VERSION ""

NS_ :

BS_:

BU_: BMU_ID_0 BMU_ID_1 BMU_ID_2 BMU_ID_3 BMU_ID_4 BMU_ID_5 BMU_ID_6 BMU_ID_7 BMU_ID_8 BMU_ID_9 BMU_ID_10 BMU_ID_11 BMU_ID_12 BMU_ID_13 BMU_ID_14 BMU_ID_15

BO_ 1365 wBMU_ID_5_msg_05_warnings: 8 BMU_ID_5
 SG_ System_errors : 0|1@1+ (1,0) [0|0] ""  BMU_ID_0
 SG_ Architecture_configuration_error : 1|1@1+ (1,0) [0|0] ""  BMU_ID_0
 SG_ Parallelization_voltage_errors : 2|1@1+ (1,0) [0|0] ""  BMU_ID_0
 SG_ General_configuration_errors : 3|1@1+ (1,0) [0|0] ""  BMU_ID_0
 SG_ Parallelization_comm_lost_primar : 4|1@1+ (1,0) [0|0] ""  BMU_ID_0
 SG_ Cell_overvoltage : 5|1@1+ (1,0) [0|0] ""  BMU_ID_0
 SG_ Cell_undervoltage : 6|1@1+ (1,0) [0|0] ""  BMU_ID_0
 SG_ Comm_failure_with_CMU : 7|1@1+ (1,0) [0|0] ""  BMU_ID_0
 SG_ Internal_CMU_error : 8|1@1+ (1,0) [0|0] ""  BMU_ID_0
 SG_ Internal_CMU_temperature_error : 9|1@1+ (1,0) [0|0] ""  BMU_ID_0
 SG_ Internal_CMU_voltage_reference : 10|1@1+ (1,0) [0|0] ""  BMU_ID_0
 SG_ Cell_shortcircuit : 11|1@1+ (1,0) [0|0] ""  BMU_ID_0
 SG_ Battery_overcurrent : 12|1@1+ (1,0) [0|0] ""  BMU_ID_0
 SG_ Overload_ratio_exceeded : 13|1@1+ (1,0) [0|0] ""  BMU_ID_0
 SG_ Current_sensor_errors : 14|1@1+ (1,0) [0|0] ""  BMU_ID_0
 SG_ BMU_temperature_errors : 15|1@1+ (1,0) [0|0] ""  BMU_ID_0
 SG_ Cell_overtemperature : 16|1@1+ (1,0) [0|0] ""  BMU_ID_0
 SG_ Cell_undertemperature : 17|1@1+ (1,0) [0|0] ""  BMU_ID_0
 SG_ Balancing_overtemperature : 18|1@1+ (1,0) [0|0] ""  BMU_ID_0
 SG_ Balancing_undertemperature : 19|1@1+ (1,0) [0|0] ""  BMU_ID_0
 SG_ Max_op_cell_temp_delta : 20|1@1+ (1,0) [0|0] ""  BMU_ID_0
 SG_ Thermal_runaway : 21|1@1+ (1,0) [0|0] ""  BMU_ID_0
 SG_ OW_and_SC_detected_on_cell : 22|1@1+ (1,0) [0|0] ""  BMU_ID_0
 SG_ BMU_external_overtemperature : 23|1@1+ (1,0) [0|0] ""  BMU_ID_0
 SG_ Battery_undervoltage : 24|1@1+ (1,0) [0|0] ""  BMU_ID_0
 SG_ BMU_supply_voltage_error : 25|1@1+ (1,0) [0|0] ""  BMU_ID_0
 SG_ Battery_overvoltage : 26|1@1+ (1,0) [0|0] ""  BMU_ID_0
 SG_ Cells_unbalanced : 27|1@1+ (1,0) [0|0] ""  BMU_ID_0
 SG_ Advanced_relaxation_voltage_delt : 28|1@1+ (1,0) [0|0] ""  BMU_ID_0
 SG_ Internal_BMU_error : 30|1@1+ (1,0) [0|0] ""  BMU_ID_0
 SG_ Safety_sensor_error : 31|1@1+ (1,0) [0|0] ""  BMU_ID_0
 SG_ High_voltage_sensor_errors : 32|1@1+ (1,0) [0|0] ""  BMU_ID_0
 SG_ IMD_errors : 33|1@1+ (1,0) [0|0] ""  BMU_ID_0
 SG_ Isolation_error : 34|1@1+ (1,0) [0|0] ""  BMU_ID_0
 SG_ BMU_SoC_errors : 35|1@1+ (1,0) [0|0] ""  BMU_ID_0
 SG_ BMU_SoH_error : 36|1@1+ (1,0) [0|0] ""  BMU_ID_0
 SG_ Contactor_stuck_open_errors : 37|1@1+ (1,0) [0|0] ""  BMU_ID_0
 SG_ Contactor_stuck_closed_errors : 38|1@1+ (1,0) [0|0] ""  BMU_ID_0
 SG_ Contactor_supply_error : 39|1@1+ (1,0) [0|0] ""  BMU_ID_0
 SG_ Contactor_precharge_error : 40|1@1+ (1,0) [0|0] ""  BMU_ID_0
 SG_ Emergency_button_error : 41|1@1+ (1,0) [0|0] ""  BMU_ID_0
 SG_ Actuation_errors : 42|1@1+ (1,0) [0|0] ""  BMU_ID_0
 SG_ Auto_OFF : 43|1@1+ (1,0) [0|0] ""  BMU_ID_0
 SG_ Mode_mismatch : 44|1@1+ (1,0) [0|0] ""  BMU_ID_0
 SG_ Open_wire_errors : 45|1@1+ (1,0) [0|0] ""  BMU_ID_0
 SG_ Output_driver_errors_diagnostics : 46|1@1+ (1,0) [0|0] ""  BMU_ID_0
 SG_ User_forced_errors : 47|1@1+ (1,0) [0|0] ""  BMU_ID_0
 SG_ SD_error : 48|1@1+ (1,0) [0|0] ""  BMU_ID_0
 SG_ Ethernet_module_error : 49|1@1+ (1,0) [0|0] ""  BMU_ID_0
 SG_ Internal_memory_errors : 29|1@1+ (1,0) [0|0] ""  BMU_ID_0

BO_ 1366 wBMU_ID_6_msg_05_warnings: 8 BMU_ID_6
 SG_ System_errors : 0|1@1+ (1,0) [0|0] ""  BMU_ID_0
 SG_ Architecture_configuration_error : 1|1@1+ (1,0) [0|0] ""  BMU_ID_0
 SG_ Parallelization_voltage_errors : 2|1@1+ (1,0) [0|0] ""  BMU_ID_0
 SG_ General_configuration_errors : 3|1@1+ (1,0) [0|0] ""  BMU_ID_0
 SG_ Parallelization_comm_lost_primar : 4|1@1+ (1,0) [0|0] ""  BMU_ID_0
 SG_ Cell_overvoltage : 5|1@1+ (1,0) [0|0] ""  BMU_ID_0
 SG_ Cell_undervoltage : 6|1@1+ (1,0) [0|0] ""  BMU_ID_0
 SG_ Comm_failure_with_CMU : 7|1@1+ (1,0) [0|0] ""  BMU_ID_0
 SG_ Internal_CMU_error : 8|1@1+ (1,0) [0|0] ""  BMU_ID_0
 SG_ Internal_CMU_temperature_error : 9|1@1+ (1,0) [0|0] ""  BMU_ID_0
 SG_ Internal_CMU_voltage_reference : 10|1@1+ (1,0) [0|0] ""  BMU_ID_0
 SG_ Cell_shortcircuit : 11|1@1+ (1,0) [0|0] ""  BMU_ID_0
 SG_ Battery_overcurrent : 12|1@1+ (1,0) [0|0] ""  BMU_ID_0
 SG_ Overload_ratio_exceeded : 13|1@1+ (1,0) [0|0] ""  BMU_ID_0
 SG_ Current_sensor_errors : 14|1@1+ (1,0) [0|0] ""  BMU_ID_0
 SG_ BMU_temperature_errors : 15|1@1+ (1,0) [0|0] ""  BMU_ID_0
 SG_ Cell_overtemperature : 16|1@1+ (1,0) [0|0] ""  BMU_ID_0
 SG_ Cell_undertemperature : 17|1@1+ (1,0) [0|0] ""  BMU_ID_0
 SG_ Balancing_overtemperature : 18|1@1+ (1,0) [0|0] ""  BMU_ID_0
 SG_ Balancing_undertemperature : 19|1@1+ (1,0) [0|0] ""  BMU_ID_0
 SG_ Max_op_cell_temp_delta : 20|1@1+ (1,0) [0|0] ""  BMU_ID_0
 SG_ Thermal_runaway : 21|1@1+ (1,0) [0|0] ""  BMU_ID_0
 SG_ OW_and_SC_detected_on_cell : 22|1@1+ (1,0) [0|0] ""  BMU_ID_0
 SG_ BMU_external_overtemperature : 23|1@1+ (1,0) [0|0] ""  BMU_ID_0
 SG_ Battery_undervoltage : 24|1@1+ (1,0) [0|0] ""  BMU_ID_0
 SG_ BMU_supply_voltage_error : 25|1@1+ (1,0) [0|0] ""  BMU_ID_0
 SG_ Battery_overvoltage : 26|1@1+ (1,0) [0|0] ""  BMU_ID_0
 SG_ Cells_unbalanced : 27|1@1+ (1,0) [0|0] ""  BMU_ID_0
 SG_ Advanced_relaxation_voltage_delt : 28|1@1+ (1,0) [0|0] ""  BMU_ID_0
 SG_ Internal_BMU_error : 30|1@1+ (1,0) [0|0] ""  BMU_ID_0
 SG_ Safety_sensor_error : 31|1@1+ (1,0) [0|0] ""  BMU_ID_0
 SG_ High_voltage_sensor_errors : 32|1@1+ (1,0) [0|0] ""  BMU_ID_0
 SG_ IMD_errors : 33|1@1+ (1,0) [0|0] ""  BMU_ID_0
 SG_ Isolation_error : 34|1@1+ (1,0) [0|0] ""  BMU_ID_0
 SG_ BMU_SoC_errors : 35|1@1+ (1,0) [0|0] ""  BMU_ID_0
 SG_ BMU_SoH_error : 36|1@1+ (1,0) [0|0] ""  BMU_ID_0
 SG_ Contactor_stuck_open_errors : 37|1@1+ (1,0) [0|0] ""  BMU_ID_0
 SG_ Contactor_stuck_closed_errors : 38|1@1+ (1,0) [0|0] ""  BMU_ID_0
 SG_ Contactor_supply_error : 39|1@1+ (1,0) [0|0] ""  BMU_ID_0
 SG_ Contactor_precharge_error : 40|1@1+ (1,0) [0|0] ""  BMU_ID_0
 SG_ Emergency_button_error : 41|1@1+ (1,0) [0|0] ""  BMU_ID_0
 SG_ Actuation_errors : 42|1@1+ (1,0) [0|0] ""  BMU_ID_0
 SG_ Auto_OFF : 43|1@1+ (1,0) [0|0] ""  BMU_ID_0
 SG_ Mode_mismatch : 44|1@1+ (1,0) [0|0] ""  BMU_ID_0
 SG_ Open_wire_errors : 45|1@1+ (1,0) [0|0] ""  BMU_ID_0
 SG_ Output_driver_errors_diagnostics : 46|1@1+ (1,0) [0|0] ""  BMU_ID_0
 SG_ User_forced_errors : 47|1@1+ (1,0) [0|0] ""  BMU_ID_0
 SG_ SD_error : 48|1@1+ (1,0) [0|0] ""  BMU_ID_0
 SG_ Ethernet_module_error : 49|1@1+ (1,0) [0|0] ""  BMU_ID_0
 SG_ Internal_memory_errors : 29|1@1+ (1,0) [0|0] ""  BMU_ID_0

BO_ 1367 wBMU_ID_7_msg_05_warnings: 8 BMU_ID_7
 SG_ System_errors : 0|1@1+ (1,0) [0|0] ""  BMU_ID_0
 SG_ Architecture_configuration_error : 1|1@1+ (1,0) [0|0] ""  BMU_ID_0
 SG_ Parallelization_voltage_errors : 2|1@1+ (1,0) [0|0] ""  BMU_ID_0
 SG_ General_configuration_errors : 3|1@1+ (1,0) [0|0] ""  BMU_ID_0
 SG_ Parallelization_comm_lost_primar : 4|1@1+ (1,0) [0|0] ""  BMU_ID_0
 SG_ Cell_overvoltage : 5|1@1+ (1,0) [0|0] ""  BMU_ID_0
 SG_ Cell_undervoltage : 6|1@1+ (1,0) [0|0] ""  BMU_ID_0
 SG_ Comm_failure_with_CMU : 7|1@1+ (1,0) [0|0] ""  BMU_ID_0
 SG_ Internal_CMU_error : 8|1@1+ (1,0) [0|0] ""  BMU_ID_0
 SG_ Internal_CMU_temperature_error : 9|1@1+ (1,0) [0|0] ""  BMU_ID_0
 SG_ Internal_CMU_voltage_reference : 10|1@1+ (1,0) [0|0] ""  BMU_ID_0
 SG_ Cell_shortcircuit : 11|1@1+ (1,0) [0|0] ""  BMU_ID_0
 SG_ Battery_overcurrent : 12|1@1+ (1,0) [0|0] ""  BMU_ID_0
 SG_ Overload_ratio_exceeded : 13|1@1+ (1,0) [0|0] ""  BMU_ID_0
 SG_ Current_sensor_errors : 14|1@1+ (1,0) [0|0] ""  BMU_ID_0
 SG_ BMU_temperature_errors : 15|1@1+ (1,0) [0|0] ""  BMU_ID_0
 SG_ Cell_overtemperature : 16|1@1+ (1,0) [0|0] ""  BMU_ID_0
 SG_ Cell_undertemperature : 17|1@1+ (1,0) [0|0] ""  BMU_ID_0
 SG_ Balancing_overtemperature : 18|1@1+ (1,0) [0|0] ""  BMU_ID_0
 SG_ Balancing_undertemperature : 19|1@1+ (1,0) [0|0] ""  BMU_ID_0
 SG_ Max_op_cell_temp_delta : 20|1@1+ (1,0) [0|0] ""  BMU_ID_0
 SG_ Thermal_runaway : 21|1@1+ (1,0) [0|0] ""  BMU_ID_0
 SG_ OW_and_SC_detected_on_cell : 22|1@1+ (1,0) [0|0] ""  BMU_ID_0
 SG_ BMU_external_overtemperature : 23|1@1+ (1,0) [0|0] ""  BMU_ID_0
 SG_ Battery_undervoltage : 24|1@1+ (1,0) [0|0] ""  BMU_ID_0
 SG_ BMU_supply_voltage_error : 25|1@1+ (1,0) [0|0] ""  BMU_ID_0
 SG_ Battery_overvoltage : 26|1@1+ (1,0) [0|0] ""  BMU_ID_0
 SG_ Cells_unbalanced : 27|1@1+ (1,0) [0|0] ""  BMU_ID_0
 SG_ Advanced_relaxation_voltage_delt : 28|1@1+ (1,0) [0|0] ""  BMU_ID_0
 SG_ Internal_BMU_error : 30|1@1+ (1,0) [0|0] ""  BMU_ID_0
 SG_ Safety_sensor_error : 31|1@1+ (1,0) [0|0] ""  BMU_ID_0
 SG_ High_voltage_sensor_errors : 32|1@1+ (1,0) [0|0] ""  BMU_ID_0
 SG_ IMD_errors : 33|1@1+ (1,0) [0|0] ""  BMU_ID_0
 SG_ Isolation_error : 34|1@1+ (1,0) [0|0] ""  BMU_ID_0
 SG_ BMU_SoC_errors : 35|1@1+ (1,0) [0|0] ""  BMU_ID_0
 SG_ BMU_SoH_error : 36|1@1+ (1,0) [0|0] ""  BMU_ID_0
 SG_ Contactor_stuck_open_errors : 37|1@1+ (1,0) [0|0] ""  BMU_ID_0
 SG_ Contactor_stuck_closed_errors : 38|1@1+ (1,0) [0|0] ""  BMU_ID_0
 SG_ Contactor_supply_error : 39|1@1+ (1,0) [0|0] ""  BMU_ID_0
 SG_ Contactor_precharge_error : 40|1@1+ (1,0) [0|0] ""  BMU_ID_0
 SG_ Emergency_button_error : 41|1@1+ (1,0) [0|0] ""  BMU_ID_0
 SG_ Actuation_errors : 42|1@1+ (1,0) [0|0] ""  BMU_ID_0
 SG_ Auto_OFF : 43|1@1+ (1,0) [0|0] ""  BMU_ID_0
 SG_ Mode_mismatch : 44|1@1+ (1,0) [0|0] ""  BMU_ID_0
 SG_ Open_wire_errors : 45|1@1+ (1,0) [0|0] ""  BMU_ID_0
 SG_ Output_driver_errors_diagnostics : 46|1@1+ (1,0) [0|0] ""  BMU_ID_0
 SG_ User_forced_errors : 47|1@1+ (1,0) [0|0] ""  BMU_ID_0
 SG_ SD_error : 48|1@1+ (1,0) [0|0] ""  BMU_ID_0
 SG_ Ethernet_module_error : 49|1@1+ (1,0) [0|0] ""  BMU_ID_0
 SG_ Internal_memory_errors : 29|1@1+ (1,0) [0|0] ""  BMU_ID_0

BO_ 1368 wBMU_ID_8_msg_05_warnings: 8 BMU_ID_8
 SG_ System_errors : 0|1@1+ (1,0) [0|0] ""  BMU_ID_0
 SG_ Architecture_configuration_error : 1|1@1+ (1,0) [0|0] ""  BMU_ID_0
 SG_ Parallelization_voltage_errors : 2|1@1+ (1,0) [0|0] ""  BMU_ID_0
 SG_ General_configuration_errors : 3|1@1+ (1,0) [0|0] ""  BMU_ID_0
 SG_ Parallelization_comm_lost_primar : 4|1@1+ (1,0) [0|0] ""  BMU_ID_0
 SG_ Cell_overvoltage : 5|1@1+ (1,0) [0|0] ""  BMU_ID_0
 SG_ Cell_undervoltage : 6|1@1+ (1,0) [0|0] ""  BMU_ID_0
 SG_ Comm_failure_with_CMU : 7|1@1+ (1,0) [0|0] ""  BMU_ID_0
 SG_ Internal_CMU_error : 8|1@1+ (1,0) [0|0] ""  BMU_ID_0
 SG_ Internal_CMU_temperature_error : 9|1@1+ (1,0) [0|0] ""  BMU_ID_0
 SG_ Internal_CMU_voltage_reference : 10|1@1+ (1,0) [0|0] ""  BMU_ID_0
 SG_ Cell_shortcircuit : 11|1@1+ (1,0) [0|0] ""  BMU_ID_0
 SG_ Battery_overcurrent : 12|1@1+ (1,0) [0|0] ""  BMU_ID_0
 SG_ Overload_ratio_exceeded : 13|1@1+ (1,0) [0|0] ""  BMU_ID_0
 SG_ Current_sensor_errors : 14|1@1+ (1,0) [0|0] ""  BMU_ID_0
 SG_ BMU_temperature_errors : 15|1@1+ (1,0) [0|0] ""  BMU_ID_0
 SG_ Cell_overtemperature : 16|1@1+ (1,0) [0|0] ""  BMU_ID_0
 SG_ Cell_undertemperature : 17|1@1+ (1,0) [0|0] ""  BMU_ID_0
 SG_ Balancing_overtemperature : 18|1@1+ (1,0) [0|0] ""  BMU_ID_0
 SG_ Balancing_undertemperature : 19|1@1+ (1,0) [0|0] ""  BMU_ID_0
 SG_ Max_op_cell_temp_delta : 20|1@1+ (1,0) [0|0] ""  BMU_ID_0
 SG_ Thermal_runaway : 21|1@1+ (1,0) [0|0] ""  BMU_ID_0
 SG_ OW_and_SC_detected_on_cell : 22|1@1+ (1,0) [0|0] ""  BMU_ID_0
 SG_ BMU_external_overtemperature : 23|1@1+ (1,0) [0|0] ""  BMU_ID_0
 SG_ Battery_undervoltage : 24|1@1+ (1,0) [0|0] ""  BMU_ID_0
 SG_ BMU_supply_voltage_error : 25|1@1+ (1,0) [0|0] ""  BMU_ID_0
 SG_ Battery_overvoltage : 26|1@1+ (1,0) [0|0] ""  BMU_ID_0
 SG_ Cells_unbalanced : 27|1@1+ (1,0) [0|0] ""  BMU_ID_0
 SG_ Advanced_relaxation_voltage_delt : 28|1@1+ (1,0) [0|0] ""  BMU_ID_0
 SG_ Internal_BMU_error : 30|1@1+ (1,0) [0|0] ""  BMU_ID_0
 SG_ Safety_sensor_error : 31|1@1+ (1,0) [0|0] ""  BMU_ID_0
 SG_ High_voltage_sensor_errors : 32|1@1+ (1,0) [0|0] ""  BMU_ID_0
 SG_ IMD_errors : 33|1@1+ (1,0) [0|0] ""  BMU_ID_0
 SG_ Isolation_error : 34|1@1+ (1,0) [0|0] ""  BMU_ID_0
 SG_ BMU_SoC_errors : 35|1@1+ (1,0) [0|0] ""  BMU_ID_0
 SG_ BMU_SoH_error : 36|1@1+ (1,0) [0|0] ""  BMU_ID_0
 SG_ Contactor_stuck_open_errors : 37|1@1+ (1,0) [0|0] ""  BMU_ID_0
 SG_ Contactor_stuck_closed_errors : 38|1@1+ (1,0) [0|0] ""  BMU_ID_0
 SG_ Contactor_supply_error : 39|1@1+ (1,0) [0|0] ""  BMU_ID_0
 SG_ Contactor_precharge_error : 40|1@1+ (1,0) [0|0] ""  BMU_ID_0
 SG_ Emergency_button_error : 41|1@1+ (1,0) [0|0] ""  BMU_ID_0
 SG_ Actuation_errors : 42|1@1+ (1,0) [0|0] ""  BMU_ID_0
 SG_ Auto_OFF : 43|1@1+ (1,0) [0|0] ""  BMU_ID_0
 SG_ Mode_mismatch : 44|1@1+ (1,0) [0|0] ""  BMU_ID_0
 SG_ Open_wire_errors : 45|1@1+ (1,0) [0|0] ""  BMU_ID_0
 SG_ Output_driver_errors_diagnostics : 46|1@1+ (1,0) [0|0] ""  BMU_ID_0
 SG_ User_forced_errors : 47|1@1+ (1,0) [0|0] ""  BMU_ID_0
 SG_ SD_error : 48|1@1+ (1,0) [0|0] ""  BMU_ID_0
 SG_ Ethernet_module_error : 49|1@1+ (1,0) [0|0] ""  BMU_ID_0
 SG_ Internal_memory_errors : 29|1@1+ (1,0) [0|0] ""  BMU_ID_0

BO_ 1369 wBMU_ID_9_msg_05_warnings: 8 BMU_ID_9
 SG_ System_errors : 0|1@1+ (1,0) [0|0] ""  BMU_ID_0
 SG_ Architecture_configuration_error : 1|1@1+ (1,0) [0|0] ""  BMU_ID_0
 SG_ Parallelization_voltage_errors : 2|1@1+ (1,0) [0|0] ""  BMU_ID_0
 SG_ General_configuration_errors : 3|1@1+ (1,0) [0|0] ""  BMU_ID_0
 SG_ Parallelization_comm_lost_primar : 4|1@1+ (1,0) [0|0] ""  BMU_ID_0
 SG_ Cell_overvoltage : 5|1@1+ (1,0) [0|0] ""  BMU_ID_0
 SG_ Cell_undervoltage : 6|1@1+ (1,0) [0|0] ""  BMU_ID_0
 SG_ Comm_failure_with_CMU : 7|1@1+ (1,0) [0|0] ""  BMU_ID_0
 SG_ Internal_CMU_error : 8|1@1+ (1,0) [0|0] ""  BMU_ID_0
 SG_ Internal_CMU_temperature_error : 9|1@1+ (1,0) [0|0] ""  BMU_ID_0
 SG_ Internal_CMU_voltage_reference : 10|1@1+ (1,0) [0|0] ""  BMU_ID_0
 SG_ Cell_shortcircuit : 11|1@1+ (1,0) [0|0] ""  BMU_ID_0
 SG_ Battery_overcurrent : 12|1@1+ (1,0) [0|0] ""  BMU_ID_0
 SG_ Overload_ratio_exceeded : 13|1@1+ (1,0) [0|0] ""  BMU_ID_0
 SG_ Current_sensor_errors : 14|1@1+ (1,0) [0|0] ""  BMU_ID_0
 SG_ BMU_temperature_errors : 15|1@1+ (1,0) [0|0] ""  BMU_ID_0
 SG_ Cell_overtemperature : 16|1@1+ (1,0) [0|0] ""  BMU_ID_0
 SG_ Cell_undertemperature : 17|1@1+ (1,0) [0|0] ""  BMU_ID_0
 SG_ Balancing_overtemperature : 18|1@1+ (1,0) [0|0] ""  BMU_ID_0
 SG_ Balancing_undertemperature : 19|1@1+ (1,0) [0|0] ""  BMU_ID_0
 SG_ Max_op_cell_temp_delta : 20|1@1+ (1,0) [0|0] ""  BMU_ID_0
 SG_ Thermal_runaway : 21|1@1+ (1,0) [0|0] ""  BMU_ID_0
 SG_ OW_and_SC_detected_on_cell : 22|1@1+ (1,0) [0|0] ""  BMU_ID_0
 SG_ BMU_external_overtemperature : 23|1@1+ (1,0) [0|0] ""  BMU_ID_0
 SG_ Battery_undervoltage : 24|1@1+ (1,0) [0|0] ""  BMU_ID_0
 SG_ BMU_supply_voltage_error : 25|1@1+ (1,0) [0|0] ""  BMU_ID_0
 SG_ Battery_overvoltage : 26|1@1+ (1,0) [0|0] ""  BMU_ID_0
 SG_ Cells_unbalanced : 27|1@1+ (1,0) [0|0] ""  BMU_ID_0
 SG_ Advanced_relaxation_voltage_delt : 28|1@1+ (1,0) [0|0] ""  BMU_ID_0
 SG_ Internal_BMU_error : 30|1@1+ (1,0) [0|0] ""  BMU_ID_0
 SG_ Safety_sensor_error : 31|1@1+ (1,0) [0|0] ""  BMU_ID_0
 SG_ High_voltage_sensor_errors : 32|1@1+ (1,0) [0|0] ""  BMU_ID_0
 SG_ IMD_errors : 33|1@1+ (1,0) [0|0] ""  BMU_ID_0
 SG_ Isolation_error : 34|1@1+ (1,0) [0|0] ""  BMU_ID_0
 SG_ BMU_SoC_errors : 35|1@1+ (1,0) [0|0] ""  BMU_ID_0
 SG_ BMU_SoH_error : 36|1@1+ (1,0) [0|0] ""  BMU_ID_0
 SG_ Contactor_stuck_open_errors : 37|1@1+ (1,0) [0|0] ""  BMU_ID_0
 SG_ Contactor_stuck_closed_errors : 38|1@1+ (1,0) [0|0] ""  BMU_ID_0
 SG_ Contactor_supply_error : 39|1@1+ (1,0) [0|0] ""  BMU_ID_0
 SG_ Contactor_precharge_error : 40|1@1+ (1,0) [0|0] ""  BMU_ID_0
 SG_ Emergency_button_error : 41|1@1+ (1,0) [0|0] ""  BMU_ID_0
 SG_ Actuation_errors : 42|1@1+ (1,0) [0|0] ""  BMU_ID_0
 SG_ Auto_OFF : 43|1@1+ (1,0) [0|0] ""  BMU_ID_0
 SG_ Mode_mismatch : 44|1@1+ (1,0) [0|0] ""  BMU_ID_0
 SG_ Open_wire_errors : 45|1@1+ (1,0) [0|0] ""  BMU_ID_0
 SG_ Output_driver_errors_diagnostics : 46|1@1+ (1,0) [0|0] ""  BMU_ID_0
 SG_ User_forced_errors : 47|1@1+ (1,0) [0|0] ""  BMU_ID_0
 SG_ SD_error : 48|1@1+ (1,0) [0|0] ""  BMU_ID_0
 SG_ Ethernet_module_error : 49|1@1+ (1,0) [0|0] ""  BMU_ID_0
 SG_ Internal_memory_errors : 29|1@1+ (1,0) [0|0] ""  BMU_ID_0

BO_ 1370 wBMU_ID_10_msg_05_warnings: 8 BMU_ID_10
 SG_ System_errors : 0|1@1+ (1,0) [0|0] ""  BMU_ID_0
 SG_ Architecture_configuration_error : 1|1@1+ (1,0) [0|0] ""  BMU_ID_0
 SG_ Parallelization_voltage_errors : 2|1@1+ (1,0) [0|0] ""  BMU_ID_0
 SG_ General_configuration_errors : 3|1@1+ (1,0) [0|0] ""  BMU_ID_0
 SG_ Parallelization_comm_lost_primar : 4|1@1+ (1,0) [0|0] ""  BMU_ID_0
 SG_ Cell_overvoltage : 5|1@1+ (1,0) [0|0] ""  BMU_ID_0
 SG_ Cell_undervoltage : 6|1@1+ (1,0) [0|0] ""  BMU_ID_0
 SG_ Comm_failure_with_CMU : 7|1@1+ (1,0) [0|0] ""  BMU_ID_0
 SG_ Internal_CMU_error : 8|1@1+ (1,0) [0|0] ""  BMU_ID_0
 SG_ Internal_CMU_temperature_error : 9|1@1+ (1,0) [0|0] ""  BMU_ID_0
 SG_ Internal_CMU_voltage_reference : 10|1@1+ (1,0) [0|0] ""  BMU_ID_0
 SG_ Cell_shortcircuit : 11|1@1+ (1,0) [0|0] ""  BMU_ID_0
 SG_ Battery_overcurrent : 12|1@1+ (1,0) [0|0] ""  BMU_ID_0
 SG_ Overload_ratio_exceeded : 13|1@1+ (1,0) [0|0] ""  BMU_ID_0
 SG_ Current_sensor_errors : 14|1@1+ (1,0) [0|0] ""  BMU_ID_0
 SG_ BMU_temperature_errors : 15|1@1+ (1,0) [0|0] ""  BMU_ID_0
 SG_ Cell_overtemperature : 16|1@1+ (1,0) [0|0] ""  BMU_ID_0
 SG_ Cell_undertemperature : 17|1@1+ (1,0) [0|0] ""  BMU_ID_0
 SG_ Balancing_overtemperature : 18|1@1+ (1,0) [0|0] ""  BMU_ID_0
 SG_ Balancing_undertemperature : 19|1@1+ (1,0) [0|0] ""  BMU_ID_0
 SG_ Max_op_cell_temp_delta : 20|1@1+ (1,0) [0|0] ""  BMU_ID_0
 SG_ Thermal_runaway : 21|1@1+ (1,0) [0|0] ""  BMU_ID_0
 SG_ OW_and_SC_detected_on_cell : 22|1@1+ (1,0) [0|0] ""  BMU_ID_0
 SG_ BMU_external_overtemperature : 23|1@1+ (1,0) [0|0] ""  BMU_ID_0
 SG_ Battery_undervoltage : 24|1@1+ (1,0) [0|0] ""  BMU_ID_0
 SG_ BMU_supply_voltage_error : 25|1@1+ (1,0) [0|0] ""  BMU_ID_0
 SG_ Battery_overvoltage : 26|1@1+ (1,0) [0|0] ""  BMU_ID_0
 SG_ Cells_unbalanced : 27|1@1+ (1,0) [0|0] ""  BMU_ID_0
 SG_ Advanced_relaxation_voltage_delt : 28|1@1+ (1,0) [0|0] ""  BMU_ID_0
 SG_ Internal_BMU_error : 30|1@1+ (1,0) [0|0] ""  BMU_ID_0
 SG_ Safety_sensor_error : 31|1@1+ (1,0) [0|0] ""  BMU_ID_0
 SG_ High_voltage_sensor_errors : 32|1@1+ (1,0) [0|0] ""  BMU_ID_0
 SG_ IMD_errors : 33|1@1+ (1,0) [0|0] ""  BMU_ID_0
 SG_ Isolation_error : 34|1@1+ (1,0) [0|0] ""  BMU_ID_0
 SG_ BMU_SoC_errors : 35|1@1+ (1,0) [0|0] ""  BMU_ID_0
 SG_ BMU_SoH_error : 36|1@1+ (1,0) [0|0] ""  BMU_ID_0
 SG_ Contactor_stuck_open_errors : 37|1@1+ (1,0) [0|0] ""  BMU_ID_0
 SG_ Contactor_stuck_closed_errors : 38|1@1+ (1,0) [0|0] ""  BMU_ID_0
 SG_ Contactor_supply_error : 39|1@1+ (1,0) [0|0] ""  BMU_ID_0
 SG_ Contactor_precharge_error : 40|1@1+ (1,0) [0|0] ""  BMU_ID_0
 SG_ Emergency_button_error : 41|1@1+ (1,0) [0|0] ""  BMU_ID_0
 SG_ Actuation_errors : 42|1@1+ (1,0) [0|0] ""  BMU_ID_0
 SG_ Auto_OFF : 43|1@1+ (1,0) [0|0] ""  BMU_ID_0
 SG_ Mode_mismatch : 44|1@1+ (1,0) [0|0] ""  BMU_ID_0
 SG_ Open_wire_errors : 45|1@1+ (1,0) [0|0] ""  BMU_ID_0
 SG_ Output_driver_errors_diagnostics : 46|1@1+ (1,0) [0|0] ""  BMU_ID_0
 SG_ User_forced_errors : 47|1@1+ (1,0) [0|0] ""  BMU_ID_0
 SG_ SD_error : 48|1@1+ (1,0) [0|0] ""  BMU_ID_0
 SG_ Ethernet_module_error : 49|1@1+ (1,0) [0|0] ""  BMU_ID_0
 SG_ Internal_memory_errors : 29|1@1+ (1,0) [0|0] ""  BMU_ID_0

BO_ 1371 wBMU_ID_11_msg_05_warnings: 8 BMU_ID_11
 SG_ System_errors : 0|1@1+ (1,0) [0|0] ""  BMU_ID_0
 SG_ Architecture_configuration_error : 1|1@1+ (1,0) [0|0] ""  BMU_ID_0
 SG_ Parallelization_voltage_errors : 2|1@1+ (1,0) [0|0] ""  BMU_ID_0
 SG_ General_configuration_errors : 3|1@1+ (1,0) [0|0] ""  BMU_ID_0
 SG_ Parallelization_comm_lost_primar : 4|1@1+ (1,0) [0|0] ""  BMU_ID_0
 SG_ Cell_overvoltage : 5|1@1+ (1,0) [0|0] ""  BMU_ID_0
 SG_ Cell_undervoltage : 6|1@1+ (1,0) [0|0] ""  BMU_ID_0
 SG_ Comm_failure_with_CMU : 7|1@1+ (1,0) [0|0] ""  BMU_ID_0
 SG_ Internal_CMU_error : 8|1@1+ (1,0) [0|0] ""  BMU_ID_0
 SG_ Internal_CMU_temperature_error : 9|1@1+ (1,0) [0|0] ""  BMU_ID_0
 SG_ Internal_CMU_voltage_reference : 10|1@1+ (1,0) [0|0] ""  BMU_ID_0
 SG_ Cell_shortcircuit : 11|1@1+ (1,0) [0|0] ""  BMU_ID_0
 SG_ Battery_overcurrent : 12|1@1+ (1,0) [0|0] ""  BMU_ID_0
 SG_ Overload_ratio_exceeded : 13|1@1+ (1,0) [0|0] ""  BMU_ID_0
 SG_ Current_sensor_errors : 14|1@1+ (1,0) [0|0] ""  BMU_ID_0
 SG_ BMU_temperature_errors : 15|1@1+ (1,0) [0|0] ""  BMU_ID_0
 SG_ Cell_overtemperature : 16|1@1+ (1,0) [0|0] ""  BMU_ID_0
 SG_ Cell_undertemperature : 17|1@1+ (1,0) [0|0] ""  BMU_ID_0
 SG_ Balancing_overtemperature : 18|1@1+ (1,0) [0|0] ""  BMU_ID_0
 SG_ Balancing_undertemperature : 19|1@1+ (1,0) [0|0] ""  BMU_ID_0
 SG_ Max_op_cell_temp_delta : 20|1@1+ (1,0) [0|0] ""  BMU_ID_0
 SG_ Thermal_runaway : 21|1@1+ (1,0) [0|0] ""  BMU_ID_0
 SG_ OW_and_SC_detected_on_cell : 22|1@1+ (1,0) [0|0] ""  BMU_ID_0
 SG_ BMU_external_overtemperature : 23|1@1+ (1,0) [0|0] ""  BMU_ID_0
 SG_ Battery_undervoltage : 24|1@1+ (1,0) [0|0] ""  BMU_ID_0
 SG_ BMU_supply_voltage_error : 25|1@1+ (1,0) [0|0] ""  BMU_ID_0
 SG_ Battery_overvoltage : 26|1@1+ (1,0) [0|0] ""  BMU_ID_0
 SG_ Cells_unbalanced : 27|1@1+ (1,0) [0|0] ""  BMU_ID_0
 SG_ Advanced_relaxation_voltage_delt : 28|1@1+ (1,0) [0|0] ""  BMU_ID_0
 SG_ Internal_BMU_error : 30|1@1+ (1,0) [0|0] ""  BMU_ID_0
 SG_ Safety_sensor_error : 31|1@1+ (1,0) [0|0] ""  BMU_ID_0
 SG_ High_voltage_sensor_errors : 32|1@1+ (1,0) [0|0] ""  BMU_ID_0
 SG_ IMD_errors : 33|1@1+ (1,0) [0|0] ""  BMU_ID_0
 SG_ Isolation_error : 34|1@1+ (1,0) [0|0] ""  BMU_ID_0
 SG_ BMU_SoC_errors : 35|1@1+ (1,0) [0|0] ""  BMU_ID_0
 SG_ BMU_SoH_error : 36|1@1+ (1,0) [0|0] ""  BMU_ID_0
 SG_ Contactor_stuck_open_errors : 37|1@1+ (1,0) [0|0] ""  BMU_ID_0
 SG_ Contactor_stuck_closed_errors : 38|1@1+ (1,0) [0|0] ""  BMU_ID_0
 SG_ Contactor_supply_error : 39|1@1+ (1,0) [0|0] ""  BMU_ID_0
 SG_ Contactor_precharge_error : 40|1@1+ (1,0) [0|0] ""  BMU_ID_0
 SG_ Emergency_button_error : 41|1@1+ (1,0) [0|0] ""  BMU_ID_0
 SG_ Actuation_errors : 42|1@1+ (1,0) [0|0] ""  BMU_ID_0
 SG_ Auto_OFF : 43|1@1+ (1,0) [0|0] ""  BMU_ID_0
 SG_ Mode_mismatch : 44|1@1+ (1,0) [0|0] ""  BMU_ID_0
 SG_ Open_wire_errors : 45|1@1+ (1,0) [0|0] ""  BMU_ID_0
 SG_ Output_driver_errors_diagnostics : 46|1@1+ (1,0) [0|0] ""  BMU_ID_0
 SG_ User_forced_errors : 47|1@1+ (1,0) [0|0] ""  BMU_ID_0
 SG_ SD_error : 48|1@1+ (1,0) [0|0] ""  BMU_ID_0
 SG_ Ethernet_module_error : 49|1@1+ (1,0) [0|0] ""  BMU_ID_0
 SG_ Internal_memory_errors : 29|1@1+ (1,0) [0|0] ""  BMU_ID_0

BO_ 1372 wBMU_ID_12_msg_05_warnings: 8 BMU_ID_12
 SG_ System_errors : 0|1@1+ (1,0) [0|0] ""  BMU_ID_0
 SG_ Architecture_configuration_error : 1|1@1+ (1,0) [0|0] ""  BMU_ID_0
 SG_ Parallelization_voltage_errors : 2|1@1+ (1,0) [0|0] ""  BMU_ID_0
 SG_ General_configuration_errors : 3|1@1+ (1,0) [0|0] ""  BMU_ID_0
 SG_ Parallelization_comm_lost_primar : 4|1@1+ (1,0) [0|0] ""  BMU_ID_0
 SG_ Cell_overvoltage : 5|1@1+ (1,0) [0|0] ""  BMU_ID_0
 SG_ Cell_undervoltage : 6|1@1+ (1,0) [0|0] ""  BMU_ID_0
 SG_ Comm_failure_with_CMU : 7|1@1+ (1,0) [0|0] ""  BMU_ID_0
 SG_ Internal_CMU_error : 8|1@1+ (1,0) [0|0] ""  BMU_ID_0
 SG_ Internal_CMU_temperature_error : 9|1@1+ (1,0) [0|0] ""  BMU_ID_0
 SG_ Internal_CMU_voltage_reference : 10|1@1+ (1,0) [0|0] ""  BMU_ID_0
 SG_ Cell_shortcircuit : 11|1@1+ (1,0) [0|0] ""  BMU_ID_0
 SG_ Battery_overcurrent : 12|1@1+ (1,0) [0|0] ""  BMU_ID_0
 SG_ Overload_ratio_exceeded : 13|1@1+ (1,0) [0|0] ""  BMU_ID_0
 SG_ Current_sensor_errors : 14|1@1+ (1,0) [0|0] ""  BMU_ID_0
 SG_ BMU_temperature_errors : 15|1@1+ (1,0) [0|0] ""  BMU_ID_0
 SG_ Cell_overtemperature : 16|1@1+ (1,0) [0|0] ""  BMU_ID_0
 SG_ Cell_undertemperature : 17|1@1+ (1,0) [0|0] ""  BMU_ID_0
 SG_ Balancing_overtemperature : 18|1@1+ (1,0) [0|0] ""  BMU_ID_0
 SG_ Balancing_undertemperature : 19|1@1+ (1,0) [0|0] ""  BMU_ID_0
 SG_ Max_op_cell_temp_delta : 20|1@1+ (1,0) [0|0] ""  BMU_ID_0
 SG_ Thermal_runaway : 21|1@1+ (1,0) [0|0] ""  BMU_ID_0
 SG_ OW_and_SC_detected_on_cell : 22|1@1+ (1,0) [0|0] ""  BMU_ID_0
 SG_ BMU_external_overtemperature : 23|1@1+ (1,0) [0|0] ""  BMU_ID_0
 SG_ Battery_undervoltage : 24|1@1+ (1,0) [0|0] ""  BMU_ID_0
 SG_ BMU_supply_voltage_error : 25|1@1+ (1,0) [0|0] ""  BMU_ID_0
 SG_ Battery_overvoltage : 26|1@1+ (1,0) [0|0] ""  BMU_ID_0
 SG_ Cells_unbalanced : 27|1@1+ (1,0) [0|0] ""  BMU_ID_0
 SG_ Advanced_relaxation_voltage_delt : 28|1@1+ (1,0) [0|0] ""  BMU_ID_0
 SG_ Internal_BMU_error : 30|1@1+ (1,0) [0|0] ""  BMU_ID_0
 SG_ Safety_sensor_error : 31|1@1+ (1,0) [0|0] ""  BMU_ID_0
 SG_ High_voltage_sensor_errors : 32|1@1+ (1,0) [0|0] ""  BMU_ID_0
 SG_ IMD_errors : 33|1@1+ (1,0) [0|0] ""  BMU_ID_0
 SG_ Isolation_error : 34|1@1+ (1,0) [0|0] ""  BMU_ID_0
 SG_ BMU_SoC_errors : 35|1@1+ (1,0) [0|0] ""  BMU_ID_0
 SG_ BMU_SoH_error : 36|1@1+ (1,0) [0|0] ""  BMU_ID_0
 SG_ Contactor_stuck_open_errors : 37|1@1+ (1,0) [0|0] ""  BMU_ID_0
 SG_ Contactor_stuck_closed_errors : 38|1@1+ (1,0) [0|0] ""  BMU_ID_0
 SG_ Contactor_supply_error : 39|1@1+ (1,0) [0|0] ""  BMU_ID_0
 SG_ Contactor_precharge_error : 40|1@1+ (1,0) [0|0] ""  BMU_ID_0
 SG_ Emergency_button_error : 41|1@1+ (1,0) [0|0] ""  BMU_ID_0
 SG_ Actuation_errors : 42|1@1+ (1,0) [0|0] ""  BMU_ID_0
 SG_ Auto_OFF : 43|1@1+ (1,0) [0|0] ""  BMU_ID_0
 SG_ Mode_mismatch : 44|1@1+ (1,0) [0|0] ""  BMU_ID_0
 SG_ Open_wire_errors : 45|1@1+ (1,0) [0|0] ""  BMU_ID_0
 SG_ Output_driver_errors_diagnostics : 46|1@1+ (1,0) [0|0] ""  BMU_ID_0
 SG_ User_forced_errors : 47|1@1+ (1,0) [0|0] ""  BMU_ID_0
 SG_ SD_error : 48|1@1+ (1,0) [0|0] ""  BMU_ID_0
 SG_ Ethernet_module_error : 49|1@1+ (1,0) [0|0] ""  BMU_ID_0
 SG_ Internal_memory_errors : 29|1@1+ (1,0) [0|0] ""  BMU_ID_0

BO_ 1373 wBMU_ID_13_msg_05_warnings: 8 BMU_ID_13
 SG_ System_errors : 0|1@1+ (1,0) [0|0] ""  BMU_ID_0
 SG_ Architecture_configuration_error : 1|1@1+ (1,0) [0|0] ""  BMU_ID_0
 SG_ Parallelization_voltage_errors : 2|1@1+ (1,0) [0|0] ""  BMU_ID_0
 SG_ General_configuration_errors : 3|1@1+ (1,0) [0|0] ""  BMU_ID_0
 SG_ Parallelization_comm_lost_primar : 4|1@1+ (1,0) [0|0] ""  BMU_ID_0
 SG_ Cell_overvoltage : 5|1@1+ (1,0) [0|0] ""  BMU_ID_0
 SG_ Cell_undervoltage : 6|1@1+ (1,0) [0|0] ""  BMU_ID_0
 SG_ Comm_failure_with_CMU : 7|1@1+ (1,0) [0|0] ""  BMU_ID_0
 SG_ Internal_CMU_error : 8|1@1+ (1,0) [0|0] ""  BMU_ID_0
 SG_ Internal_CMU_temperature_error : 9|1@1+ (1,0) [0|0] ""  BMU_ID_0
 SG_ Internal_CMU_voltage_reference : 10|1@1+ (1,0) [0|0] ""  BMU_ID_0
 SG_ Cell_shortcircuit : 11|1@1+ (1,0) [0|0] ""  BMU_ID_0
 SG_ Battery_overcurrent : 12|1@1+ (1,0) [0|0] ""  BMU_ID_0
 SG_ Overload_ratio_exceeded : 13|1@1+ (1,0) [0|0] ""  BMU_ID_0
 SG_ Current_sensor_errors : 14|1@1+ (1,0) [0|0] ""  BMU_ID_0
 SG_ BMU_temperature_errors : 15|1@1+ (1,0) [0|0] ""  BMU_ID_0
 SG_ Cell_overtemperature : 16|1@1+ (1,0) [0|0] ""  BMU_ID_0
 SG_ Cell_undertemperature : 17|1@1+ (1,0) [0|0] ""  BMU_ID_0
 SG_ Balancing_overtemperature : 18|1@1+ (1,0) [0|0] ""  BMU_ID_0
 SG_ Balancing_undertemperature : 19|1@1+ (1,0) [0|0] ""  BMU_ID_0
 SG_ Max_op_cell_temp_delta : 20|1@1+ (1,0) [0|0] ""  BMU_ID_0
 SG_ Thermal_runaway : 21|1@1+ (1,0) [0|0] ""  BMU_ID_0
 SG_ OW_and_SC_detected_on_cell : 22|1@1+ (1,0) [0|0] ""  BMU_ID_0
 SG_ BMU_external_overtemperature : 23|1@1+ (1,0) [0|0] ""  BMU_ID_0
 SG_ Battery_undervoltage : 24|1@1+ (1,0) [0|0] ""  BMU_ID_0
 SG_ BMU_supply_voltage_error : 25|1@1+ (1,0) [0|0] ""  BMU_ID_0
 SG_ Battery_overvoltage : 26|1@1+ (1,0) [0|0] ""  BMU_ID_0
 SG_ Cells_unbalanced : 27|1@1+ (1,0) [0|0] ""  BMU_ID_0
 SG_ Advanced_relaxation_voltage_delt : 28|1@1+ (1,0) [0|0] ""  BMU_ID_0
 SG_ Internal_BMU_error : 30|1@1+ (1,0) [0|0] ""  BMU_ID_0
 SG_ Safety_sensor_error : 31|1@1+ (1,0) [0|0] ""  BMU_ID_0
 SG_ High_voltage_sensor_errors : 32|1@1+ (1,0) [0|0] ""  BMU_ID_0
 SG_ IMD_errors : 33|1@1+ (1,0) [0|0] ""  BMU_ID_0
 SG_ Isolation_error : 34|1@1+ (1,0) [0|0] ""  BMU_ID_0
 SG_ BMU_SoC_errors : 35|1@1+ (1,0) [0|0] ""  BMU_ID_0
 SG_ BMU_SoH_error : 36|1@1+ (1,0) [0|0] ""  BMU_ID_0
 SG_ Contactor_stuck_open_errors : 37|1@1+ (1,0) [0|0] ""  BMU_ID_0
 SG_ Contactor_stuck_closed_errors : 38|1@1+ (1,0) [0|0] ""  BMU_ID_0
 SG_ Contactor_supply_error : 39|1@1+ (1,0) [0|0] ""  BMU_ID_0
 SG_ Contactor_precharge_error : 40|1@1+ (1,0) [0|0] ""  BMU_ID_0
 SG_ Emergency_button_error : 41|1@1+ (1,0) [0|0] ""  BMU_ID_0
 SG_ Actuation_errors : 42|1@1+ (1,0) [0|0] ""  BMU_ID_0
 SG_ Auto_OFF : 43|1@1+ (1,0) [0|0] ""  BMU_ID_0
 SG_ Mode_mismatch : 44|1@1+ (1,0) [0|0] ""  BMU_ID_0
 SG_ Open_wire_errors : 45|1@1+ (1,0) [0|0] ""  BMU_ID_0
 SG_ Output_driver_errors_diagnostics : 46|1@1+ (1,0) [0|0] ""  BMU_ID_0
 SG_ User_forced_errors : 47|1@1+ (1,0) [0|0] ""  BMU_ID_0
 SG_ SD_error : 48|1@1+ (1,0) [0|0] ""  BMU_ID_0
 SG_ Ethernet_module_error : 49|1@1+ (1,0) [0|0] ""  BMU_ID_0
 SG_ Internal_memory_errors : 29|1@1+ (1,0) [0|0] ""  BMU_ID_0

BO_ 1374 wBMU_ID_14_msg_05_warnings: 8 BMU_ID_14
 SG_ System_errors : 0|1@1+ (1,0) [0|0] ""  BMU_ID_0
 SG_ Architecture_configuration_error : 1|1@1+ (1,0) [0|0] ""  BMU_ID_0
 SG_ Parallelization_voltage_errors : 2|1@1+ (1,0) [0|0] ""  BMU_ID_0
 SG_ General_configuration_errors : 3|1@1+ (1,0) [0|0] ""  BMU_ID_0
 SG_ Parallelization_comm_lost_primar : 4|1@1+ (1,0) [0|0] ""  BMU_ID_0
 SG_ Cell_overvoltage : 5|1@1+ (1,0) [0|0] ""  BMU_ID_0
 SG_ Cell_undervoltage : 6|1@1+ (1,0) [0|0] ""  BMU_ID_0
 SG_ Comm_failure_with_CMU : 7|1@1+ (1,0) [0|0] ""  BMU_ID_0
 SG_ Internal_CMU_error : 8|1@1+ (1,0) [0|0] ""  BMU_ID_0
 SG_ Internal_CMU_temperature_error : 9|1@1+ (1,0) [0|0] ""  BMU_ID_0
 SG_ Internal_CMU_voltage_reference : 10|1@1+ (1,0) [0|0] ""  BMU_ID_0
 SG_ Cell_shortcircuit : 11|1@1+ (1,0) [0|0] ""  BMU_ID_0
 SG_ Battery_overcurrent : 12|1@1+ (1,0) [0|0] ""  BMU_ID_0
 SG_ Overload_ratio_exceeded : 13|1@1+ (1,0) [0|0] ""  BMU_ID_0
 SG_ Current_sensor_errors : 14|1@1+ (1,0) [0|0] ""  BMU_ID_0
 SG_ BMU_temperature_errors : 15|1@1+ (1,0) [0|0] ""  BMU_ID_0
 SG_ Cell_overtemperature : 16|1@1+ (1,0) [0|0] ""  BMU_ID_0
 SG_ Cell_undertemperature : 17|1@1+ (1,0) [0|0] ""  BMU_ID_0
 SG_ Balancing_overtemperature : 18|1@1+ (1,0) [0|0] ""  BMU_ID_0
 SG_ Balancing_undertemperature : 19|1@1+ (1,0) [0|0] ""  BMU_ID_0
 SG_ Max_op_cell_temp_delta : 20|1@1+ (1,0) [0|0] ""  BMU_ID_0
 SG_ Thermal_runaway : 21|1@1+ (1,0) [0|0] ""  BMU_ID_0
 SG_ OW_and_SC_detected_on_cell : 22|1@1+ (1,0) [0|0] ""  BMU_ID_0
 SG_ BMU_external_overtemperature : 23|1@1+ (1,0) [0|0] ""  BMU_ID_0
 SG_ Battery_undervoltage : 24|1@1+ (1,0) [0|0] ""  BMU_ID_0
 SG_ BMU_supply_voltage_error : 25|1@1+ (1,0) [0|0] ""  BMU_ID_0
 SG_ Battery_overvoltage : 26|1@1+ (1,0) [0|0] ""  BMU_ID_0
 SG_ Cells_unbalanced : 27|1@1+ (1,0) [0|0] ""  BMU_ID_0
 SG_ Advanced_relaxation_voltage_delt : 28|1@1+ (1,0) [0|0] ""  BMU_ID_0
 SG_ Internal_BMU_error : 30|1@1+ (1,0) [0|0] ""  BMU_ID_0
 SG_ Safety_sensor_error : 31|1@1+ (1,0) [0|0] ""  BMU_ID_0
 SG_ High_voltage_sensor_errors : 32|1@1+ (1,0) [0|0] ""  BMU_ID_0
 SG_ IMD_errors : 33|1@1+ (1,0) [0|0] ""  BMU_ID_0
 SG_ Isolation_error : 34|1@1+ (1,0) [0|0] ""  BMU_ID_0
 SG_ BMU_SoC_errors : 35|1@1+ (1,0) [0|0] ""  BMU_ID_0
 SG_ BMU_SoH_error : 36|1@1+ (1,0) [0|0] ""  BMU_ID_0
 SG_ Contactor_stuck_open_errors : 37|1@1+ (1,0) [0|0] ""  BMU_ID_0
 SG_ Contactor_stuck_closed_errors : 38|1@1+ (1,0) [0|0] ""  BMU_ID_0
 SG_ Contactor_supply_error : 39|1@1+ (1,0) [0|0] ""  BMU_ID_0
 SG_ Contactor_precharge_error : 40|1@1+ (1,0) [0|0] ""  BMU_ID_0
 SG_ Emergency_button_error : 41|1@1+ (1,0) [0|0] ""  BMU_ID_0
 SG_ Actuation_errors : 42|1@1+ (1,0) [0|0] ""  BMU_ID_0
 SG_ Auto_OFF : 43|1@1+ (1,0) [0|0] ""  BMU_ID_0
 SG_ Mode_mismatch : 44|1@1+ (1,0) [0|0] ""  BMU_ID_0
 SG_ Open_wire_errors : 45|1@1+ (1,0) [0|0] ""  BMU_ID_0
 SG_ Output_driver_errors_diagnostics : 46|1@1+ (1,0) [0|0] ""  BMU_ID_0
 SG_ User_forced_errors : 47|1@1+ (1,0) [0|0] ""  BMU_ID_0
 SG_ SD_error : 48|1@1+ (1,0) [0|0] ""  BMU_ID_0
 SG_ Ethernet_module_error : 49|1@1+ (1,0) [0|0] ""  BMU_ID_0
 SG_ Internal_memory_errors : 29|1@1+ (1,0) [0|0] ""  BMU_ID_0

BO_ 1375 wBMU_ID_15_msg_05_warnings: 8 BMU_ID_15
 SG_ System_errors : 0|1@1+ (1,0) [0|0] ""  BMU_ID_0
 SG_ Architecture_configuration_error : 1|1@1+ (1,0) [0|0] ""  BMU_ID_0
 SG_ Parallelization_voltage_errors : 2|1@1+ (1,0) [0|0] ""  BMU_ID_0
 SG_ General_configuration_errors : 3|1@1+ (1,0) [0|0] ""  BMU_ID_0
 SG_ Parallelization_comm_lost_primar : 4|1@1+ (1,0) [0|0] ""  BMU_ID_0
 SG_ Cell_overvoltage : 5|1@1+ (1,0) [0|0] ""  BMU_ID_0
 SG_ Cell_undervoltage : 6|1@1+ (1,0) [0|0] ""  BMU_ID_0
 SG_ Comm_failure_with_CMU : 7|1@1+ (1,0) [0|0] ""  BMU_ID_0
 SG_ Internal_CMU_error : 8|1@1+ (1,0) [0|0] ""  BMU_ID_0
 SG_ Internal_CMU_temperature_error : 9|1@1+ (1,0) [0|0] ""  BMU_ID_0
 SG_ Internal_CMU_voltage_reference : 10|1@1+ (1,0) [0|0] ""  BMU_ID_0
 SG_ Cell_shortcircuit : 11|1@1+ (1,0) [0|0] ""  BMU_ID_0
 SG_ Battery_overcurrent : 12|1@1+ (1,0) [0|0] ""  BMU_ID_0
 SG_ Overload_ratio_exceeded : 13|1@1+ (1,0) [0|0] ""  BMU_ID_0
 SG_ Current_sensor_errors : 14|1@1+ (1,0) [0|0] ""  BMU_ID_0
 SG_ BMU_temperature_errors : 15|1@1+ (1,0) [0|0] ""  BMU_ID_0
 SG_ Cell_overtemperature : 16|1@1+ (1,0) [0|0] ""  BMU_ID_0
 SG_ Cell_undertemperature : 17|1@1+ (1,0) [0|0] ""  BMU_ID_0
 SG_ Balancing_overtemperature : 18|1@1+ (1,0) [0|0] ""  BMU_ID_0
 SG_ Balancing_undertemperature : 19|1@1+ (1,0) [0|0] ""  BMU_ID_0
 SG_ Max_op_cell_temp_delta : 20|1@1+ (1,0) [0|0] ""  BMU_ID_0
 SG_ Thermal_runaway : 21|1@1+ (1,0) [0|0] ""  BMU_ID_0
 SG_ OW_and_SC_detected_on_cell : 22|1@1+ (1,0) [0|0] ""  BMU_ID_0
 SG_ BMU_external_overtemperature : 23|1@1+ (1,0) [0|0] ""  BMU_ID_0
 SG_ Battery_undervoltage : 24|1@1+ (1,0) [0|0] ""  BMU_ID_0
 SG_ BMU_supply_voltage_error : 25|1@1+ (1,0) [0|0] ""  BMU_ID_0
 SG_ Battery_overvoltage : 26|1@1+ (1,0) [0|0] ""  BMU_ID_0
 SG_ Cells_unbalanced : 27|1@1+ (1,0) [0|0] ""  BMU_ID_0
 SG_ Advanced_relaxation_voltage_delt : 28|1@1+ (1,0) [0|0] ""  BMU_ID_0
 SG_ Internal_BMU_error : 30|1@1+ (1,0) [0|0] ""  BMU_ID_0
 SG_ Safety_sensor_error : 31|1@1+ (1,0) [0|0] ""  BMU_ID_0
 SG_ High_voltage_sensor_errors : 32|1@1+ (1,0) [0|0] ""  BMU_ID_0
 SG_ IMD_errors : 33|1@1+ (1,0) [0|0] ""  BMU_ID_0
 SG_ Isolation_error : 34|1@1+ (1,0) [0|0] ""  BMU_ID_0
 SG_ BMU_SoC_errors : 35|1@1+ (1,0) [0|0] ""  BMU_ID_0
 SG_ BMU_SoH_error : 36|1@1+ (1,0) [0|0] ""  BMU_ID_0
 SG_ Contactor_stuck_open_errors : 37|1@1+ (1,0) [0|0] ""  BMU_ID_0
 SG_ Contactor_stuck_closed_errors : 38|1@1+ (1,0) [0|0] ""  BMU_ID_0
 SG_ Contactor_supply_error : 39|1@1+ (1,0) [0|0] ""  BMU_ID_0
 SG_ Contactor_precharge_error : 40|1@1+ (1,0) [0|0] ""  BMU_ID_0
 SG_ Emergency_button_error : 41|1@1+ (1,0) [0|0] ""  BMU_ID_0
 SG_ Actuation_errors : 42|1@1+ (1,0) [0|0] ""  BMU_ID_0
 SG_ Auto_OFF : 43|1@1+ (1,0) [0|0] ""  BMU_ID_0
 SG_ Mode_mismatch : 44|1@1+ (1,0) [0|0] ""  BMU_ID_0
 SG_ Open_wire_errors : 45|1@1+ (1,0) [0|0] ""  BMU_ID_0
 SG_ Output_driver_errors_diagnostics : 46|1@1+ (1,0) [0|0] ""  BMU_ID_0
 SG_ User_forced_errors : 47|1@1+ (1,0) [0|0] ""  BMU_ID_0
 SG_ SD_error : 48|1@1+ (1,0) [0|0] ""  BMU_ID_0
 SG_ Ethernet_module_error : 49|1@1+ (1,0) [0|0] ""  BMU_ID_0
 SG_ Internal_memory_errors : 29|1@1+ (1,0) [0|0] ""  BMU_ID_0

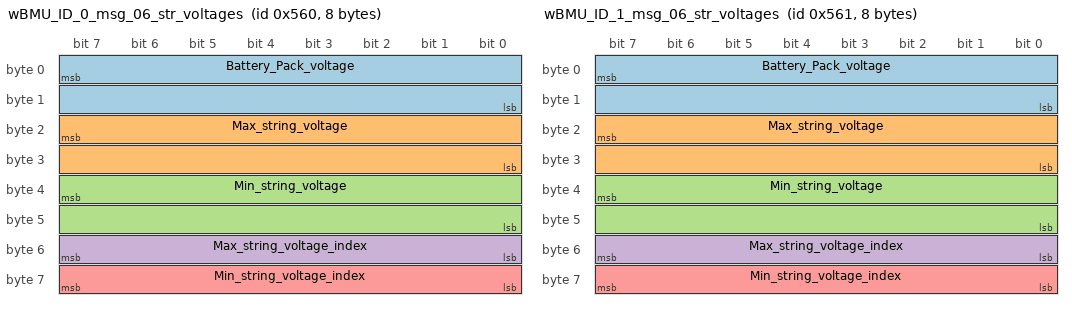
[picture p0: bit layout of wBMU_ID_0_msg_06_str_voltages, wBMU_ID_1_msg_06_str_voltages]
BO_ 1376 wBMU_ID_0_msg_06_str_voltages: 8 BMU_ID_0
 SG_ Battery_Pack_voltage : 7|16@0+ (0.1,0) [0|0] "V"  BMU_ID_0
 SG_ Max_string_voltage : 23|16@0+ (0.1,0) [0|0] "V"  BMU_ID_0
 SG_ Min_string_voltage : 39|16@0+ (0.1,0) [0|0] "V"  BMU_ID_0
 SG_ Max_string_voltage_index : 55|8@0+ (1,0) [0|0] "-"  BMU_ID_0
 SG_ Min_string_voltage_index : 63|8@0+ (1,0) [0|0] "-"  BMU_ID_0

BO_ 1377 wBMU_ID_1_msg_06_str_voltages: 8 BMU_ID_1
 SG_ Battery_Pack_voltage : 7|16@0+ (0.1,0) [0|0] "V"  BMU_ID_1
 SG_ Max_string_voltage : 23|16@0+ (0.1,0) [0|0] "V"  BMU_ID_1
 SG_ Min_string_voltage : 39|16@0+ (0.1,0) [0|0] "V"  BMU_ID_1
 SG_ Max_string_voltage_index : 55|8@0+ (1,0) [0|0] "-"  BMU_ID_1
 SG_ Min_string_voltage_index : 63|8@0+ (1,0) [0|0] "-"  BMU_ID_1

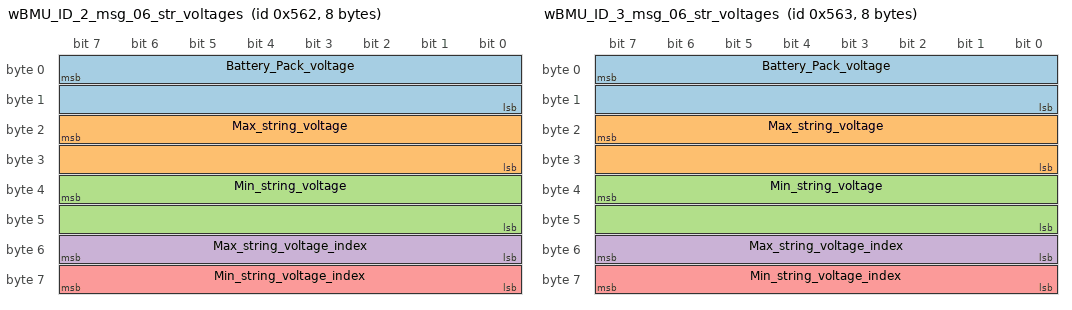
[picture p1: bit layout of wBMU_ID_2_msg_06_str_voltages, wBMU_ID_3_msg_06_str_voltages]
BO_ 1378 wBMU_ID_2_msg_06_str_voltages: 8 BMU_ID_2
 SG_ Battery_Pack_voltage : 7|16@0+ (0.1,0) [0|0] "V"  BMU_ID_2
 SG_ Max_string_voltage : 23|16@0+ (0.1,0) [0|0] "V"  BMU_ID_2
 SG_ Min_string_voltage : 39|16@0+ (0.1,0) [0|0] "V"  BMU_ID_2
 SG_ Max_string_voltage_index : 55|8@0+ (1,0) [0|0] "-"  BMU_ID_2
 SG_ Min_string_voltage_index : 63|8@0+ (1,0) [0|0] "-"  BMU_ID_2

BO_ 1379 wBMU_ID_3_msg_06_str_voltages: 8 BMU_ID_3
 SG_ Battery_Pack_voltage : 7|16@0+ (0.1,0) [0|0] "V"  BMU_ID_3
 SG_ Max_string_voltage : 23|16@0+ (0.1,0) [0|0] "V"  BMU_ID_3
 SG_ Min_string_voltage : 39|16@0+ (0.1,0) [0|0] "V"  BMU_ID_3
 SG_ Max_string_voltage_index : 55|8@0+ (1,0) [0|0] "-"  BMU_ID_3
 SG_ Min_string_voltage_index : 63|8@0+ (1,0) [0|0] "-"  BMU_ID_3

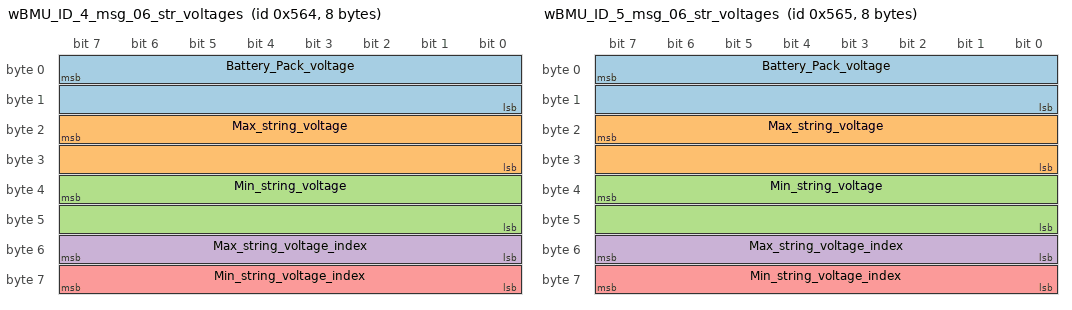
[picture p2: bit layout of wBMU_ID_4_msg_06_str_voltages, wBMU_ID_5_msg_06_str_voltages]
BO_ 1380 wBMU_ID_4_msg_06_str_voltages: 8 BMU_ID_4
 SG_ Battery_Pack_voltage : 7|16@0+ (0.1,0) [0|0] "V"  BMU_ID_4
 SG_ Max_string_voltage : 23|16@0+ (0.1,0) [0|0] "V"  BMU_ID_4
 SG_ Min_string_voltage : 39|16@0+ (0.1,0) [0|0] "V"  BMU_ID_4
 SG_ Max_string_voltage_index : 55|8@0+ (1,0) [0|0] "-"  BMU_ID_4
 SG_ Min_string_voltage_index : 63|8@0+ (1,0) [0|0] "-"  BMU_ID_4

BO_ 1381 wBMU_ID_5_msg_06_str_voltages: 8 BMU_ID_5
 SG_ Battery_Pack_voltage : 7|16@0+ (0.1,0) [0|0] "V"  BMU_ID_5
 SG_ Max_string_voltage : 23|16@0+ (0.1,0) [0|0] "V"  BMU_ID_5
 SG_ Min_string_voltage : 39|16@0+ (0.1,0) [0|0] "V"  BMU_ID_5
 SG_ Max_string_voltage_index : 55|8@0+ (1,0) [0|0] "-"  BMU_ID_5
 SG_ Min_string_voltage_index : 63|8@0+ (1,0) [0|0] "-"  BMU_ID_5

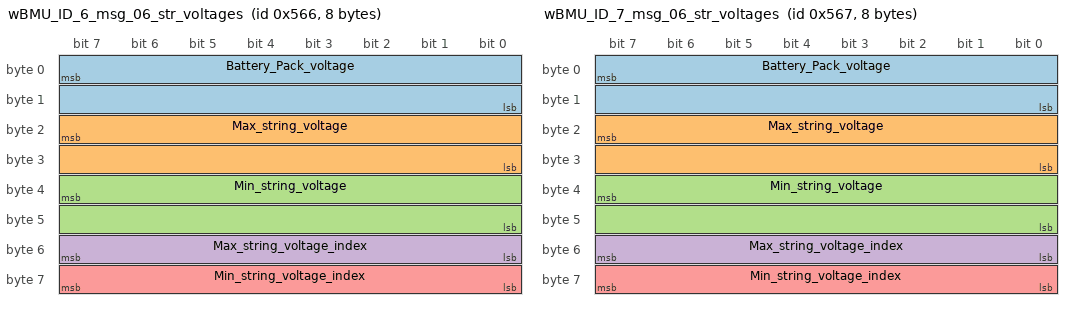
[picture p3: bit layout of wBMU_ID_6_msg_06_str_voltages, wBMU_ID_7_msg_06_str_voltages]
BO_ 1382 wBMU_ID_6_msg_06_str_voltages: 8 BMU_ID_6
 SG_ Battery_Pack_voltage : 7|16@0+ (0.1,0) [0|0] "V"  BMU_ID_6
 SG_ Max_string_voltage : 23|16@0+ (0.1,0) [0|0] "V"  BMU_ID_6
 SG_ Min_string_voltage : 39|16@0+ (0.1,0) [0|0] "V"  BMU_ID_6
 SG_ Max_string_voltage_index : 55|8@0+ (1,0) [0|0] "-"  BMU_ID_6
 SG_ Min_string_voltage_index : 63|8@0+ (1,0) [0|0] "-"  BMU_ID_6

BO_ 1383 wBMU_ID_7_msg_06_str_voltages: 8 BMU_ID_7
 SG_ Battery_Pack_voltage : 7|16@0+ (0.1,0) [0|0] "V"  BMU_ID_7
 SG_ Max_string_voltage : 23|16@0+ (0.1,0) [0|0] "V"  BMU_ID_7
 SG_ Min_string_voltage : 39|16@0+ (0.1,0) [0|0] "V"  BMU_ID_7
 SG_ Max_string_voltage_index : 55|8@0+ (1,0) [0|0] "-"  BMU_ID_7
 SG_ Min_string_voltage_index : 63|8@0+ (1,0) [0|0] "-"  BMU_ID_7

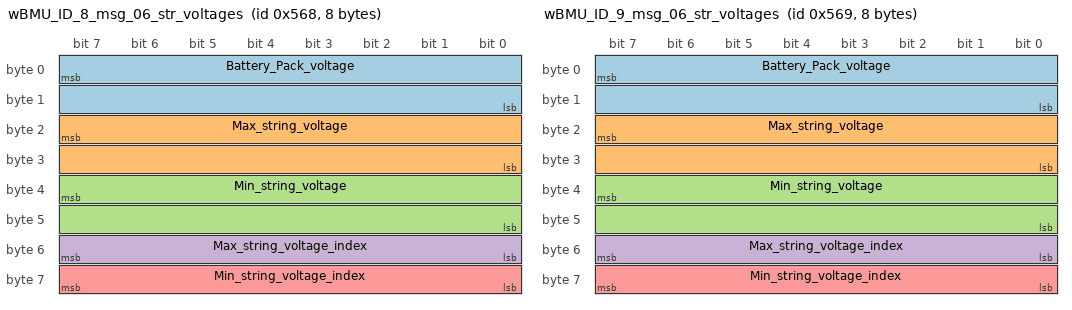
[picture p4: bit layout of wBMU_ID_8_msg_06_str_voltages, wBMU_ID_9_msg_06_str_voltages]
BO_ 1384 wBMU_ID_8_msg_06_str_voltages: 8 BMU_ID_8
 SG_ Battery_Pack_voltage : 7|16@0+ (0.1,0) [0|0] "V"  BMU_ID_8
 SG_ Max_string_voltage : 23|16@0+ (0.1,0) [0|0] "V"  BMU_ID_8
 SG_ Min_string_voltage : 39|16@0+ (0.1,0) [0|0] "V"  BMU_ID_8
 SG_ Max_string_voltage_index : 55|8@0+ (1,0) [0|0] "-"  BMU_ID_8
 SG_ Min_string_voltage_index : 63|8@0+ (1,0) [0|0] "-"  BMU_ID_8

BO_ 1385 wBMU_ID_9_msg_06_str_voltages: 8 BMU_ID_9
 SG_ Battery_Pack_voltage : 7|16@0+ (0.1,0) [0|0] "V"  BMU_ID_9
 SG_ Max_string_voltage : 23|16@0+ (0.1,0) [0|0] "V"  BMU_ID_9
 SG_ Min_string_voltage : 39|16@0+ (0.1,0) [0|0] "V"  BMU_ID_9
 SG_ Max_string_voltage_index : 55|8@0+ (1,0) [0|0] "-"  BMU_ID_9
 SG_ Min_string_voltage_index : 63|8@0+ (1,0) [0|0] "-"  BMU_ID_9

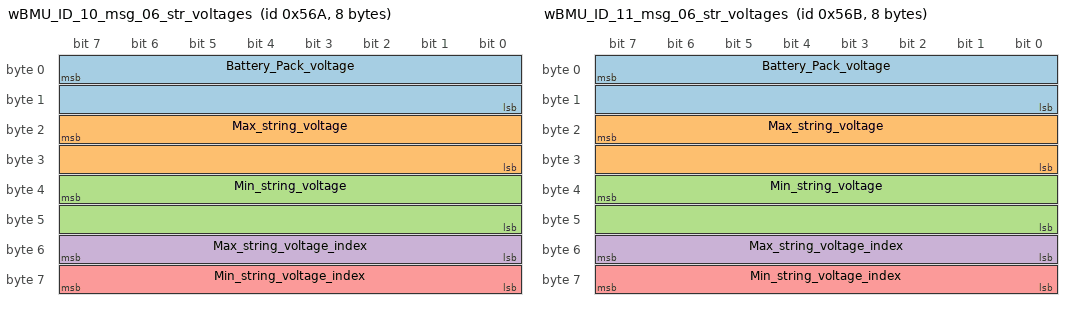
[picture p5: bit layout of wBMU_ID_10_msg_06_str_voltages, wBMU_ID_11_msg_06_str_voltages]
BO_ 1386 wBMU_ID_10_msg_06_str_voltages: 8 BMU_ID_10
 SG_ Battery_Pack_voltage : 7|16@0+ (0.1,0) [0|0] "V"  BMU_ID_10
 SG_ Max_string_voltage : 23|16@0+ (0.1,0) [0|0] "V"  BMU_ID_10
 SG_ Min_string_voltage : 39|16@0+ (0.1,0) [0|0] "V"  BMU_ID_10
 SG_ Max_string_voltage_index : 55|8@0+ (1,0) [0|0] "-"  BMU_ID_10
 SG_ Min_string_voltage_index : 63|8@0+ (1,0) [0|0] "-"  BMU_ID_10

BO_ 1387 wBMU_ID_11_msg_06_str_voltages: 8 BMU_ID_11
 SG_ Battery_Pack_voltage : 7|16@0+ (0.1,0) [0|0] "V"  BMU_ID_11
 SG_ Max_string_voltage : 23|16@0+ (0.1,0) [0|0] "V"  BMU_ID_11
 SG_ Min_string_voltage : 39|16@0+ (0.1,0) [0|0] "V"  BMU_ID_11
 SG_ Max_string_voltage_index : 55|8@0+ (1,0) [0|0] "-"  BMU_ID_11
 SG_ Min_string_voltage_index : 63|8@0+ (1,0) [0|0] "-"  BMU_ID_11

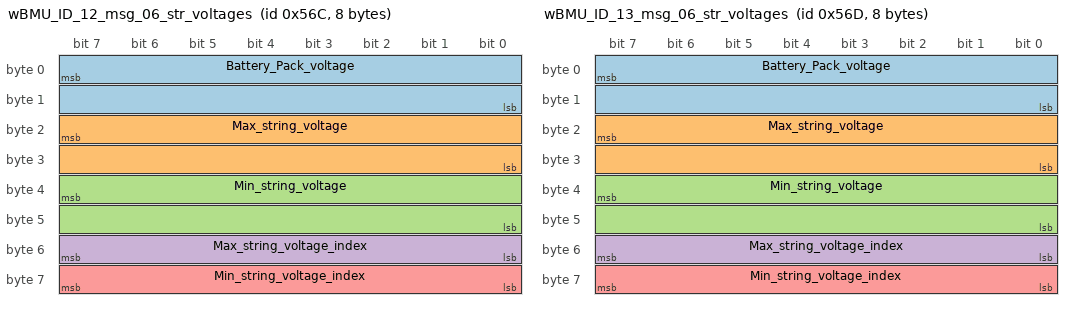
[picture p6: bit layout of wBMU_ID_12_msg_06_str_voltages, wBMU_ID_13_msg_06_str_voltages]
BO_ 1388 wBMU_ID_12_msg_06_str_voltages: 8 BMU_ID_12
 SG_ Battery_Pack_voltage : 7|16@0+ (0.1,0) [0|0] "V"  BMU_ID_12
 SG_ Max_string_voltage : 23|16@0+ (0.1,0) [0|0] "V"  BMU_ID_12
 SG_ Min_string_voltage : 39|16@0+ (0.1,0) [0|0] "V"  BMU_ID_12
 SG_ Max_string_voltage_index : 55|8@0+ (1,0) [0|0] "-"  BMU_ID_12
 SG_ Min_string_voltage_index : 63|8@0+ (1,0) [0|0] "-"  BMU_ID_12

BO_ 1389 wBMU_ID_13_msg_06_str_voltages: 8 BMU_ID_13
 SG_ Battery_Pack_voltage : 7|16@0+ (0.1,0) [0|0] "V"  BMU_ID_13
 SG_ Max_string_voltage : 23|16@0+ (0.1,0) [0|0] "V"  BMU_ID_13
 SG_ Min_string_voltage : 39|16@0+ (0.1,0) [0|0] "V"  BMU_ID_13
 SG_ Max_string_voltage_index : 55|8@0+ (1,0) [0|0] "-"  BMU_ID_13
 SG_ Min_string_voltage_index : 63|8@0+ (1,0) [0|0] "-"  BMU_ID_13

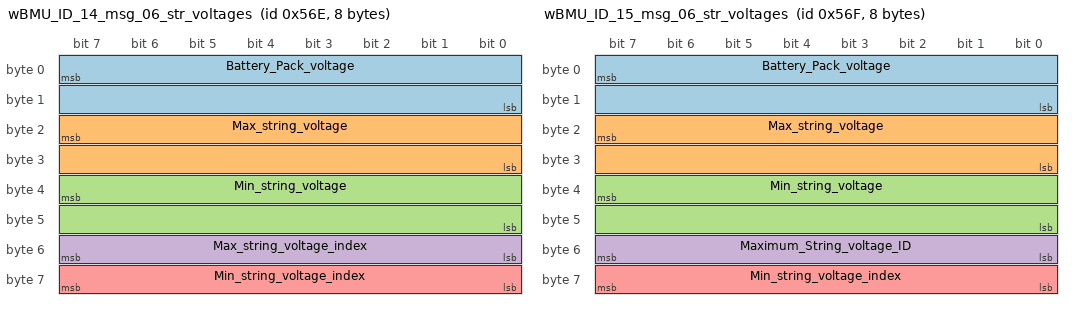
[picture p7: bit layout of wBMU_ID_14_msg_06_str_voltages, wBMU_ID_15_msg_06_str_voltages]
BO_ 1390 wBMU_ID_14_msg_06_str_voltages: 8 BMU_ID_14
 SG_ Battery_Pack_voltage : 7|16@0+ (0.1,0) [0|0] "V"  BMU_ID_14
 SG_ Max_string_voltage : 23|16@0+ (0.1,0) [0|0] "V"  BMU_ID_14
 SG_ Min_string_voltage : 39|16@0+ (0.1,0) [0|0] "V"  BMU_ID_14
 SG_ Max_string_voltage_index : 55|8@0+ (1,0) [0|0] "-"  BMU_ID_14
 SG_ Min_string_voltage_index : 63|8@0+ (1,0) [0|0] "-"  BMU_ID_14

BO_ 1391 wBMU_ID_15_msg_06_str_voltages: 8 BMU_ID_15
 SG_ Battery_Pack_voltage : 7|16@0+ (0.1,0) [0|0] "V"  BMU_ID_15
 SG_ Max_string_voltage : 23|16@0+ (0.1,0) [0|0] "V"  BMU_ID_15
 SG_ Min_string_voltage : 39|16@0+ (0.1,0) [0|0] "V"  BMU_ID_15
 SG_ Maximum_String_voltage_ID : 55|8@0+ (1,0) [0|0] "-"  BMU_ID_15
 SG_ Min_string_voltage_index : 63|8@0+ (1,0) [0|0] "-"  BMU_ID_15

BO_ 1408 wBMU_ID_0_msg_08_status: 8 BMU_ID_0
 SG_ Content_ID M : 7|8@0+ (1,0) [0|0] ""  BMU_ID_0
 SG_ Cell_voltage_maximum_value m0 : 15|16@0+ (1,0) [0|0] "mV"  BMU_ID_0
 SG_ Cell_voltage_minimum_value m0 : 31|16@0+ (1,0) [0|0] "mV"  BMU_ID_0
 SG_ Cell_voltage_max_channel_index m0 : 40|5@0+ (1,0) [0|0] "-"  BMU_ID_0
 SG_ Cell_voltage_max_cmu_index m0 : 47|7@0+ (1,0) [0|0] "-"  BMU_ID_0
 SG_ Cell_voltage_min_channel_index m0 : 60|5@0+ (1,0) [0|0] "-"  BMU_ID_0
 SG_ Cell_voltage_min_cmu_index m0 : 51|7@0+ (1,0) [0|0] "-"  BMU_ID_0
 SG_ Cell_temp_maximum_value m1 : 15|8@0+ (1,-50) [0|0] "ºC"  BMU_ID_0
 SG_ Cell_temp_minimum_value m1 : 23|8@0+ (1,-50) [0|0] "ºC"  BMU_ID_0
 SG_ Cell_temp_average_value m1 : 31|8@0+ (1,-50) [0|0] "ºC"  BMU_ID_0
 SG_ Cell_temp_max_cmu_index m1 : 39|7@0+ (1,0) [0|0] ""  BMU_ID_0
 SG_ Cell_temp_max_channel_index m1 : 32|5@0+ (1,0) [0|0] ""  BMU_ID_0
 SG_ Cell_temp_min_cmu_index m1 : 43|7@0+ (1,0) [0|0] ""  BMU_ID_0
 SG_ Cell_temp_min_channel_index m1 : 52|5@0+ (1,0) [0|0] ""  BMU_ID_0
 SG_ Reserved m1 : 63|8@0+ (1,0) [0|0] ""  BMU_ID_0
 SG_ Balancing_temp_maximum_value m2 : 15|8@0+ (1,-50) [0|0] "ºC"  BMU_ID_0
 SG_ Balancing_temp_minimum_value m2 : 23|8@0+ (1,-50) [0|0] "ºC"  BMU_ID_0
 SG_ Balancing_temp_average_value m2 : 31|8@0+ (1,-50) [0|0] "ºC"  BMU_ID_0
 SG_ Balancing_temp_max_cmu_index m2 : 39|8@0+ (1,0) [0|0] ""  BMU_ID_0
 SG_ Balancing_temp_min_cmu_index m2 : 47|8@0+ (1,0) [0|0] ""  BMU_ID_0
 SG_ Cell_voltage_average_value m2 : 55|16@0+ (1,0) [0|0] "mV"  BMU_ID_0
 SG_ Max_cell_voltage_balancing m3 : 15|16@0+ (1,0) [0|0] "mV"  BMU_ID_0
 SG_ Min_cell_voltage_balancing m3 : 31|16@0+ (1,0) [0|0] "mV"  BMU_ID_0
 SG_ Max_cell_voltage_balancing_ID m3 : 47|12@0+ (1,0) [0|0] "-"  BMU_ID_0
 SG_ Min_cell_voltage_balancing_ID m3 : 51|12@0+ (1,0) [0|0] "-"  BMU_ID_0

BO_ 1409 wBMU_ID_1_msg_08_status: 8 BMU_ID_1
 SG_ Content_ID M : 7|8@0+ (1,0) [0|0] ""  BMU_ID_0
 SG_ Cell_voltage_maximum_value m0 : 15|16@0+ (1,0) [0|0] "mV"  BMU_ID_0
 SG_ Cell_voltage_minimum_value m0 : 31|16@0+ (1,0) [0|0] "mV"  BMU_ID_0
 SG_ Cell_voltage_max_channel_index m0 : 40|5@0+ (1,0) [0|0] "-"  BMU_ID_0
 SG_ Cell_voltage_max_cmu_index m0 : 47|7@0+ (1,0) [0|0] "-"  BMU_ID_0
 SG_ Cell_voltage_min_channel_index m0 : 60|5@0+ (1,0) [0|0] "-"  BMU_ID_0
 SG_ Cell_voltage_min_cmu_index m0 : 51|7@0+ (1,0) [0|0] "-"  BMU_ID_0
 SG_ Cell_temp_maximum_value m1 : 15|8@0+ (1,-50) [0|0] "ºC"  BMU_ID_0
 SG_ Cell_temp_minimum_value m1 : 23|8@0+ (1,-50) [0|0] "ºC"  BMU_ID_0
 SG_ Cell_temp_average_value m1 : 31|8@0+ (1,-50) [0|0] "ºC"  BMU_ID_0
 SG_ Cell_temp_max_cmu_index m1 : 39|7@0+ (1,0) [0|0] ""  BMU_ID_0
 SG_ Cell_temp_max_channel_index m1 : 32|5@0+ (1,0) [0|0] ""  BMU_ID_0
 SG_ Cell_temp_min_cmu_index m1 : 43|7@0+ (1,0) [0|0] ""  BMU_ID_0
 SG_ Cell_temp_min_channel_index m1 : 52|5@0+ (1,0) [0|0] ""  BMU_ID_0
 SG_ Reserved m1 : 63|8@0+ (1,0) [0|0] ""  BMU_ID_0
 SG_ Balancing_temp_maximum_value m2 : 15|8@0+ (1,-50) [0|0] "ºC"  BMU_ID_0
 SG_ Balancing_temp_minimum_value m2 : 23|8@0+ (1,-50) [0|0] "ºC"  BMU_ID_0
 SG_ Balancing_temp_average_value m2 : 31|8@0+ (1,-50) [0|0] "ºC"  BMU_ID_0
 SG_ Balancing_temp_max_cmu_index m2 : 39|8@0+ (1,0) [0|0] ""  BMU_ID_0
 SG_ Balancing_temp_min_cmu_index m2 : 47|8@0+ (1,0) [0|0] ""  BMU_ID_0
 SG_ Cell_voltage_average_value m2 : 55|16@0+ (1,0) [0|0] "mV"  BMU_ID_0
 SG_ Max_cell_voltage_balancing m3 : 15|16@0+ (1,0) [0|0] "mV"  BMU_ID_0
 SG_ Min_cell_voltage_balancing m3 : 31|16@0+ (1,0) [0|0] "mV"  BMU_ID_0
 SG_ Max_cell_voltage_balancing_ID m3 : 47|12@0+ (1,0) [0|0] "-"  BMU_ID_0
 SG_ Min_cell_voltage_balancing_ID m3 : 51|12@0+ (1,0) [0|0] "-"  BMU_ID_0

BO_ 1410 wBMU_ID_2_msg_08_status: 8 BMU_ID_2
 SG_ Content_ID M : 7|8@0+ (1,0) [0|0] ""  BMU_ID_0
 SG_ Cell_voltage_maximum_value m0 : 15|16@0+ (1,0) [0|0] "mV"  BMU_ID_0
 SG_ Cell_voltage_minimum_value m0 : 31|16@0+ (1,0) [0|0] "mV"  BMU_ID_0
 SG_ Cell_voltage_max_channel_index m0 : 40|5@0+ (1,0) [0|0] "-"  BMU_ID_0
 SG_ Cell_voltage_max_cmu_index m0 : 47|7@0+ (1,0) [0|0] "-"  BMU_ID_0
 SG_ Cell_voltage_min_channel_index m0 : 60|5@0+ (1,0) [0|0] "-"  BMU_ID_0
 SG_ Cell_voltage_min_cmu_index m0 : 51|7@0+ (1,0) [0|0] "-"  BMU_ID_0
 SG_ Cell_temp_maximum_value m1 : 15|8@0+ (1,-50) [0|0] "ºC"  BMU_ID_0
 SG_ Cell_temp_minimum_value m1 : 23|8@0+ (1,-50) [0|0] "ºC"  BMU_ID_0
 SG_ Cell_temp_average_value m1 : 31|8@0+ (1,-50) [0|0] "ºC"  BMU_ID_0
 SG_ Cell_temp_max_cmu_index m1 : 39|7@0+ (1,0) [0|0] ""  BMU_ID_0
 SG_ Cell_temp_max_channel_index m1 : 32|5@0+ (1,0) [0|0] ""  BMU_ID_0
 SG_ Cell_temp_min_cmu_index m1 : 43|7@0+ (1,0) [0|0] ""  BMU_ID_0
 SG_ Cell_temp_min_channel_index m1 : 52|5@0+ (1,0) [0|0] ""  BMU_ID_0
 SG_ Reserved m1 : 63|8@0+ (1,0) [0|0] ""  BMU_ID_0
 SG_ Balancing_temp_maximum_value m2 : 15|8@0+ (1,-50) [0|0] "ºC"  BMU_ID_0
 SG_ Balancing_temp_minimum_value m2 : 23|8@0+ (1,-50) [0|0] "ºC"  BMU_ID_0
 SG_ Balancing_temp_average_value m2 : 31|8@0+ (1,-50) [0|0] "ºC"  BMU_ID_0
 SG_ Balancing_temp_max_cmu_index m2 : 39|8@0+ (1,0) [0|0] ""  BMU_ID_0
 SG_ Balancing_temp_min_cmu_index m2 : 47|8@0+ (1,0) [0|0] ""  BMU_ID_0
 SG_ Cell_voltage_average_value m2 : 55|16@0+ (1,0) [0|0] "mV"  BMU_ID_0
 SG_ Max_cell_voltage_balancing m3 : 15|16@0+ (1,0) [0|0] "mV"  BMU_ID_0
 SG_ Min_cell_voltage_balancing m3 : 31|16@0+ (1,0) [0|0] "mV"  BMU_ID_0
 SG_ Max_cell_voltage_balancing_ID m3 : 47|12@0+ (1,0) [0|0] "-"  BMU_ID_0
 SG_ Min_cell_voltage_balancing_ID m3 : 51|12@0+ (1,0) [0|0] "-"  BMU_ID_0

BO_ 1411 wBMU_ID_3_msg_08_status: 8 BMU_ID_3
 SG_ Content_ID M : 7|8@0+ (1,0) [0|0] ""  BMU_ID_0
 SG_ Cell_voltage_maximum_value m0 : 15|16@0+ (1,0) [0|0] "mV"  BMU_ID_0
 SG_ Cell_voltage_minimum_value m0 : 31|16@0+ (1,0) [0|0] "mV"  BMU_ID_0
 SG_ Cell_voltage_max_channel_index m0 : 40|5@0+ (1,0) [0|0] "-"  BMU_ID_0
 SG_ Cell_voltage_max_cmu_index m0 : 47|7@0+ (1,0) [0|0] "-"  BMU_ID_0
 SG_ Cell_voltage_min_channel_index m0 : 60|5@0+ (1,0) [0|0] "-"  BMU_ID_0
 SG_ Cell_voltage_min_cmu_index m0 : 51|7@0+ (1,0) [0|0] "-"  BMU_ID_0
 SG_ Cell_temp_maximum_value m1 : 15|8@0+ (1,-50) [0|0] "ºC"  BMU_ID_0
 SG_ Cell_temp_minimum_value m1 : 23|8@0+ (1,-50) [0|0] "ºC"  BMU_ID_0
 SG_ Cell_temp_average_value m1 : 31|8@0+ (1,-50) [0|0] "ºC"  BMU_ID_0
 SG_ Cell_temp_max_cmu_index m1 : 39|7@0+ (1,0) [0|0] ""  BMU_ID_0
 SG_ Cell_temp_max_channel_index m1 : 32|5@0+ (1,0) [0|0] ""  BMU_ID_0
 SG_ Cell_temp_min_cmu_index m1 : 43|7@0+ (1,0) [0|0] ""  BMU_ID_0
 SG_ Cell_temp_min_channel_index m1 : 52|5@0+ (1,0) [0|0] ""  BMU_ID_0
 SG_ Reserved m1 : 63|8@0+ (1,0) [0|0] ""  BMU_ID_0
 SG_ Balancing_temp_maximum_value m2 : 15|8@0+ (1,-50) [0|0] "ºC"  BMU_ID_0
 SG_ Balancing_temp_minimum_value m2 : 23|8@0+ (1,-50) [0|0] "ºC"  BMU_ID_0
 SG_ Balancing_temp_average_value m2 : 31|8@0+ (1,-50) [0|0] "ºC"  BMU_ID_0
 SG_ Balancing_temp_max_cmu_index m2 : 39|8@0+ (1,0) [0|0] ""  BMU_ID_0
 SG_ Balancing_temp_min_cmu_index m2 : 47|8@0+ (1,0) [0|0] ""  BMU_ID_0
 SG_ Cell_voltage_average_value m2 : 55|16@0+ (1,0) [0|0] "mV"  BMU_ID_0
 SG_ Max_cell_voltage_balancing m3 : 15|16@0+ (1,0) [0|0] "mV"  BMU_ID_0
 SG_ Min_cell_voltage_balancing m3 : 31|16@0+ (1,0) [0|0] "mV"  BMU_ID_0
 SG_ Max_cell_voltage_balancing_ID m3 : 47|12@0+ (1,0) [0|0] "-"  BMU_ID_0
 SG_ Min_cell_voltage_balancing_ID m3 : 51|12@0+ (1,0) [0|0] "-"  BMU_ID_0

BO_ 1412 wBMU_ID_4_msg_08_status: 8 BMU_ID_4
 SG_ Content_ID M : 7|8@0+ (1,0) [0|0] ""  BMU_ID_0
 SG_ Cell_voltage_maximum_value m0 : 15|16@0+ (1,0) [0|0] "mV"  BMU_ID_0
 SG_ Cell_voltage_minimum_value m0 : 31|16@0+ (1,0) [0|0] "mV"  BMU_ID_0
 SG_ Cell_voltage_max_channel_index m0 : 40|5@0+ (1,0) [0|0] "-"  BMU_ID_0
 SG_ Cell_voltage_max_cmu_index m0 : 47|7@0+ (1,0) [0|0] "-"  BMU_ID_0
 SG_ Cell_voltage_min_channel_index m0 : 60|5@0+ (1,0) [0|0] "-"  BMU_ID_0
 SG_ Cell_voltage_min_cmu_index m0 : 51|7@0+ (1,0) [0|0] "-"  BMU_ID_0
 SG_ Cell_temp_maximum_value m1 : 15|8@0+ (1,-50) [0|0] "ºC"  BMU_ID_0
 SG_ Cell_temp_minimum_value m1 : 23|8@0+ (1,-50) [0|0] "ºC"  BMU_ID_0
 SG_ Cell_temp_average_value m1 : 31|8@0+ (1,-50) [0|0] "ºC"  BMU_ID_0
 SG_ Cell_temp_max_cmu_index m1 : 39|7@0+ (1,0) [0|0] ""  BMU_ID_0
 SG_ Cell_temp_max_channel_index m1 : 32|5@0+ (1,0) [0|0] ""  BMU_ID_0
 SG_ Cell_temp_min_cmu_index m1 : 43|7@0+ (1,0) [0|0] ""  BMU_ID_0
 SG_ Cell_temp_min_channel_index m1 : 52|5@0+ (1,0) [0|0] ""  BMU_ID_0
 SG_ Reserved m1 : 63|8@0+ (1,0) [0|0] ""  BMU_ID_0
 SG_ Balancing_temp_maximum_value m2 : 15|8@0+ (1,-50) [0|0] "ºC"  BMU_ID_0
 SG_ Balancing_temp_minimum_value m2 : 23|8@0+ (1,-50) [0|0] "ºC"  BMU_ID_0
 SG_ Balancing_temp_average_value m2 : 31|8@0+ (1,-50) [0|0] "ºC"  BMU_ID_0
 SG_ Balancing_temp_max_cmu_index m2 : 39|8@0+ (1,0) [0|0] ""  BMU_ID_0
 SG_ Balancing_temp_min_cmu_index m2 : 47|8@0+ (1,0) [0|0] ""  BMU_ID_0
 SG_ Cell_voltage_average_value m2 : 55|16@0+ (1,0) [0|0] "mV"  BMU_ID_0
 SG_ Max_cell_voltage_balancing m3 : 15|16@0+ (1,0) [0|0] "mV"  BMU_ID_0
 SG_ Min_cell_voltage_balancing m3 : 31|16@0+ (1,0) [0|0] "mV"  BMU_ID_0
 SG_ Max_cell_voltage_balancing_ID m3 : 47|12@0+ (1,0) [0|0] "-"  BMU_ID_0
 SG_ Min_cell_voltage_balancing_ID m3 : 51|12@0+ (1,0) [0|0] "-"  BMU_ID_0

BO_ 1413 wBMU_ID_5_msg_08_status: 8 BMU_ID_5
 SG_ Content_ID M : 7|8@0+ (1,0) [0|0] ""  BMU_ID_0
 SG_ Cell_voltage_maximum_value m0 : 15|16@0+ (1,0) [0|0] "mV"  BMU_ID_0
 SG_ Cell_voltage_minimum_value m0 : 31|16@0+ (1,0) [0|0] "mV"  BMU_ID_0
 SG_ Cell_voltage_max_channel_index m0 : 40|5@0+ (1,0) [0|0] "-"  BMU_ID_0
 SG_ Cell_voltage_max_cmu_index m0 : 47|7@0+ (1,0) [0|0] "-"  BMU_ID_0
 SG_ Cell_voltage_min_channel_index m0 : 60|5@0+ (1,0) [0|0] "-"  BMU_ID_0
 SG_ Cell_voltage_min_cmu_index m0 : 51|7@0+ (1,0) [0|0] "-"  BMU_ID_0
 SG_ Cell_temp_maximum_value m1 : 15|8@0+ (1,-50) [0|0] "ºC"  BMU_ID_0
 SG_ Cell_temp_minimum_value m1 : 23|8@0+ (1,-50) [0|0] "ºC"  BMU_ID_0
 SG_ Cell_temp_average_value m1 : 31|8@0+ (1,-50) [0|0] "ºC"  BMU_ID_0
 SG_ Cell_temp_max_cmu_index m1 : 39|7@0+ (1,0) [0|0] ""  BMU_ID_0
 SG_ Cell_temp_max_channel_index m1 : 32|5@0+ (1,0) [0|0] ""  BMU_ID_0
 SG_ Cell_temp_min_cmu_index m1 : 43|7@0+ (1,0) [0|0] ""  BMU_ID_0
 SG_ Cell_temp_min_channel_index m1 : 52|5@0+ (1,0) [0|0] ""  BMU_ID_0
 SG_ Reserved m1 : 63|8@0+ (1,0) [0|0] ""  BMU_ID_0
 SG_ Balancing_temp_maximum_value m2 : 15|8@0+ (1,-50) [0|0] "ºC"  BMU_ID_0
 SG_ Balancing_temp_minimum_value m2 : 23|8@0+ (1,-50) [0|0] "ºC"  BMU_ID_0
 SG_ Balancing_temp_average_value m2 : 31|8@0+ (1,-50) [0|0] "ºC"  BMU_ID_0
 SG_ Balancing_temp_max_cmu_index m2 : 39|8@0+ (1,0) [0|0] ""  BMU_ID_0
 SG_ Balancing_temp_min_cmu_index m2 : 47|8@0+ (1,0) [0|0] ""  BMU_ID_0
 SG_ Cell_voltage_average_value m2 : 55|16@0+ (1,0) [0|0] "mV"  BMU_ID_0
 SG_ Max_cell_voltage_balancing m3 : 15|16@0+ (1,0) [0|0] "mV"  BMU_ID_0
 SG_ Min_cell_voltage_balancing m3 : 31|16@0+ (1,0) [0|0] "mV"  BMU_ID_0
 SG_ Max_cell_voltage_balancing_ID m3 : 47|12@0+ (1,0) [0|0] "-"  BMU_ID_0
 SG_ Min_cell_voltage_balancing_ID m3 : 51|12@0+ (1,0) [0|0] "-"  BMU_ID_0

BO_ 1414 wBMU_ID_6_msg_08_status: 8 BMU_ID_6
 SG_ Content_ID M : 7|8@0+ (1,0) [0|0] ""  BMU_ID_0
 SG_ Cell_voltage_maximum_value m0 : 15|16@0+ (1,0) [0|0] "mV"  BMU_ID_0
 SG_ Cell_voltage_minimum_value m0 : 31|16@0+ (1,0) [0|0] "mV"  BMU_ID_0
 SG_ Cell_voltage_max_channel_index m0 : 40|5@0+ (1,0) [0|0] "-"  BMU_ID_0
 SG_ Cell_voltage_max_cmu_index m0 : 47|7@0+ (1,0) [0|0] "-"  BMU_ID_0
 SG_ Cell_voltage_min_channel_index m0 : 60|5@0+ (1,0) [0|0] "-"  BMU_ID_0
 SG_ Cell_voltage_min_cmu_index m0 : 51|7@0+ (1,0) [0|0] "-"  BMU_ID_0
 SG_ Cell_temp_maximum_value m1 : 15|8@0+ (1,-50) [0|0] "ºC"  BMU_ID_0
 SG_ Cell_temp_minimum_value m1 : 23|8@0+ (1,-50) [0|0] "ºC"  BMU_ID_0
 SG_ Cell_temp_average_value m1 : 31|8@0+ (1,-50) [0|0] "ºC"  BMU_ID_0
 SG_ Cell_temp_max_cmu_index m1 : 39|7@0+ (1,0) [0|0] ""  BMU_ID_0
 SG_ Cell_temp_max_channel_index m1 : 32|5@0+ (1,0) [0|0] ""  BMU_ID_0
 SG_ Cell_temp_min_cmu_index m1 : 43|7@0+ (1,0) [0|0] ""  BMU_ID_0
 SG_ Cell_temp_min_channel_index m1 : 52|5@0+ (1,0) [0|0] ""  BMU_ID_0
 SG_ Reserved m1 : 63|8@0+ (1,0) [0|0] ""  BMU_ID_0
 SG_ Balancing_temp_maximum_value m2 : 15|8@0+ (1,-50) [0|0] "ºC"  BMU_ID_0
 SG_ Balancing_temp_minimum_value m2 : 23|8@0+ (1,-50) [0|0] "ºC"  BMU_ID_0
 SG_ Balancing_temp_average_value m2 : 31|8@0+ (1,-50) [0|0] "ºC"  BMU_ID_0
 SG_ Balancing_temp_max_cmu_index m2 : 39|8@0+ (1,0) [0|0] ""  BMU_ID_0
 SG_ Balancing_temp_min_cmu_index m2 : 47|8@0+ (1,0) [0|0] ""  BMU_ID_0
 SG_ Cell_voltage_average_value m2 : 55|16@0+ (1,0) [0|0] "mV"  BMU_ID_0
 SG_ Max_cell_voltage_balancing m3 : 15|16@0+ (1,0) [0|0] "mV"  BMU_ID_0
 SG_ Min_cell_voltage_balancing m3 : 31|16@0+ (1,0) [0|0] "mV"  BMU_ID_0
 SG_ Max_cell_voltage_balancing_ID m3 : 47|12@0+ (1,0) [0|0] "-"  BMU_ID_0
 SG_ Min_cell_voltage_balancing_ID m3 : 51|12@0+ (1,0) [0|0] "-"  BMU_ID_0

BO_ 1415 wBMU_ID_7_msg_08_status: 8 BMU_ID_7
 SG_ Content_ID M : 7|8@0+ (1,0) [0|0] ""  BMU_ID_0
 SG_ Cell_voltage_maximum_value m0 : 15|16@0+ (1,0) [0|0] "mV"  BMU_ID_0
 SG_ Cell_voltage_minimum_value m0 : 31|16@0+ (1,0) [0|0] "mV"  BMU_ID_0
 SG_ Cell_voltage_max_channel_index m0 : 40|5@0+ (1,0) [0|0] "-"  BMU_ID_0
 SG_ Cell_voltage_max_cmu_index m0 : 47|7@0+ (1,0) [0|0] "-"  BMU_ID_0
 SG_ Cell_voltage_min_channel_index m0 : 60|5@0+ (1,0) [0|0] "-"  BMU_ID_0
 SG_ Cell_voltage_min_cmu_index m0 : 51|7@0+ (1,0) [0|0] "-"  BMU_ID_0
 SG_ Cell_temp_maximum_value m1 : 15|8@0+ (1,-50) [0|0] "ºC"  BMU_ID_0
 SG_ Cell_temp_minimum_value m1 : 23|8@0+ (1,-50) [0|0] "ºC"  BMU_ID_0
 SG_ Cell_temp_average_value m1 : 31|8@0+ (1,-50) [0|0] "ºC"  BMU_ID_0
 SG_ Cell_temp_max_cmu_index m1 : 39|7@0+ (1,0) [0|0] ""  BMU_ID_0
 SG_ Cell_temp_max_channel_index m1 : 32|5@0+ (1,0) [0|0] ""  BMU_ID_0
 SG_ Cell_temp_min_cmu_index m1 : 43|7@0+ (1,0) [0|0] ""  BMU_ID_0
 SG_ Cell_temp_min_channel_index m1 : 52|5@0+ (1,0) [0|0] ""  BMU_ID_0
 SG_ Reserved m1 : 63|8@0+ (1,0) [0|0] ""  BMU_ID_0
 SG_ Balancing_temp_maximum_value m2 : 15|8@0+ (1,-50) [0|0] "ºC"  BMU_ID_0
 SG_ Balancing_temp_minimum_value m2 : 23|8@0+ (1,-50) [0|0] "ºC"  BMU_ID_0
 SG_ Balancing_temp_average_value m2 : 31|8@0+ (1,-50) [0|0] "ºC"  BMU_ID_0
 SG_ Balancing_temp_max_cmu_index m2 : 39|8@0+ (1,0) [0|0] ""  BMU_ID_0
 SG_ Balancing_temp_min_cmu_index m2 : 47|8@0+ (1,0) [0|0] ""  BMU_ID_0
 SG_ Cell_voltage_average_value m2 : 55|16@0+ (1,0) [0|0] "mV"  BMU_ID_0
 SG_ Max_cell_voltage_balancing m3 : 15|16@0+ (1,0) [0|0] "mV"  BMU_ID_0
 SG_ Min_cell_voltage_balancing m3 : 31|16@0+ (1,0) [0|0] "mV"  BMU_ID_0
 SG_ Max_cell_voltage_balancing_ID m3 : 47|12@0+ (1,0) [0|0] "-"  BMU_ID_0
 SG_ Min_cell_voltage_balancing_ID m3 : 51|12@0+ (1,0) [0|0] "-"  BMU_ID_0

BO_ 1416 wBMU_ID_8_msg_08_status: 8 BMU_ID_8
 SG_ Content_ID M : 7|8@0+ (1,0) [0|0] ""  BMU_ID_0
 SG_ Cell_voltage_maximum_value m0 : 15|16@0+ (1,0) [0|0] "mV"  BMU_ID_0
 SG_ Cell_voltage_minimum_value m0 : 31|16@0+ (1,0) [0|0] "mV"  BMU_ID_0
 SG_ Cell_voltage_max_channel_index m0 : 40|5@0+ (1,0) [0|0] "-"  BMU_ID_0
 SG_ Cell_voltage_max_cmu_index m0 : 47|7@0+ (1,0) [0|0] "-"  BMU_ID_0
 SG_ Cell_voltage_min_channel_index m0 : 60|5@0+ (1,0) [0|0] "-"  BMU_ID_0
 SG_ Cell_voltage_min_cmu_index m0 : 51|7@0+ (1,0) [0|0] "-"  BMU_ID_0
 SG_ Cell_temp_maximum_value m1 : 15|8@0+ (1,-50) [0|0] "ºC"  BMU_ID_0
 SG_ Cell_temp_minimum_value m1 : 23|8@0+ (1,-50) [0|0] "ºC"  BMU_ID_0
 SG_ Cell_temp_average_value m1 : 31|8@0+ (1,-50) [0|0] "ºC"  BMU_ID_0
 SG_ Cell_temp_max_cmu_index m1 : 39|7@0+ (1,0) [0|0] ""  BMU_ID_0
 SG_ Cell_temp_max_channel_index m1 : 32|5@0+ (1,0) [0|0] ""  BMU_ID_0
 SG_ Cell_temp_min_cmu_index m1 : 43|7@0+ (1,0) [0|0] ""  BMU_ID_0
 SG_ Cell_temp_min_channel_index m1 : 52|5@0+ (1,0) [0|0] ""  BMU_ID_0
 SG_ Reserved m1 : 63|8@0+ (1,0) [0|0] ""  BMU_ID_0
 SG_ Balancing_temp_maximum_value m2 : 15|8@0+ (1,-50) [0|0] "ºC"  BMU_ID_0
 SG_ Balancing_temp_minimum_value m2 : 23|8@0+ (1,-50) [0|0] "ºC"  BMU_ID_0
 SG_ Balancing_temp_average_value m2 : 31|8@0+ (1,-50) [0|0] "ºC"  BMU_ID_0
 SG_ Balancing_temp_max_cmu_index m2 : 39|8@0+ (1,0) [0|0] ""  BMU_ID_0
 SG_ Balancing_temp_min_cmu_index m2 : 47|8@0+ (1,0) [0|0] ""  BMU_ID_0
 SG_ Cell_voltage_average_value m2 : 55|16@0+ (1,0) [0|0] "mV"  BMU_ID_0
 SG_ Max_cell_voltage_balancing m3 : 15|16@0+ (1,0) [0|0] "mV"  BMU_ID_0
 SG_ Min_cell_voltage_balancing m3 : 31|16@0+ (1,0) [0|0] "mV"  BMU_ID_0
 SG_ Max_cell_voltage_balancing_ID m3 : 47|12@0+ (1,0) [0|0] "-"  BMU_ID_0
 SG_ Min_cell_voltage_balancing_ID m3 : 51|12@0+ (1,0) [0|0] "-"  BMU_ID_0

BO_ 1417 wBMU_ID_9_msg_08_status: 8 BMU_ID_9
 SG_ Content_ID M : 7|8@0+ (1,0) [0|0] ""  BMU_ID_0
 SG_ Cell_voltage_maximum_value m0 : 15|16@0+ (1,0) [0|0] "mV"  BMU_ID_0
 SG_ Cell_voltage_minimum_value m0 : 31|16@0+ (1,0) [0|0] "mV"  BMU_ID_0
 SG_ Cell_voltage_max_channel_index m0 : 40|5@0+ (1,0) [0|0] "-"  BMU_ID_0
 SG_ Cell_voltage_max_cmu_index m0 : 47|7@0+ (1,0) [0|0] "-"  BMU_ID_0
 SG_ Cell_voltage_min_channel_index m0 : 60|5@0+ (1,0) [0|0] "-"  BMU_ID_0
 SG_ Cell_voltage_min_cmu_index m0 : 51|7@0+ (1,0) [0|0] "-"  BMU_ID_0
 SG_ Cell_temp_maximum_value m1 : 15|8@0+ (1,-50) [0|0] "ºC"  BMU_ID_0
 SG_ Cell_temp_minimum_value m1 : 23|8@0+ (1,-50) [0|0] "ºC"  BMU_ID_0
 SG_ Cell_temp_average_value m1 : 31|8@0+ (1,-50) [0|0] "ºC"  BMU_ID_0
 SG_ Cell_temp_max_cmu_index m1 : 39|7@0+ (1,0) [0|0] ""  BMU_ID_0
 SG_ Cell_temp_max_channel_index m1 : 32|5@0+ (1,0) [0|0] ""  BMU_ID_0
 SG_ Cell_temp_min_cmu_index m1 : 43|7@0+ (1,0) [0|0] ""  BMU_ID_0
 SG_ Cell_temp_min_channel_index m1 : 52|5@0+ (1,0) [0|0] ""  BMU_ID_0
 SG_ Reserved m1 : 63|8@0+ (1,0) [0|0] ""  BMU_ID_0
 SG_ Balancing_temp_maximum_value m2 : 15|8@0+ (1,-50) [0|0] "ºC"  BMU_ID_0
 SG_ Balancing_temp_minimum_value m2 : 23|8@0+ (1,-50) [0|0] "ºC"  BMU_ID_0
 SG_ Balancing_temp_average_value m2 : 31|8@0+ (1,-50) [0|0] "ºC"  BMU_ID_0
 SG_ Balancing_temp_max_cmu_index m2 : 39|8@0+ (1,0) [0|0] ""  BMU_ID_0
 SG_ Balancing_temp_min_cmu_index m2 : 47|8@0+ (1,0) [0|0] ""  BMU_ID_0
 SG_ Cell_voltage_average_value m2 : 55|16@0+ (1,0) [0|0] "mV"  BMU_ID_0
 SG_ Max_cell_voltage_balancing m3 : 15|16@0+ (1,0) [0|0] "mV"  BMU_ID_0
 SG_ Min_cell_voltage_balancing m3 : 31|16@0+ (1,0) [0|0] "mV"  BMU_ID_0
 SG_ Max_cell_voltage_balancing_ID m3 : 47|12@0+ (1,0) [0|0] "-"  BMU_ID_0
 SG_ Min_cell_voltage_balancing_ID m3 : 51|12@0+ (1,0) [0|0] "-"  BMU_ID_0

BO_ 1418 wBMU_ID_10_msg_08_status: 8 BMU_ID_10
 SG_ Content_ID M : 7|8@0+ (1,0) [0|0] ""  BMU_ID_0
 SG_ Cell_voltage_maximum_value m0 : 15|16@0+ (1,0) [0|0] "mV"  BMU_ID_0
 SG_ Cell_voltage_minimum_value m0 : 31|16@0+ (1,0) [0|0] "mV"  BMU_ID_0
 SG_ Cell_voltage_max_channel_index m0 : 40|5@0+ (1,0) [0|0] "-"  BMU_ID_0
 SG_ Cell_voltage_max_cmu_index m0 : 47|7@0+ (1,0) [0|0] "-"  BMU_ID_0
 SG_ Cell_voltage_min_channel_index m0 : 60|5@0+ (1,0) [0|0] "-"  BMU_ID_0
 SG_ Cell_voltage_min_cmu_index m0 : 51|7@0+ (1,0) [0|0] "-"  BMU_ID_0
 SG_ Cell_temp_maximum_value m1 : 15|8@0+ (1,-50) [0|0] "ºC"  BMU_ID_0
 SG_ Cell_temp_minimum_value m1 : 23|8@0+ (1,-50) [0|0] "ºC"  BMU_ID_0
 SG_ Cell_temp_average_value m1 : 31|8@0+ (1,-50) [0|0] "ºC"  BMU_ID_0
 SG_ Cell_temp_max_cmu_index m1 : 39|7@0+ (1,0) [0|0] ""  BMU_ID_0
 SG_ Cell_temp_max_channel_index m1 : 32|5@0+ (1,0) [0|0] ""  BMU_ID_0
 SG_ Cell_temp_min_cmu_index m1 : 43|7@0+ (1,0) [0|0] ""  BMU_ID_0
 SG_ Cell_temp_min_channel_index m1 : 52|5@0+ (1,0) [0|0] ""  BMU_ID_0
 SG_ Reserved m1 : 63|8@0+ (1,0) [0|0] ""  BMU_ID_0
 SG_ Balancing_temp_maximum_value m2 : 15|8@0+ (1,-50) [0|0] "ºC"  BMU_ID_0
 SG_ Balancing_temp_minimum_value m2 : 23|8@0+ (1,-50) [0|0] "ºC"  BMU_ID_0
 SG_ Balancing_temp_average_value m2 : 31|8@0+ (1,-50) [0|0] "ºC"  BMU_ID_0
 SG_ Balancing_temp_max_cmu_index m2 : 39|8@0+ (1,0) [0|0] ""  BMU_ID_0
 SG_ Balancing_temp_min_cmu_index m2 : 47|8@0+ (1,0) [0|0] ""  BMU_ID_0
 SG_ Cell_voltage_average_value m2 : 55|16@0+ (1,0) [0|0] "mV"  BMU_ID_0
 SG_ Max_cell_voltage_balancing m3 : 15|16@0+ (1,0) [0|0] "mV"  BMU_ID_0
 SG_ Min_cell_voltage_balancing m3 : 31|16@0+ (1,0) [0|0] "mV"  BMU_ID_0
 SG_ Max_cell_voltage_balancing_ID m3 : 47|12@0+ (1,0) [0|0] "-"  BMU_ID_0
 SG_ Min_cell_voltage_balancing_ID m3 : 51|12@0+ (1,0) [0|0] "-"  BMU_ID_0

BO_ 1419 wBMU_ID_11_msg_08_status: 8 BMU_ID_11
 SG_ Content_ID M : 7|8@0+ (1,0) [0|0] ""  BMU_ID_0
 SG_ Cell_voltage_maximum_value m0 : 15|16@0+ (1,0) [0|0] "mV"  BMU_ID_0
 SG_ Cell_voltage_minimum_value m0 : 31|16@0+ (1,0) [0|0] "mV"  BMU_ID_0
 SG_ Cell_voltage_max_channel_index m0 : 40|5@0+ (1,0) [0|0] "-"  BMU_ID_0
 SG_ Cell_voltage_max_cmu_index m0 : 47|7@0+ (1,0) [0|0] "-"  BMU_ID_0
 SG_ Cell_voltage_min_channel_index m0 : 60|5@0+ (1,0) [0|0] "-"  BMU_ID_0
 SG_ Cell_voltage_min_cmu_index m0 : 51|7@0+ (1,0) [0|0] "-"  BMU_ID_0
 SG_ Cell_temp_maximum_value m1 : 15|8@0+ (1,-50) [0|0] "ºC"  BMU_ID_0
 SG_ Cell_temp_minimum_value m1 : 23|8@0+ (1,-50) [0|0] "ºC"  BMU_ID_0
 SG_ Cell_temp_average_value m1 : 31|8@0+ (1,-50) [0|0] "ºC"  BMU_ID_0
 SG_ Cell_temp_max_cmu_index m1 : 39|7@0+ (1,0) [0|0] ""  BMU_ID_0
 SG_ Cell_temp_max_channel_index m1 : 32|5@0+ (1,0) [0|0] ""  BMU_ID_0
 SG_ Cell_temp_min_cmu_index m1 : 43|7@0+ (1,0) [0|0] ""  BMU_ID_0
 SG_ Cell_temp_min_channel_index m1 : 52|5@0+ (1,0) [0|0] ""  BMU_ID_0
 SG_ Reserved m1 : 63|8@0+ (1,0) [0|0] ""  BMU_ID_0
 SG_ Balancing_temp_maximum_value m2 : 15|8@0+ (1,-50) [0|0] "ºC"  BMU_ID_0
 SG_ Balancing_temp_minimum_value m2 : 23|8@0+ (1,-50) [0|0] "ºC"  BMU_ID_0
 SG_ Balancing_temp_average_value m2 : 31|8@0+ (1,-50) [0|0] "ºC"  BMU_ID_0
 SG_ Balancing_temp_max_cmu_index m2 : 39|8@0+ (1,0) [0|0] ""  BMU_ID_0
 SG_ Balancing_temp_min_cmu_index m2 : 47|8@0+ (1,0) [0|0] ""  BMU_ID_0
 SG_ Cell_voltage_average_value m2 : 55|16@0+ (1,0) [0|0] "mV"  BMU_ID_0
 SG_ Max_cell_voltage_balancing m3 : 15|16@0+ (1,0) [0|0] "mV"  BMU_ID_0
 SG_ Min_cell_voltage_balancing m3 : 31|16@0+ (1,0) [0|0] "mV"  BMU_ID_0
 SG_ Max_cell_voltage_balancing_ID m3 : 47|12@0+ (1,0) [0|0] "-"  BMU_ID_0
 SG_ Min_cell_voltage_balancing_ID m3 : 51|12@0+ (1,0) [0|0] "-"  BMU_ID_0

BO_ 1420 wBMU_ID_12_msg_08_status: 8 BMU_ID_12
 SG_ Content_ID M : 7|8@0+ (1,0) [0|0] ""  BMU_ID_0
 SG_ Cell_voltage_maximum_value m0 : 15|16@0+ (1,0) [0|0] "mV"  BMU_ID_0
 SG_ Cell_voltage_minimum_value m0 : 31|16@0+ (1,0) [0|0] "mV"  BMU_ID_0
 SG_ Cell_voltage_max_channel_index m0 : 40|5@0+ (1,0) [0|0] "-"  BMU_ID_0
 SG_ Cell_voltage_max_cmu_index m0 : 47|7@0+ (1,0) [0|0] "-"  BMU_ID_0
 SG_ Cell_voltage_min_channel_index m0 : 60|5@0+ (1,0) [0|0] "-"  BMU_ID_0
 SG_ Cell_voltage_min_cmu_index m0 : 51|7@0+ (1,0) [0|0] "-"  BMU_ID_0
 SG_ Cell_temp_maximum_value m1 : 15|8@0+ (1,-50) [0|0] "ºC"  BMU_ID_0
 SG_ Cell_temp_minimum_value m1 : 23|8@0+ (1,-50) [0|0] "ºC"  BMU_ID_0
 SG_ Cell_temp_average_value m1 : 31|8@0+ (1,-50) [0|0] "ºC"  BMU_ID_0
 SG_ Cell_temp_max_cmu_index m1 : 39|7@0+ (1,0) [0|0] ""  BMU_ID_0
 SG_ Cell_temp_max_channel_index m1 : 32|5@0+ (1,0) [0|0] ""  BMU_ID_0
 SG_ Cell_temp_min_cmu_index m1 : 43|7@0+ (1,0) [0|0] ""  BMU_ID_0
 SG_ Cell_temp_min_channel_index m1 : 52|5@0+ (1,0) [0|0] ""  BMU_ID_0
 SG_ Reserved m1 : 63|8@0+ (1,0) [0|0] ""  BMU_ID_0
 SG_ Balancing_temp_maximum_value m2 : 15|8@0+ (1,-50) [0|0] "ºC"  BMU_ID_0
 SG_ Balancing_temp_minimum_value m2 : 23|8@0+ (1,-50) [0|0] "ºC"  BMU_ID_0
 SG_ Balancing_temp_average_value m2 : 31|8@0+ (1,-50) [0|0] "ºC"  BMU_ID_0
 SG_ Balancing_temp_max_cmu_index m2 : 39|8@0+ (1,0) [0|0] ""  BMU_ID_0
 SG_ Balancing_temp_min_cmu_index m2 : 47|8@0+ (1,0) [0|0] ""  BMU_ID_0
 SG_ Cell_voltage_average_value m2 : 55|16@0+ (1,0) [0|0] "mV"  BMU_ID_0
 SG_ Max_cell_voltage_balancing m3 : 15|16@0+ (1,0) [0|0] "mV"  BMU_ID_0
 SG_ Min_cell_voltage_balancing m3 : 31|16@0+ (1,0) [0|0] "mV"  BMU_ID_0
 SG_ Max_cell_voltage_balancing_ID m3 : 47|12@0+ (1,0) [0|0] "-"  BMU_ID_0
 SG_ Min_cell_voltage_balancing_ID m3 : 51|12@0+ (1,0) [0|0] "-"  BMU_ID_0

BO_ 1421 wBMU_ID_13_msg_08_status: 8 BMU_ID_13
 SG_ Content_ID M : 7|8@0+ (1,0) [0|0] ""  BMU_ID_0
 SG_ Cell_voltage_maximum_value m0 : 15|16@0+ (1,0) [0|0] "mV"  BMU_ID_0
 SG_ Cell_voltage_minimum_value m0 : 31|16@0+ (1,0) [0|0] "mV"  BMU_ID_0
 SG_ Cell_voltage_max_channel_index m0 : 40|5@0+ (1,0) [0|0] "-"  BMU_ID_0
 SG_ Cell_voltage_max_cmu_index m0 : 47|7@0+ (1,0) [0|0] "-"  BMU_ID_0
 SG_ Cell_voltage_min_channel_index m0 : 60|5@0+ (1,0) [0|0] "-"  BMU_ID_0
 SG_ Cell_voltage_min_cmu_index m0 : 51|7@0+ (1,0) [0|0] "-"  BMU_ID_0
 SG_ Cell_temp_maximum_value m1 : 15|8@0+ (1,-50) [0|0] "ºC"  BMU_ID_0
 SG_ Cell_temp_minimum_value m1 : 23|8@0+ (1,-50) [0|0] "ºC"  BMU_ID_0
 SG_ Cell_temp_average_value m1 : 31|8@0+ (1,-50) [0|0] "ºC"  BMU_ID_0
 SG_ Cell_temp_max_cmu_index m1 : 39|7@0+ (1,0) [0|0] ""  BMU_ID_0
 SG_ Cell_temp_max_channel_index m1 : 32|5@0+ (1,0) [0|0] ""  BMU_ID_0
 SG_ Cell_temp_min_cmu_index m1 : 43|7@0+ (1,0) [0|0] ""  BMU_ID_0
 SG_ Cell_temp_min_channel_index m1 : 52|5@0+ (1,0) [0|0] ""  BMU_ID_0
 SG_ Reserved m1 : 63|8@0+ (1,0) [0|0] ""  BMU_ID_0
 SG_ Balancing_temp_maximum_value m2 : 15|8@0+ (1,-50) [0|0] "ºC"  BMU_ID_0
 SG_ Balancing_temp_minimum_value m2 : 23|8@0+ (1,-50) [0|0] "ºC"  BMU_ID_0
 SG_ Balancing_temp_average_value m2 : 31|8@0+ (1,-50) [0|0] "ºC"  BMU_ID_0
 SG_ Balancing_temp_max_cmu_index m2 : 39|8@0+ (1,0) [0|0] ""  BMU_ID_0
 SG_ Balancing_temp_min_cmu_index m2 : 47|8@0+ (1,0) [0|0] ""  BMU_ID_0
 SG_ Cell_voltage_average_value m2 : 55|16@0+ (1,0) [0|0] "mV"  BMU_ID_0
 SG_ Max_cell_voltage_balancing m3 : 15|16@0+ (1,0) [0|0] "mV"  BMU_ID_0
 SG_ Min_cell_voltage_balancing m3 : 31|16@0+ (1,0) [0|0] "mV"  BMU_ID_0
 SG_ Max_cell_voltage_balancing_ID m3 : 47|12@0+ (1,0) [0|0] "-"  BMU_ID_0
 SG_ Min_cell_voltage_balancing_ID m3 : 51|12@0+ (1,0) [0|0] "-"  BMU_ID_0

BO_ 1422 wBMU_ID_14_msg_08_status: 8 BMU_ID_14
 SG_ Content_ID M : 7|8@0+ (1,0) [0|0] ""  BMU_ID_0
 SG_ Cell_voltage_maximum_value m0 : 15|16@0+ (1,0) [0|0] "mV"  BMU_ID_0
 SG_ Cell_voltage_minimum_value m0 : 31|16@0+ (1,0) [0|0] "mV"  BMU_ID_0
 SG_ Cell_voltage_max_channel_index m0 : 40|5@0+ (1,0) [0|0] "-"  BMU_ID_0
 SG_ Cell_voltage_max_cmu_index m0 : 47|7@0+ (1,0) [0|0] "-"  BMU_ID_0
 SG_ Cell_voltage_min_channel_index m0 : 60|5@0+ (1,0) [0|0] "-"  BMU_ID_0
 SG_ Cell_voltage_min_cmu_index m0 : 51|7@0+ (1,0) [0|0] "-"  BMU_ID_0
 SG_ Cell_temp_maximum_value m1 : 15|8@0+ (1,-50) [0|0] "ºC"  BMU_ID_0
 SG_ Cell_temp_minimum_value m1 : 23|8@0+ (1,-50) [0|0] "ºC"  BMU_ID_0
 SG_ Cell_temp_average_value m1 : 31|8@0+ (1,-50) [0|0] "ºC"  BMU_ID_0
 SG_ Cell_temp_max_cmu_index m1 : 39|7@0+ (1,0) [0|0] ""  BMU_ID_0
 SG_ Cell_temp_max_channel_index m1 : 32|5@0+ (1,0) [0|0] ""  BMU_ID_0
 SG_ Cell_temp_min_cmu_index m1 : 43|7@0+ (1,0) [0|0] ""  BMU_ID_0
 SG_ Cell_temp_min_channel_index m1 : 52|5@0+ (1,0) [0|0] ""  BMU_ID_0
 SG_ Reserved m1 : 63|8@0+ (1,0) [0|0] ""  BMU_ID_0
 SG_ Balancing_temp_maximum_value m2 : 15|8@0+ (1,-50) [0|0] "ºC"  BMU_ID_0
 SG_ Balancing_temp_minimum_value m2 : 23|8@0+ (1,-50) [0|0] "ºC"  BMU_ID_0
 SG_ Balancing_temp_average_value m2 : 31|8@0+ (1,-50) [0|0] "ºC"  BMU_ID_0
 SG_ Balancing_temp_max_cmu_index m2 : 39|8@0+ (1,0) [0|0] ""  BMU_ID_0
 SG_ Balancing_temp_min_cmu_index m2 : 47|8@0+ (1,0) [0|0] ""  BMU_ID_0
 SG_ Cell_voltage_average_value m2 : 55|16@0+ (1,0) [0|0] "mV"  BMU_ID_0
 SG_ Max_cell_voltage_balancing m3 : 15|16@0+ (1,0) [0|0] "mV"  BMU_ID_0
 SG_ Min_cell_voltage_balancing m3 : 31|16@0+ (1,0) [0|0] "mV"  BMU_ID_0
 SG_ Max_cell_voltage_balancing_ID m3 : 47|12@0+ (1,0) [0|0] "-"  BMU_ID_0
 SG_ Min_cell_voltage_balancing_ID m3 : 51|12@0+ (1,0) [0|0] "-"  BMU_ID_0

BO_ 1423 wBMU_ID_15_msg_08_status: 8 BMU_ID_15
 SG_ Content_ID M : 7|8@0+ (1,0) [0|0] ""  BMU_ID_0
 SG_ Cell_voltage_maximum_value m0 : 15|16@0+ (1,0) [0|0] "mV"  BMU_ID_0
 SG_ Cell_voltage_minimum_value m0 : 31|16@0+ (1,0) [0|0] "mV"  BMU_ID_0
 SG_ Cell_voltage_max_channel_index m0 : 40|5@0+ (1,0) [0|0] "-"  BMU_ID_0
 SG_ Cell_voltage_max_cmu_index m0 : 47|7@0+ (1,0) [0|0] "-"  BMU_ID_0
 SG_ Cell_voltage_min_channel_index m0 : 60|5@0+ (1,0) [0|0] "-"  BMU_ID_0
 SG_ Cell_voltage_min_cmu_index m0 : 51|7@0+ (1,0) [0|0] "-"  BMU_ID_0
 SG_ Cell_temp_maximum_value m1 : 15|8@0+ (1,-50) [0|0] "ºC"  BMU_ID_0
 SG_ Cell_temp_minimum_value m1 : 23|8@0+ (1,-50) [0|0] "ºC"  BMU_ID_0
 SG_ Cell_temp_average_value m1 : 31|8@0+ (1,-50) [0|0] "ºC"  BMU_ID_0
 SG_ Cell_temp_max_cmu_index m1 : 39|7@0+ (1,0) [0|0] ""  BMU_ID_0
 SG_ Cell_temp_max_channel_index m1 : 32|5@0+ (1,0) [0|0] ""  BMU_ID_0
 SG_ Cell_temp_min_cmu_index m1 : 43|7@0+ (1,0) [0|0] ""  BMU_ID_0
 SG_ Cell_temp_min_channel_index m1 : 52|5@0+ (1,0) [0|0] ""  BMU_ID_0
 SG_ Reserved m1 : 63|8@0+ (1,0) [0|0] ""  BMU_ID_0
 SG_ Balancing_temp_maximum_value m2 : 15|8@0+ (1,-50) [0|0] "ºC"  BMU_ID_0
 SG_ Balancing_temp_minimum_value m2 : 23|8@0+ (1,-50) [0|0] "ºC"  BMU_ID_0
 SG_ Balancing_temp_average_value m2 : 31|8@0+ (1,-50) [0|0] "ºC"  BMU_ID_0
 SG_ Balancing_temp_max_cmu_index m2 : 39|8@0+ (1,0) [0|0] ""  BMU_ID_0
 SG_ Balancing_temp_min_cmu_index m2 : 47|8@0+ (1,0) [0|0] ""  BMU_ID_0
 SG_ Cell_voltage_average_value m2 : 55|16@0+ (1,0) [0|0] "mV"  BMU_ID_0
 SG_ Max_cell_voltage_balancing m3 : 15|16@0+ (1,0) [0|0] "mV"  BMU_ID_0
 SG_ Min_cell_voltage_balancing m3 : 31|16@0+ (1,0) [0|0] "mV"  BMU_ID_0
 SG_ Max_cell_voltage_balancing_ID m3 : 47|12@0+ (1,0) [0|0] "-"  BMU_ID_0
 SG_ Min_cell_voltage_balancing_ID m3 : 51|12@0+ (1,0) [0|0] "-"  BMU_ID_0

BO_ 1440 wBMU_ID_0_msg_10_sensors: 8 BMU_ID_0
 SG_ Content_ID M : 7|8@0+ (1,0) [0|0] ""  BMU_ID_0
 SG_ IMD_resistance_value m0 : 15|16@0+ (1,0) [0|0] "kOhm"  BMU_ID_0
 SG_ IMD_status m0 : 31|8@0+ (1,0) [0|0] ""  BMU_ID_0
 SG_ Voltage_sensor_battery_voltage m1 : 15|16@0+ (0.1,-3200) [0|0] "V"  BMU_ID_0
 SG_ Voltage_sensor_link_voltage m1 : 31|16@0+ (0.1,-3200) [0|0] "V"  BMU_ID_0
 SG_ Voltage_sensor_fuse_voltage m1 : 47|16@0+ (0.1,-3200) [0|0] "V"  BMU_ID_0
 SG_ Voltage_sensor_status m1 : 59|4@0+ (1,0) [0|0] ""  BMU_ID_0
 SG_ Control_unit_temperature m2 : 15|8@0+ (1,-50) [0|0] "ºC "  BMU_ID_0
 SG_ Control_unit_supply_voltage m2 : 23|8@0+ (0.2,0) [0|0] "V"  BMU_ID_0
 SG_ Outputs_supply_voltage m2 : 31|8@0+ (0.2,0) [0|0] "V"  BMU_ID_0
 SG_ External_temperature_1 m2 : 39|8@0+ (1,-50) [0|0] "ºC "  BMU_ID_0
 SG_ External_temperature_2 m2 : 47|8@0+ (1,-50) [0|0] "ºC "  BMU_ID_0
 SG_ External_temperature_3 m2 : 55|8@0+ (1,-50) [0|0] "ºC "  BMU_ID_0
 SG_ External_temperature_4 m2 : 63|8@0+ (1,-50) [0|0] "ºC"  BMU_ID_0

BO_ 1441 wBMU_ID_1_msg_10_sensors: 8 BMU_ID_1
 SG_ Content_ID M : 7|8@0+ (1,0) [0|0] ""  BMU_ID_0
 SG_ IMD_resistance_value m0 : 15|16@0+ (1,0) [0|0] "kOhm"  BMU_ID_0
 SG_ IMD_status m0 : 31|8@0+ (1,0) [0|0] ""  BMU_ID_0
 SG_ Voltage_sensor_battery_voltage m1 : 15|16@0+ (0.1,-3200) [0|0] "V"  BMU_ID_0
 SG_ Voltage_sensor_link_voltage m1 : 31|16@0+ (0.1,-3200) [0|0] "V"  BMU_ID_0
 SG_ Voltage_sensor_fuse_voltage m1 : 47|16@0+ (0.1,-3200) [0|0] "V"  BMU_ID_0
 SG_ Voltage_sensor_status m1 : 59|4@0+ (1,0) [0|0] ""  BMU_ID_0
 SG_ Control_unit_temperature m2 : 15|8@0+ (1,-50) [0|0] "ºC "  BMU_ID_0
 SG_ Control_unit_supply_voltage m2 : 23|8@0+ (0.2,0) [0|0] "V"  BMU_ID_0
 SG_ Outputs_supply_voltage m2 : 31|8@0+ (0.2,0) [0|0] "V"  BMU_ID_0
 SG_ External_temperature_1 m2 : 39|8@0+ (1,-50) [0|0] "ºC "  BMU_ID_0
 SG_ External_temperature_2 m2 : 47|8@0+ (1,-50) [0|0] "ºC "  BMU_ID_0
 SG_ External_temperature_3 m2 : 55|8@0+ (1,-50) [0|0] "ºC "  BMU_ID_0
 SG_ External_temperature_4 m2 : 63|8@0+ (1,-50) [0|0] "ºC"  BMU_ID_0

BO_ 1442 wBMU_ID_2_msg_10_sensors: 8 BMU_ID_2
 SG_ Content_ID M : 7|8@0+ (1,0) [0|0] ""  BMU_ID_0
 SG_ IMD_resistance_value m0 : 15|16@0+ (1,0) [0|0] "kOhm"  BMU_ID_0
 SG_ IMD_status m0 : 31|8@0+ (1,0) [0|0] ""  BMU_ID_0
 SG_ Voltage_sensor_battery_voltage m1 : 15|16@0+ (0.1,-3200) [0|0] "V"  BMU_ID_0
 SG_ Voltage_sensor_link_voltage m1 : 31|16@0+ (0.1,-3200) [0|0] "V"  BMU_ID_0
 SG_ Voltage_sensor_fuse_voltage m1 : 47|16@0+ (0.1,-3200) [0|0] "V"  BMU_ID_0
 SG_ Voltage_sensor_status m1 : 59|4@0+ (1,0) [0|0] ""  BMU_ID_0
 SG_ Control_unit_temperature m2 : 15|8@0+ (1,-50) [0|0] "ºC "  BMU_ID_0
 SG_ Control_unit_supply_voltage m2 : 23|8@0+ (0.2,0) [0|0] "V"  BMU_ID_0
 SG_ Outputs_supply_voltage m2 : 31|8@0+ (0.2,0) [0|0] "V"  BMU_ID_0
 SG_ External_temperature_1 m2 : 39|8@0+ (1,-50) [0|0] "ºC "  BMU_ID_0
 SG_ External_temperature_2 m2 : 47|8@0+ (1,-50) [0|0] "ºC "  BMU_ID_0
 SG_ External_temperature_3 m2 : 55|8@0+ (1,-50) [0|0] "ºC "  BMU_ID_0
 SG_ External_temperature_4 m2 : 63|8@0+ (1,-50) [0|0] "ºC"  BMU_ID_0

BO_ 1443 wBMU_ID_3_msg_10_sensors: 8 BMU_ID_3
 SG_ Content_ID M : 7|8@0+ (1,0) [0|0] ""  BMU_ID_0
 SG_ IMD_resistance_value m0 : 15|16@0+ (1,0) [0|0] "kOhm"  BMU_ID_0
 SG_ IMD_status m0 : 31|8@0+ (1,0) [0|0] ""  BMU_ID_0
 SG_ Voltage_sensor_battery_voltage m1 : 15|16@0+ (0.1,-3200) [0|0] "V"  BMU_ID_0
 SG_ Voltage_sensor_link_voltage m1 : 31|16@0+ (0.1,-3200) [0|0] "V"  BMU_ID_0
 SG_ Voltage_sensor_fuse_voltage m1 : 47|16@0+ (0.1,-3200) [0|0] "V"  BMU_ID_0
 SG_ Voltage_sensor_status m1 : 59|4@0+ (1,0) [0|0] ""  BMU_ID_0
 SG_ Control_unit_temperature m2 : 15|8@0+ (1,-50) [0|0] "ºC "  BMU_ID_0
 SG_ Control_unit_supply_voltage m2 : 23|8@0+ (0.2,0) [0|0] "V"  BMU_ID_0
 SG_ Outputs_supply_voltage m2 : 31|8@0+ (0.2,0) [0|0] "V"  BMU_ID_0
 SG_ External_temperature_1 m2 : 39|8@0+ (1,-50) [0|0] "ºC "  BMU_ID_0
 SG_ External_temperature_2 m2 : 47|8@0+ (1,-50) [0|0] "ºC "  BMU_ID_0
 SG_ External_temperature_3 m2 : 55|8@0+ (1,-50) [0|0] "ºC "  BMU_ID_0
 SG_ External_temperature_4 m2 : 63|8@0+ (1,-50) [0|0] "ºC"  BMU_ID_0

BO_ 1444 wBMU_ID_4_msg_10_sensors: 8 BMU_ID_4
 SG_ Content_ID M : 7|8@0+ (1,0) [0|0] ""  BMU_ID_0
 SG_ IMD_resistance_value m0 : 15|16@0+ (1,0) [0|0] "kOhm"  BMU_ID_0
 SG_ IMD_status m0 : 31|8@0+ (1,0) [0|0] ""  BMU_ID_0
 SG_ Voltage_sensor_battery_voltage m1 : 15|16@0+ (0.1,-3200) [0|0] "V"  BMU_ID_0
 SG_ Voltage_sensor_link_voltage m1 : 31|16@0+ (0.1,-3200) [0|0] "V"  BMU_ID_0
 SG_ Voltage_sensor_fuse_voltage m1 : 47|16@0+ (0.1,-3200) [0|0] "V"  BMU_ID_0
 SG_ Voltage_sensor_status m1 : 59|4@0+ (1,0) [0|0] ""  BMU_ID_0
 SG_ Control_unit_temperature m2 : 15|8@0+ (1,-50) [0|0] "ºC "  BMU_ID_0
 SG_ Control_unit_supply_voltage m2 : 23|8@0+ (0.2,0) [0|0] "V"  BMU_ID_0
 SG_ Outputs_supply_voltage m2 : 31|8@0+ (0.2,0) [0|0] "V"  BMU_ID_0
 SG_ External_temperature_1 m2 : 39|8@0+ (1,-50) [0|0] "ºC "  BMU_ID_0
 SG_ External_temperature_2 m2 : 47|8@0+ (1,-50) [0|0] "ºC "  BMU_ID_0
 SG_ External_temperature_3 m2 : 55|8@0+ (1,-50) [0|0] "ºC "  BMU_ID_0
 SG_ External_temperature_4 m2 : 63|8@0+ (1,-50) [0|0] "ºC"  BMU_ID_0

BO_ 1445 wBMU_ID_5_msg_10_sensors: 8 BMU_ID_5
 SG_ Content_ID M : 7|8@0+ (1,0) [0|0] ""  BMU_ID_0
 SG_ IMD_resistance_value m0 : 15|16@0+ (1,0) [0|0] "kOhm"  BMU_ID_0
 SG_ IMD_status m0 : 31|8@0+ (1,0) [0|0] ""  BMU_ID_0
 SG_ Voltage_sensor_battery_voltage m1 : 15|16@0+ (0.1,-3200) [0|0] "V"  BMU_ID_0
 SG_ Voltage_sensor_link_voltage m1 : 31|16@0+ (0.1,-3200) [0|0] "V"  BMU_ID_0
 SG_ Voltage_sensor_fuse_voltage m1 : 47|16@0+ (0.1,-3200) [0|0] "V"  BMU_ID_0
 SG_ Voltage_sensor_status m1 : 59|4@0+ (1,0) [0|0] ""  BMU_ID_0
 SG_ Control_unit_temperature m2 : 15|8@0+ (1,-50) [0|0] "ºC "  BMU_ID_0
 SG_ Control_unit_supply_voltage m2 : 23|8@0+ (0.2,0) [0|0] "V"  BMU_ID_0
 SG_ Outputs_supply_voltage m2 : 31|8@0+ (0.2,0) [0|0] "V"  BMU_ID_0
 SG_ External_temperature_1 m2 : 39|8@0+ (1,-50) [0|0] "ºC "  BMU_ID_0
 SG_ External_temperature_2 m2 : 47|8@0+ (1,-50) [0|0] "ºC "  BMU_ID_0
 SG_ External_temperature_3 m2 : 55|8@0+ (1,-50) [0|0] "ºC "  BMU_ID_0
 SG_ External_temperature_4 m2 : 63|8@0+ (1,-50) [0|0] "ºC"  BMU_ID_0

BO_ 1446 wBMU_ID_6_msg_10_sensors: 8 BMU_ID_6
 SG_ Content_ID M : 7|8@0+ (1,0) [0|0] ""  BMU_ID_0
 SG_ IMD_resistance_value m0 : 15|16@0+ (1,0) [0|0] "kOhm"  BMU_ID_0
 SG_ IMD_status m0 : 31|8@0+ (1,0) [0|0] ""  BMU_ID_0
 SG_ Voltage_sensor_battery_voltage m1 : 15|16@0+ (0.1,-3200) [0|0] "V"  BMU_ID_0
 SG_ Voltage_sensor_link_voltage m1 : 31|16@0+ (0.1,-3200) [0|0] "V"  BMU_ID_0
 SG_ Voltage_sensor_fuse_voltage m1 : 47|16@0+ (0.1,-3200) [0|0] "V"  BMU_ID_0
 SG_ Voltage_sensor_status m1 : 59|4@0+ (1,0) [0|0] ""  BMU_ID_0
 SG_ Control_unit_temperature m2 : 15|8@0+ (1,-50) [0|0] "ºC "  BMU_ID_0
 SG_ Control_unit_supply_voltage m2 : 23|8@0+ (0.2,0) [0|0] "V"  BMU_ID_0
 SG_ Outputs_supply_voltage m2 : 31|8@0+ (0.2,0) [0|0] "V"  BMU_ID_0
 SG_ External_temperature_1 m2 : 39|8@0+ (1,-50) [0|0] "ºC "  BMU_ID_0
 SG_ External_temperature_2 m2 : 47|8@0+ (1,-50) [0|0] "ºC "  BMU_ID_0
 SG_ External_temperature_3 m2 : 55|8@0+ (1,-50) [0|0] "ºC "  BMU_ID_0
 SG_ External_temperature_4 m2 : 63|8@0+ (1,-50) [0|0] "ºC"  BMU_ID_0

BO_ 1447 wBMU_ID_7_msg_10_sensors: 8 BMU_ID_7
 SG_ Content_ID M : 7|8@0+ (1,0) [0|0] ""  BMU_ID_0
 SG_ IMD_resistance_value m0 : 15|16@0+ (1,0) [0|0] "kOhm"  BMU_ID_0
 SG_ IMD_status m0 : 31|8@0+ (1,0) [0|0] ""  BMU_ID_0
 SG_ Voltage_sensor_battery_voltage m1 : 15|16@0+ (0.1,-3200) [0|0] "V"  BMU_ID_0
 SG_ Voltage_sensor_link_voltage m1 : 31|16@0+ (0.1,-3200) [0|0] "V"  BMU_ID_0
 SG_ Voltage_sensor_fuse_voltage m1 : 47|16@0+ (0.1,-3200) [0|0] "V"  BMU_ID_0
 SG_ Voltage_sensor_status m1 : 59|4@0+ (1,0) [0|0] ""  BMU_ID_0
 SG_ Control_unit_temperature m2 : 15|8@0+ (1,-50) [0|0] "ºC "  BMU_ID_0
 SG_ Control_unit_supply_voltage m2 : 23|8@0+ (0.2,0) [0|0] "V"  BMU_ID_0
 SG_ Outputs_supply_voltage m2 : 31|8@0+ (0.2,0) [0|0] "V"  BMU_ID_0
 SG_ External_temperature_1 m2 : 39|8@0+ (1,-50) [0|0] "ºC "  BMU_ID_0
 SG_ External_temperature_2 m2 : 47|8@0+ (1,-50) [0|0] "ºC "  BMU_ID_0
 SG_ External_temperature_3 m2 : 55|8@0+ (1,-50) [0|0] "ºC "  BMU_ID_0
 SG_ External_temperature_4 m2 : 63|8@0+ (1,-50) [0|0] "ºC"  BMU_ID_0

BO_ 1448 wBMU_ID_8_msg_10_sensors: 8 BMU_ID_8
 SG_ Content_ID M : 7|8@0+ (1,0) [0|0] ""  BMU_ID_0
 SG_ IMD_resistance_value m0 : 15|16@0+ (1,0) [0|0] "kOhm"  BMU_ID_0
 SG_ IMD_status m0 : 31|8@0+ (1,0) [0|0] ""  BMU_ID_0
 SG_ Voltage_sensor_battery_voltage m1 : 15|16@0+ (0.1,-3200) [0|0] "V"  BMU_ID_0
 SG_ Voltage_sensor_link_voltage m1 : 31|16@0+ (0.1,-3200) [0|0] "V"  BMU_ID_0
 SG_ Voltage_sensor_fuse_voltage m1 : 47|16@0+ (0.1,-3200) [0|0] "V"  BMU_ID_0
 SG_ Voltage_sensor_status m1 : 59|4@0+ (1,0) [0|0] ""  BMU_ID_0
 SG_ Control_unit_temperature m2 : 15|8@0+ (1,-50) [0|0] "ºC "  BMU_ID_0
 SG_ Control_unit_supply_voltage m2 : 23|8@0+ (0.2,0) [0|0] "V"  BMU_ID_0
 SG_ Outputs_supply_voltage m2 : 31|8@0+ (0.2,0) [0|0] "V"  BMU_ID_0
 SG_ External_temperature_1 m2 : 39|8@0+ (1,-50) [0|0] "ºC "  BMU_ID_0
 SG_ External_temperature_2 m2 : 47|8@0+ (1,-50) [0|0] "ºC "  BMU_ID_0
 SG_ External_temperature_3 m2 : 55|8@0+ (1,-50) [0|0] "ºC "  BMU_ID_0
 SG_ External_temperature_4 m2 : 63|8@0+ (1,-50) [0|0] "ºC"  BMU_ID_0

BO_ 1449 wBMU_ID_9_msg_10_sensors: 8 BMU_ID_9
 SG_ Content_ID M : 7|8@0+ (1,0) [0|0] ""  BMU_ID_0
 SG_ IMD_resistance_value m0 : 15|16@0+ (1,0) [0|0] "kOhm"  BMU_ID_0
 SG_ IMD_status m0 : 31|8@0+ (1,0) [0|0] ""  BMU_ID_0
 SG_ Voltage_sensor_battery_voltage m1 : 15|16@0+ (0.1,-3200) [0|0] "V"  BMU_ID_0
 SG_ Voltage_sensor_link_voltage m1 : 31|16@0+ (0.1,-3200) [0|0] "V"  BMU_ID_0
 SG_ Voltage_sensor_fuse_voltage m1 : 47|16@0+ (0.1,-3200) [0|0] "V"  BMU_ID_0
 SG_ Voltage_sensor_status m1 : 59|4@0+ (1,0) [0|0] ""  BMU_ID_0
 SG_ Control_unit_temperature m2 : 15|8@0+ (1,-50) [0|0] "ºC "  BMU_ID_0
 SG_ Control_unit_supply_voltage m2 : 23|8@0+ (0.2,0) [0|0] "V"  BMU_ID_0
 SG_ Outputs_supply_voltage m2 : 31|8@0+ (0.2,0) [0|0] "V"  BMU_ID_0
 SG_ External_temperature_1 m2 : 39|8@0+ (1,-50) [0|0] "ºC "  BMU_ID_0
 SG_ External_temperature_2 m2 : 47|8@0+ (1,-50) [0|0] "ºC "  BMU_ID_0
 SG_ External_temperature_3 m2 : 55|8@0+ (1,-50) [0|0] "ºC "  BMU_ID_0
 SG_ External_temperature_4 m2 : 63|8@0+ (1,-50) [0|0] "ºC"  BMU_ID_0

BO_ 1450 wBMU_ID_10_msg_10_sensors: 8 BMU_ID_10
 SG_ Content_ID M : 7|8@0+ (1,0) [0|0] ""  BMU_ID_0
 SG_ IMD_resistance_value m0 : 15|16@0+ (1,0) [0|0] "kOhm"  BMU_ID_0
 SG_ IMD_status m0 : 31|8@0+ (1,0) [0|0] ""  BMU_ID_0
 SG_ Voltage_sensor_battery_voltage m1 : 15|16@0+ (0.1,-3200) [0|0] "V"  BMU_ID_0
 SG_ Voltage_sensor_link_voltage m1 : 31|16@0+ (0.1,-3200) [0|0] "V"  BMU_ID_0
 SG_ Voltage_sensor_fuse_voltage m1 : 47|16@0+ (0.1,-3200) [0|0] "V"  BMU_ID_0
 SG_ Voltage_sensor_status m1 : 59|4@0+ (1,0) [0|0] ""  BMU_ID_0
 SG_ Control_unit_temperature m2 : 15|8@0+ (1,-50) [0|0] "ºC "  BMU_ID_0
 SG_ Control_unit_supply_voltage m2 : 23|8@0+ (0.2,0) [0|0] "V"  BMU_ID_0
 SG_ Outputs_supply_voltage m2 : 31|8@0+ (0.2,0) [0|0] "V"  BMU_ID_0
 SG_ External_temperature_1 m2 : 39|8@0+ (1,-50) [0|0] "ºC "  BMU_ID_0
 SG_ External_temperature_2 m2 : 47|8@0+ (1,-50) [0|0] "ºC "  BMU_ID_0
 SG_ External_temperature_3 m2 : 55|8@0+ (1,-50) [0|0] "ºC "  BMU_ID_0
 SG_ External_temperature_4 m2 : 63|8@0+ (1,-50) [0|0] "ºC"  BMU_ID_0

BO_ 1451 wBMU_ID_11_msg_10_sensors: 8 BMU_ID_11
 SG_ Content_ID M : 7|8@0+ (1,0) [0|0] ""  BMU_ID_0
 SG_ IMD_resistance_value m0 : 15|16@0+ (1,0) [0|0] "kOhm"  BMU_ID_0
 SG_ IMD_status m0 : 31|8@0+ (1,0) [0|0] ""  BMU_ID_0
 SG_ Voltage_sensor_battery_voltage m1 : 15|16@0+ (0.1,-3200) [0|0] "V"  BMU_ID_0
 SG_ Voltage_sensor_link_voltage m1 : 31|16@0+ (0.1,-3200) [0|0] "V"  BMU_ID_0
 SG_ Voltage_sensor_fuse_voltage m1 : 47|16@0+ (0.1,-3200) [0|0] "V"  BMU_ID_0
 SG_ Voltage_sensor_status m1 : 59|4@0+ (1,0) [0|0] ""  BMU_ID_0
 SG_ Control_unit_temperature m2 : 15|8@0+ (1,-50) [0|0] "ºC "  BMU_ID_0
 SG_ Control_unit_supply_voltage m2 : 23|8@0+ (0.2,0) [0|0] "V"  BMU_ID_0
 SG_ Outputs_supply_voltage m2 : 31|8@0+ (0.2,0) [0|0] "V"  BMU_ID_0
 SG_ External_temperature_1 m2 : 39|8@0+ (1,-50) [0|0] "ºC "  BMU_ID_0
 SG_ External_temperature_2 m2 : 47|8@0+ (1,-50) [0|0] "ºC "  BMU_ID_0
 SG_ External_temperature_3 m2 : 55|8@0+ (1,-50) [0|0] "ºC "  BMU_ID_0
 SG_ External_temperature_4 m2 : 63|8@0+ (1,-50) [0|0] "ºC"  BMU_ID_0

BO_ 1452 wBMU_ID_12_msg_10_sensors: 8 BMU_ID_12
 SG_ Content_ID M : 7|8@0+ (1,0) [0|0] ""  BMU_ID_0
 SG_ IMD_resistance_value m0 : 15|16@0+ (1,0) [0|0] "kOhm"  BMU_ID_0
 SG_ IMD_status m0 : 31|8@0+ (1,0) [0|0] ""  BMU_ID_0
 SG_ Voltage_sensor_battery_voltage m1 : 15|16@0+ (0.1,-3200) [0|0] "V"  BMU_ID_0
 SG_ Voltage_sensor_link_voltage m1 : 31|16@0+ (0.1,-3200) [0|0] "V"  BMU_ID_0
 SG_ Voltage_sensor_fuse_voltage m1 : 47|16@0+ (0.1,-3200) [0|0] "V"  BMU_ID_0
 SG_ Voltage_sensor_status m1 : 59|4@0+ (1,0) [0|0] ""  BMU_ID_0
 SG_ Control_unit_temperature m2 : 15|8@0+ (1,-50) [0|0] "ºC "  BMU_ID_0
 SG_ Control_unit_supply_voltage m2 : 23|8@0+ (0.2,0) [0|0] "V"  BMU_ID_0
 SG_ Outputs_supply_voltage m2 : 31|8@0+ (0.2,0) [0|0] "V"  BMU_ID_0
 SG_ External_temperature_1 m2 : 39|8@0+ (1,-50) [0|0] "ºC "  BMU_ID_0
 SG_ External_temperature_2 m2 : 47|8@0+ (1,-50) [0|0] "ºC "  BMU_ID_0
 SG_ External_temperature_3 m2 : 55|8@0+ (1,-50) [0|0] "ºC "  BMU_ID_0
 SG_ External_temperature_4 m2 : 63|8@0+ (1,-50) [0|0] "ºC"  BMU_ID_0

BO_ 1453 wBMU_ID_13_msg_10_sensors: 8 BMU_ID_13
 SG_ Content_ID M : 7|8@0+ (1,0) [0|0] ""  BMU_ID_0
 SG_ IMD_resistance_value m0 : 15|16@0+ (1,0) [0|0] "kOhm"  BMU_ID_0
 SG_ IMD_status m0 : 31|8@0+ (1,0) [0|0] ""  BMU_ID_0
 SG_ Voltage_sensor_battery_voltage m1 : 15|16@0+ (0.1,-3200) [0|0] "V"  BMU_ID_0
 SG_ Voltage_sensor_link_voltage m1 : 31|16@0+ (0.1,-3200) [0|0] "V"  BMU_ID_0
 SG_ Voltage_sensor_fuse_voltage m1 : 47|16@0+ (0.1,-3200) [0|0] "V"  BMU_ID_0
 SG_ Voltage_sensor_status m1 : 59|4@0+ (1,0) [0|0] ""  BMU_ID_0
 SG_ Control_unit_temperature m2 : 15|8@0+ (1,-50) [0|0] "ºC "  BMU_ID_0
 SG_ Control_unit_supply_voltage m2 : 23|8@0+ (0.2,0) [0|0] "V"  BMU_ID_0
 SG_ Outputs_supply_voltage m2 : 31|8@0+ (0.2,0) [0|0] "V"  BMU_ID_0
 SG_ External_temperature_1 m2 : 39|8@0+ (1,-50) [0|0] "ºC "  BMU_ID_0
 SG_ External_temperature_2 m2 : 47|8@0+ (1,-50) [0|0] "ºC "  BMU_ID_0
 SG_ External_temperature_3 m2 : 55|8@0+ (1,-50) [0|0] "ºC "  BMU_ID_0
 SG_ External_temperature_4 m2 : 63|8@0+ (1,-50) [0|0] "ºC"  BMU_ID_0

BO_ 1454 wBMU_ID_14_msg_10_sensors: 8 BMU_ID_14
 SG_ Content_ID M : 7|8@0+ (1,0) [0|0] ""  BMU_ID_0
 SG_ IMD_resistance_value m0 : 15|16@0+ (1,0) [0|0] "kOhm"  BMU_ID_0
 SG_ IMD_status m0 : 31|8@0+ (1,0) [0|0] ""  BMU_ID_0
 SG_ Voltage_sensor_battery_voltage m1 : 15|16@0+ (0.1,-3200) [0|0] "V"  BMU_ID_0
 SG_ Voltage_sensor_link_voltage m1 : 31|16@0+ (0.1,-3200) [0|0] "V"  BMU_ID_0
 SG_ Voltage_sensor_fuse_voltage m1 : 47|16@0+ (0.1,-3200) [0|0] "V"  BMU_ID_0
 SG_ Voltage_sensor_status m1 : 59|4@0+ (1,0) [0|0] ""  BMU_ID_0
 SG_ Control_unit_temperature m2 : 15|8@0+ (1,-50) [0|0] "ºC "  BMU_ID_0
 SG_ Control_unit_supply_voltage m2 : 23|8@0+ (0.2,0) [0|0] "V"  BMU_ID_0
 SG_ Outputs_supply_voltage m2 : 31|8@0+ (0.2,0) [0|0] "V"  BMU_ID_0
 SG_ External_temperature_1 m2 : 39|8@0+ (1,-50) [0|0] "ºC "  BMU_ID_0
 SG_ External_temperature_2 m2 : 47|8@0+ (1,-50) [0|0] "ºC "  BMU_ID_0
 SG_ External_temperature_3 m2 : 55|8@0+ (1,-50) [0|0] "ºC "  BMU_ID_0
 SG_ External_temperature_4 m2 : 63|8@0+ (1,-50) [0|0] "ºC"  BMU_ID_0

BO_ 1455 wBMU_ID_15_msg_10_sensors: 8 BMU_ID_15
 SG_ Content_ID M : 7|8@0+ (1,0) [0|0] ""  BMU_ID_0
 SG_ IMD_resistance_value m0 : 15|16@0+ (1,0) [0|0] "kOhm"  BMU_ID_0
 SG_ IMD_status m0 : 31|8@0+ (1,0) [0|0] ""  BMU_ID_0
 SG_ Voltage_sensor_battery_voltage m1 : 15|16@0+ (0.1,-3200) [0|0] "V"  BMU_ID_0
 SG_ Voltage_sensor_link_voltage m1 : 31|16@0+ (0.1,-3200) [0|0] "V"  BMU_ID_0
 SG_ Voltage_sensor_fuse_voltage m1 : 47|16@0+ (0.1,-3200) [0|0] "V"  BMU_ID_0
 SG_ Voltage_sensor_status m1 : 59|4@0+ (1,0) [0|0] ""  BMU_ID_0
 SG_ Control_unit_temperature m2 : 15|8@0+ (1,-50) [0|0] "ºC "  BMU_ID_0
 SG_ Control_unit_supply_voltage m2 : 23|8@0+ (0.2,0) [0|0] "V"  BMU_ID_0
 SG_ Outputs_supply_voltage m2 : 31|8@0+ (0.2,0) [0|0] "V"  BMU_ID_0
 SG_ External_temperature_1 m2 : 39|8@0+ (1,-50) [0|0] "ºC "  BMU_ID_0
 SG_ External_temperature_2 m2 : 47|8@0+ (1,-50) [0|0] "ºC "  BMU_ID_0
 SG_ External_temperature_3 m2 : 55|8@0+ (1,-50) [0|0] "ºC "  BMU_ID_0
 SG_ External_temperature_4 m2 : 63|8@0+ (1,-50) [0|0] "ºC"  BMU_ID_0

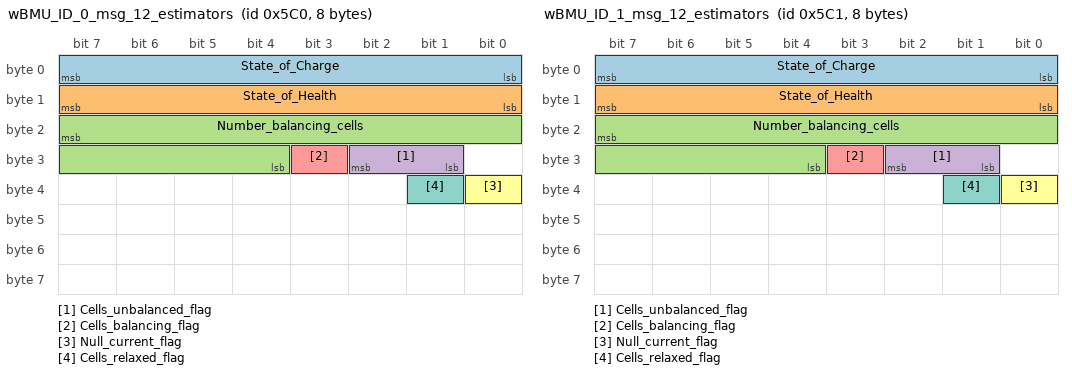
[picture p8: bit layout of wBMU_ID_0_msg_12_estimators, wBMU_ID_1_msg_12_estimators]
BO_ 1472 wBMU_ID_0_msg_12_estimators: 8 BMU_ID_0
 SG_ State_of_Charge : 7|8@0+ (1,0) [0|0] "%"  BMU_ID_0
 SG_ State_of_Health : 15|8@0+ (1,0) [0|0] "%"  BMU_ID_0
 SG_ Number_balancing_cells : 23|12@0+ (1,0) [0|0] "-"  BMU_ID_0
 SG_ Cells_unbalanced_flag : 26|2@0+ (1,0) [0|0] "-"  BMU_ID_0
 SG_ Cells_balancing_flag : 27|1@0+ (1,0) [0|0] "-"  BMU_ID_0
 SG_ Null_current_flag : 32|1@0+ (1,0) [0|0] "" Vector__XXX
 SG_ Cells_relaxed_flag : 33|1@0+ (1,0) [0|0] "" Vector__XXX

BO_ 1473 wBMU_ID_1_msg_12_estimators: 8 BMU_ID_1
 SG_ State_of_Charge : 7|8@0+ (1,0) [0|0] "%"  BMU_ID_0
 SG_ State_of_Health : 15|8@0+ (1,0) [0|0] "%"  BMU_ID_0
 SG_ Number_balancing_cells : 23|12@0+ (1,0) [0|0] "-"  BMU_ID_0
 SG_ Cells_unbalanced_flag : 26|2@0+ (1,0) [0|0] "-"  BMU_ID_0
 SG_ Cells_balancing_flag : 27|1@0+ (1,0) [0|0] "-"  BMU_ID_0
 SG_ Null_current_flag : 32|1@0+ (1,0) [0|0] "" Vector__XXX
 SG_ Cells_relaxed_flag : 33|1@0+ (1,0) [0|0] "" Vector__XXX

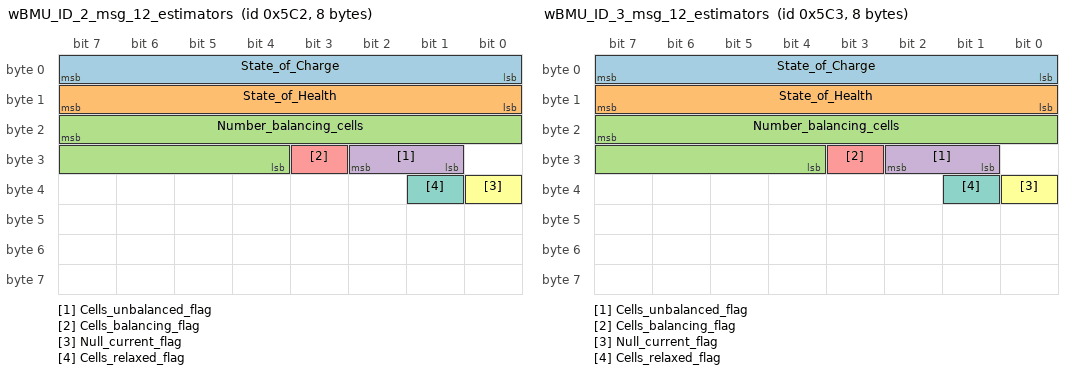
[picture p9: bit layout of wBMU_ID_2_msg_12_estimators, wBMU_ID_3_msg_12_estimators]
BO_ 1474 wBMU_ID_2_msg_12_estimators: 8 BMU_ID_2
 SG_ State_of_Charge : 7|8@0+ (1,0) [0|0] "%"  BMU_ID_0
 SG_ State_of_Health : 15|8@0+ (1,0) [0|0] "%"  BMU_ID_0
 SG_ Number_balancing_cells : 23|12@0+ (1,0) [0|0] "-"  BMU_ID_0
 SG_ Cells_unbalanced_flag : 26|2@0+ (1,0) [0|0] "-"  BMU_ID_0
 SG_ Cells_balancing_flag : 27|1@0+ (1,0) [0|0] "-"  BMU_ID_0
 SG_ Null_current_flag : 32|1@0+ (1,0) [0|0] "" Vector__XXX
 SG_ Cells_relaxed_flag : 33|1@0+ (1,0) [0|0] "" Vector__XXX

BO_ 1475 wBMU_ID_3_msg_12_estimators: 8 BMU_ID_3
 SG_ State_of_Charge : 7|8@0+ (1,0) [0|0] "%"  BMU_ID_0
 SG_ State_of_Health : 15|8@0+ (1,0) [0|0] "%"  BMU_ID_0
 SG_ Number_balancing_cells : 23|12@0+ (1,0) [0|0] "-"  BMU_ID_0
 SG_ Cells_unbalanced_flag : 26|2@0+ (1,0) [0|0] "-"  BMU_ID_0
 SG_ Cells_balancing_flag : 27|1@0+ (1,0) [0|0] "-"  BMU_ID_0
 SG_ Null_current_flag : 32|1@0+ (1,0) [0|0] "" Vector__XXX
 SG_ Cells_relaxed_flag : 33|1@0+ (1,0) [0|0] "" Vector__XXX

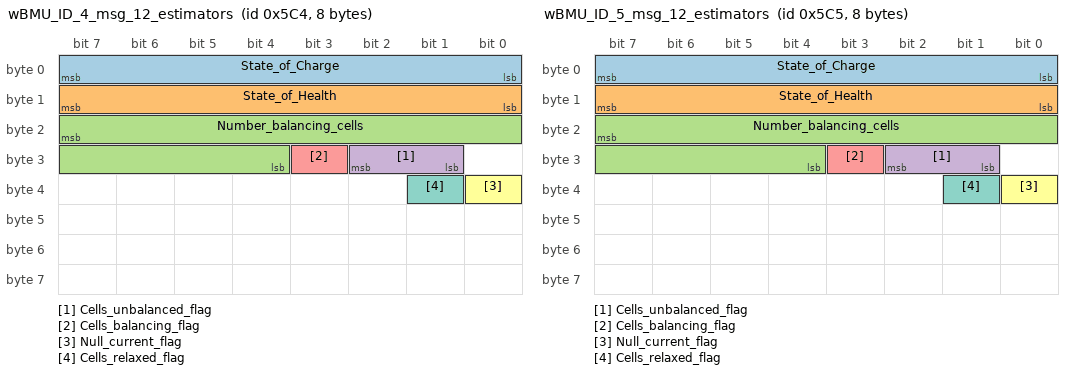
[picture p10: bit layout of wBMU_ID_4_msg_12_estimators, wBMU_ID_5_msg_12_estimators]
BO_ 1476 wBMU_ID_4_msg_12_estimators: 8 BMU_ID_4
 SG_ State_of_Charge : 7|8@0+ (1,0) [0|0] "%"  BMU_ID_0
 SG_ State_of_Health : 15|8@0+ (1,0) [0|0] "%"  BMU_ID_0
 SG_ Number_balancing_cells : 23|12@0+ (1,0) [0|0] "-"  BMU_ID_0
 SG_ Cells_unbalanced_flag : 26|2@0+ (1,0) [0|0] "-"  BMU_ID_0
 SG_ Cells_balancing_flag : 27|1@0+ (1,0) [0|0] "-"  BMU_ID_0
 SG_ Null_current_flag : 32|1@0+ (1,0) [0|0] "" Vector__XXX
 SG_ Cells_relaxed_flag : 33|1@0+ (1,0) [0|0] "" Vector__XXX

BO_ 1477 wBMU_ID_5_msg_12_estimators: 8 BMU_ID_5
 SG_ State_of_Charge : 7|8@0+ (1,0) [0|0] "%"  BMU_ID_0
 SG_ State_of_Health : 15|8@0+ (1,0) [0|0] "%"  BMU_ID_0
 SG_ Number_balancing_cells : 23|12@0+ (1,0) [0|0] "-"  BMU_ID_0
 SG_ Cells_unbalanced_flag : 26|2@0+ (1,0) [0|0] "-"  BMU_ID_0
 SG_ Cells_balancing_flag : 27|1@0+ (1,0) [0|0] "-"  BMU_ID_0
 SG_ Null_current_flag : 32|1@0+ (1,0) [0|0] "" Vector__XXX
 SG_ Cells_relaxed_flag : 33|1@0+ (1,0) [0|0] "" Vector__XXX

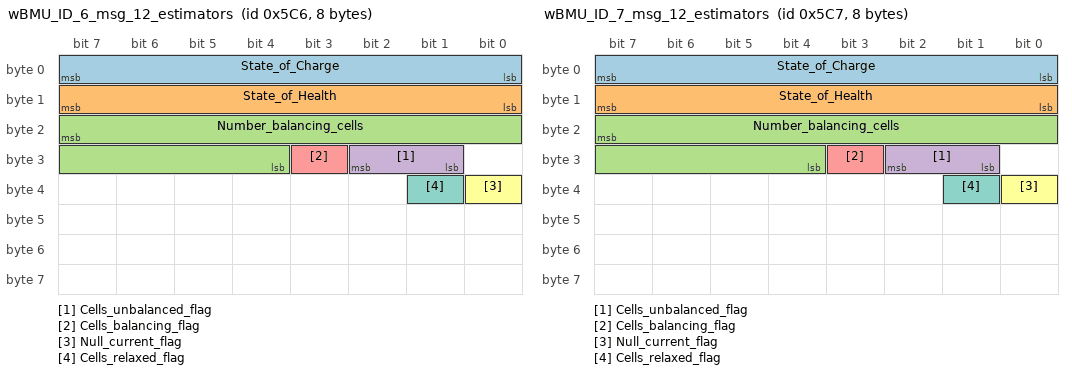
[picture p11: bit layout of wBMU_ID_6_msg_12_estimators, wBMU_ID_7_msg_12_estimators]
BO_ 1478 wBMU_ID_6_msg_12_estimators: 8 BMU_ID_6
 SG_ State_of_Charge : 7|8@0+ (1,0) [0|0] "%"  BMU_ID_0
 SG_ State_of_Health : 15|8@0+ (1,0) [0|0] "%"  BMU_ID_0
 SG_ Number_balancing_cells : 23|12@0+ (1,0) [0|0] "-"  BMU_ID_0
 SG_ Cells_unbalanced_flag : 26|2@0+ (1,0) [0|0] "-"  BMU_ID_0
 SG_ Cells_balancing_flag : 27|1@0+ (1,0) [0|0] "-"  BMU_ID_0
 SG_ Null_current_flag : 32|1@0+ (1,0) [0|0] "" Vector__XXX
 SG_ Cells_relaxed_flag : 33|1@0+ (1,0) [0|0] "" Vector__XXX

BO_ 1479 wBMU_ID_7_msg_12_estimators: 8 BMU_ID_7
 SG_ State_of_Charge : 7|8@0+ (1,0) [0|0] "%"  BMU_ID_0
 SG_ State_of_Health : 15|8@0+ (1,0) [0|0] "%"  BMU_ID_0
 SG_ Number_balancing_cells : 23|12@0+ (1,0) [0|0] "-"  BMU_ID_0
 SG_ Cells_unbalanced_flag : 26|2@0+ (1,0) [0|0] "-"  BMU_ID_0
 SG_ Cells_balancing_flag : 27|1@0+ (1,0) [0|0] "-"  BMU_ID_0
 SG_ Null_current_flag : 32|1@0+ (1,0) [0|0] "" Vector__XXX
 SG_ Cells_relaxed_flag : 33|1@0+ (1,0) [0|0] "" Vector__XXX

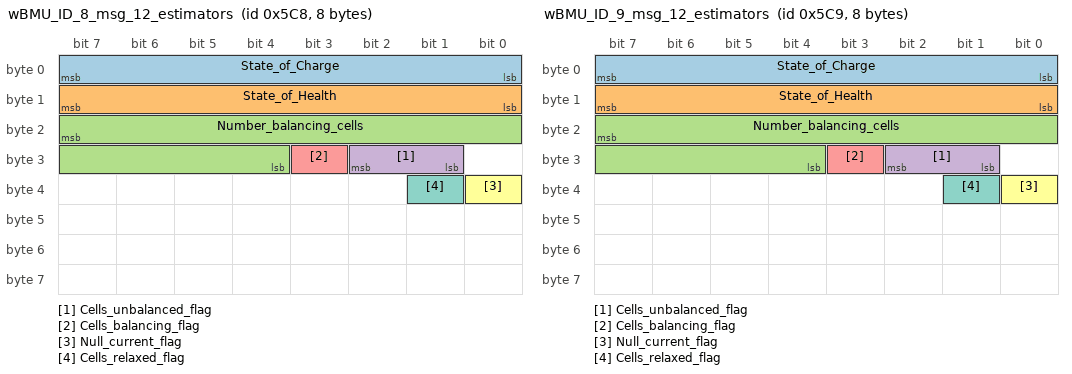
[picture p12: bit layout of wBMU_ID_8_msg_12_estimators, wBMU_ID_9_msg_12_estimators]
BO_ 1480 wBMU_ID_8_msg_12_estimators: 8 BMU_ID_8
 SG_ State_of_Charge : 7|8@0+ (1,0) [0|0] "%"  BMU_ID_0
 SG_ State_of_Health : 15|8@0+ (1,0) [0|0] "%"  BMU_ID_0
 SG_ Number_balancing_cells : 23|12@0+ (1,0) [0|0] "-"  BMU_ID_0
 SG_ Cells_unbalanced_flag : 26|2@0+ (1,0) [0|0] "-"  BMU_ID_0
 SG_ Cells_balancing_flag : 27|1@0+ (1,0) [0|0] "-"  BMU_ID_0
 SG_ Null_current_flag : 32|1@0+ (1,0) [0|0] "" Vector__XXX
 SG_ Cells_relaxed_flag : 33|1@0+ (1,0) [0|0] "" Vector__XXX

BO_ 1481 wBMU_ID_9_msg_12_estimators: 8 BMU_ID_9
 SG_ State_of_Charge : 7|8@0+ (1,0) [0|0] "%"  BMU_ID_0
 SG_ State_of_Health : 15|8@0+ (1,0) [0|0] "%"  BMU_ID_0
 SG_ Number_balancing_cells : 23|12@0+ (1,0) [0|0] "-"  BMU_ID_0
 SG_ Cells_unbalanced_flag : 26|2@0+ (1,0) [0|0] "-"  BMU_ID_0
 SG_ Cells_balancing_flag : 27|1@0+ (1,0) [0|0] "-"  BMU_ID_0
 SG_ Null_current_flag : 32|1@0+ (1,0) [0|0] "" Vector__XXX
 SG_ Cells_relaxed_flag : 33|1@0+ (1,0) [0|0] "" Vector__XXX

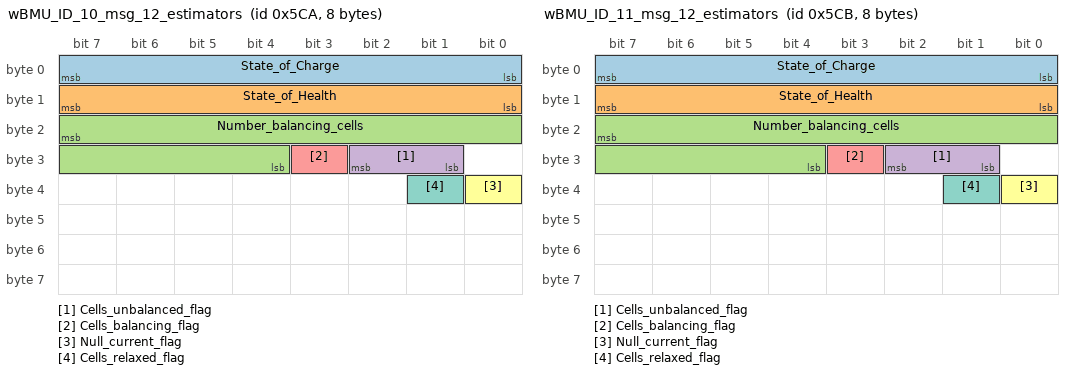
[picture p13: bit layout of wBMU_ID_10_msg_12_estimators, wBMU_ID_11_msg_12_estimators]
BO_ 1482 wBMU_ID_10_msg_12_estimators: 8 BMU_ID_10
 SG_ State_of_Charge : 7|8@0+ (1,0) [0|0] "%"  BMU_ID_0
 SG_ State_of_Health : 15|8@0+ (1,0) [0|0] "%"  BMU_ID_0
 SG_ Number_balancing_cells : 23|12@0+ (1,0) [0|0] "-"  BMU_ID_0
 SG_ Cells_unbalanced_flag : 26|2@0+ (1,0) [0|0] "-"  BMU_ID_0
 SG_ Cells_balancing_flag : 27|1@0+ (1,0) [0|0] "-"  BMU_ID_0
 SG_ Null_current_flag : 32|1@0+ (1,0) [0|0] "" Vector__XXX
 SG_ Cells_relaxed_flag : 33|1@0+ (1,0) [0|0] "" Vector__XXX

BO_ 1483 wBMU_ID_11_msg_12_estimators: 8 BMU_ID_11
 SG_ State_of_Charge : 7|8@0+ (1,0) [0|0] "%"  BMU_ID_0
 SG_ State_of_Health : 15|8@0+ (1,0) [0|0] "%"  BMU_ID_0
 SG_ Number_balancing_cells : 23|12@0+ (1,0) [0|0] "-"  BMU_ID_0
 SG_ Cells_unbalanced_flag : 26|2@0+ (1,0) [0|0] "-"  BMU_ID_0
 SG_ Cells_balancing_flag : 27|1@0+ (1,0) [0|0] "-"  BMU_ID_0
 SG_ Null_current_flag : 32|1@0+ (1,0) [0|0] "" Vector__XXX
 SG_ Cells_relaxed_flag : 33|1@0+ (1,0) [0|0] "" Vector__XXX

CM_ SG_ 1365 System_errors "Associated DTC: 156, 157, 158, 159, 160, 162, 163, 197, 228, 266, 267";
CM_ SG_ 1365 Architecture_configuration_error "Associated DTC: 187, 189, 190, 191, 192, 193, 194, 195";
CM_ SG_ 1365 Parallelization_voltage_errors "Associated DTC: 280";
CM_ SG_ 1365 General_configuration_errors "Associated DTC: 67, 69, 70, 72, 244, 245, 268";
CM_ SG_ 1365 Parallelization_comm_lost_primar "Associated DTC: 243";
CM_ SG_ 1365 Cell_overvoltage "Associated DTC: 10";
CM_ SG_ 1365 Cell_undervoltage "Associated DTC: 11, 52";
CM_ SG_ 1365 Comm_failure_with_CMU "Associated DTC: 17";
CM_ SG_ 1365 Internal_CMU_error "Associated DTC: 20, 23, 24, 30, 256, 278";
CM_ SG_ 1365 Internal_CMU_temperature_error "Associated DTC: 25";
CM_ SG_ 1365 Internal_CMU_voltage_reference "Associated DTC: 26";
CM_ SG_ 1365 Cell_shortcircuit "Associated DTC: 27";
CM_ SG_ 1365 Battery_overcurrent "Associated DTC: 28";
CM_ SG_ 1365 Overload_ratio_exceeded "Associated DTC: 164";
CM_ SG_ 1365 Current_sensor_errors "Associated DTC: 22, 34, 79, 167, 229, 239, 277";
CM_ SG_ 1365 BMU_temperature_errors "Associated DTC: 169, 264";
CM_ SG_ 1365 Cell_overtemperature "Associated DTC: 12";
CM_ SG_ 1365 Cell_undertemperature "Associated DTC: 13";
CM_ SG_ 1365 Balancing_overtemperature "Associated DTC: 14";
CM_ SG_ 1365 Balancing_undertemperature "Associated DTC: 15";
CM_ SG_ 1365 Max_op_cell_temp_delta "Associated DTC: 32";
CM_ SG_ 1365 Thermal_runaway "Associated DTC: 16";
CM_ SG_ 1365 OW_and_SC_detected_on_cell "Associated DTC: 31";
CM_ SG_ 1365 BMU_external_overtemperature "Associated DTC: 261, 262, 263";
CM_ SG_ 1365 Battery_undervoltage "Associated DTC: 29";
CM_ SG_ 1365 BMU_supply_voltage_error "Associated DTC: 168";
CM_ SG_ 1365 Battery_overvoltage "Associated DTC: 18";
CM_ SG_ 1365 Cells_unbalanced "Associated DTC: 33, 265";
CM_ SG_ 1365 Advanced_relaxation_voltage_delt "Associated DTC: 19";
CM_ SG_ 1365 Internal_BMU_error "Associated DTC: 63, 77, 170, 176, 183, 184, 249, 260";
CM_ SG_ 1365 Safety_sensor_error "Associated DTC: 246";
CM_ SG_ 1365 High_voltage_sensor_errors "Associated DTC: 61, 240, 273, 274, 275";
CM_ SG_ 1365 IMD_errors "Associated DTC: 276, 279";
CM_ SG_ 1365 Isolation_error "Associated DTC: 174";
CM_ SG_ 1365 BMU_SoC_errors "Associted DTC: 35, 36, 55";
CM_ SG_ 1365 BMU_SoH_error "Associated DTC: 37";
CM_ SG_ 1365 Contactor_stuck_open_errors "Associated DTC: 73, 269, 270";
CM_ SG_ 1365 Contactor_stuck_closed_errors "Associated DTC: 252, 253, 254, 271, 272";
CM_ SG_ 1365 Contactor_supply_error "Associated DTC: 76";
CM_ SG_ 1365 Contactor_precharge_error "Associated DTC: 75";
CM_ SG_ 1365 Emergency_button_error "Associated DTC: 175";
CM_ SG_ 1365 Actuation_errors "Associated DTC: 91, 186";
CM_ SG_ 1365 Auto_OFF "Associated DTC: 185";
CM_ SG_ 1365 Mode_mismatch "Associated DTC: 250";
CM_ SG_ 1365 Open_wire_errors "Associated DTC: 21, 257";
CM_ SG_ 1365 Output_driver_errors_diagnostics "Associated DTC: 74, 78";
CM_ SG_ 1365 User_forced_errors "Associated DTC: 89, 94";
CM_ SG_ 1365 SD_error "Associated DTC: 177";
CM_ SG_ 1365 Ethernet_module_error "Associated DTC: 6";
CM_ SG_ 1365 Internal_memory_errors "Associated DTC: 83, 84, 85, 212";
CM_ SG_ 1366 System_errors "Associated DTC: 156, 157, 158, 159, 160, 162, 163, 197, 228, 266, 267";
CM_ SG_ 1366 Architecture_configuration_error "Associated DTC: 187, 189, 190, 191, 192, 193, 194, 195";
CM_ SG_ 1366 Parallelization_voltage_errors "Associated DTC: 280";
CM_ SG_ 1366 General_configuration_errors "Associated DTC: 67, 69, 70, 72, 244, 245, 268";
CM_ SG_ 1366 Parallelization_comm_lost_primar "Associated DTC: 243";
CM_ SG_ 1366 Cell_overvoltage "Associated DTC: 10";
CM_ SG_ 1366 Cell_undervoltage "Associated DTC: 11, 52";
CM_ SG_ 1366 Comm_failure_with_CMU "Associated DTC: 17";
CM_ SG_ 1366 Internal_CMU_error "Associated DTC: 20, 23, 24, 30, 256, 278";
CM_ SG_ 1366 Internal_CMU_temperature_error "Associated DTC: 25";
CM_ SG_ 1366 Internal_CMU_voltage_reference "Associated DTC: 26";
CM_ SG_ 1366 Cell_shortcircuit "Associated DTC: 27";
CM_ SG_ 1366 Battery_overcurrent "Associated DTC: 28";
CM_ SG_ 1366 Overload_ratio_exceeded "Associated DTC: 164";
CM_ SG_ 1366 Current_sensor_errors "Associated DTC: 22, 34, 79, 167, 229, 239, 277";
CM_ SG_ 1366 BMU_temperature_errors "Associated DTC: 169, 264";
CM_ SG_ 1366 Cell_overtemperature "Associated DTC: 12";
CM_ SG_ 1366 Cell_undertemperature "Associated DTC: 13";
CM_ SG_ 1366 Balancing_overtemperature "Associated DTC: 14";
CM_ SG_ 1366 Balancing_undertemperature "Associated DTC: 15";
CM_ SG_ 1366 Max_op_cell_temp_delta "Associated DTC: 32";
CM_ SG_ 1366 Thermal_runaway "Associated DTC: 16";
CM_ SG_ 1366 OW_and_SC_detected_on_cell "Associated DTC: 31";
CM_ SG_ 1366 BMU_external_overtemperature "Associated DTC: 261, 262, 263";
CM_ SG_ 1366 Battery_undervoltage "Associated DTC: 29";
CM_ SG_ 1366 BMU_supply_voltage_error "Associated DTC: 168";
CM_ SG_ 1366 Battery_overvoltage "Associated DTC: 18";
CM_ SG_ 1366 Cells_unbalanced "Associated DTC: 33, 265";
CM_ SG_ 1366 Advanced_relaxation_voltage_delt "Associated DTC: 19";
CM_ SG_ 1366 Internal_BMU_error "Associated DTC: 63, 77, 170, 176, 183, 184, 249, 260";
CM_ SG_ 1366 Safety_sensor_error "Associated DTC: 246";
CM_ SG_ 1366 High_voltage_sensor_errors "Associated DTC: 61, 240, 273, 274, 275";
CM_ SG_ 1366 IMD_errors "Associated DTC: 276, 279";
CM_ SG_ 1366 Isolation_error "Associated DTC: 174";
CM_ SG_ 1366 BMU_SoC_errors "Associted DTC: 35, 36, 55";
CM_ SG_ 1366 BMU_SoH_error "Associated DTC: 37";
CM_ SG_ 1366 Contactor_stuck_open_errors "Associated DTC: 73, 269, 270";
CM_ SG_ 1366 Contactor_stuck_closed_errors "Associated DTC: 252, 253, 254, 271, 272";
CM_ SG_ 1366 Contactor_supply_error "Associated DTC: 76";
CM_ SG_ 1366 Contactor_precharge_error "Associated DTC: 75";
CM_ SG_ 1366 Emergency_button_error "Associated DTC: 175";
CM_ SG_ 1366 Actuation_errors "Associated DTC: 91, 186";
CM_ SG_ 1366 Auto_OFF "Associated DTC: 185";
CM_ SG_ 1366 Mode_mismatch "Associated DTC: 250";
CM_ SG_ 1366 Open_wire_errors "Associated DTC: 21, 257";
CM_ SG_ 1366 Output_driver_errors_diagnostics "Associated DTC: 74, 78";
CM_ SG_ 1366 User_forced_errors "Associated DTC: 89, 94";
CM_ SG_ 1366 SD_error "Associated DTC: 177";
CM_ SG_ 1366 Ethernet_module_error "Associated DTC: 6";
CM_ SG_ 1366 Internal_memory_errors "Associated DTC: 83, 84, 85, 212";
CM_ SG_ 1367 System_errors "Associated DTC: 156, 157, 158, 159, 160, 162, 163, 197, 228, 266, 267";
CM_ SG_ 1367 Architecture_configuration_error "Associated DTC: 187, 189, 190, 191, 192, 193, 194, 195";
CM_ SG_ 1367 Parallelization_voltage_errors "Associated DTC: 280";
CM_ SG_ 1367 General_configuration_errors "Associated DTC: 67, 69, 70, 72, 244, 245, 268";
CM_ SG_ 1367 Parallelization_comm_lost_primar "Associated DTC: 243";
CM_ SG_ 1367 Cell_overvoltage "Associated DTC: 10";
CM_ SG_ 1367 Cell_undervoltage "Associated DTC: 11, 52";
CM_ SG_ 1367 Comm_failure_with_CMU "Associated DTC: 17";
CM_ SG_ 1367 Internal_CMU_error "Associated DTC: 20, 23, 24, 30, 256, 278";
CM_ SG_ 1367 Internal_CMU_temperature_error "Associated DTC: 25";
CM_ SG_ 1367 Internal_CMU_voltage_reference "Associated DTC: 26";
CM_ SG_ 1367 Cell_shortcircuit "Associated DTC: 27";
CM_ SG_ 1367 Battery_overcurrent "Associated DTC: 28";
CM_ SG_ 1367 Overload_ratio_exceeded "Associated DTC: 164";
CM_ SG_ 1367 Current_sensor_errors "Associated DTC: 22, 34, 79, 167, 229, 239, 277";
CM_ SG_ 1367 BMU_temperature_errors "Associated DTC: 169, 264";
CM_ SG_ 1367 Cell_overtemperature "Associated DTC: 12";
CM_ SG_ 1367 Cell_undertemperature "Associated DTC: 13";
CM_ SG_ 1367 Balancing_overtemperature "Associated DTC: 14";
CM_ SG_ 1367 Balancing_undertemperature "Associated DTC: 15";
CM_ SG_ 1367 Max_op_cell_temp_delta "Associated DTC: 32";
CM_ SG_ 1367 Thermal_runaway "Associated DTC: 16";
CM_ SG_ 1367 OW_and_SC_detected_on_cell "Associated DTC: 31";
CM_ SG_ 1367 BMU_external_overtemperature "Associated DTC: 261, 262, 263";
CM_ SG_ 1367 Battery_undervoltage "Associated DTC: 29";
CM_ SG_ 1367 BMU_supply_voltage_error "Associated DTC: 168";
CM_ SG_ 1367 Battery_overvoltage "Associated DTC: 18";
CM_ SG_ 1367 Cells_unbalanced "Associated DTC: 33, 265";
CM_ SG_ 1367 Advanced_relaxation_voltage_delt "Associated DTC: 19";
CM_ SG_ 1367 Internal_BMU_error "Associated DTC: 63, 77, 170, 176, 183, 184, 249, 260";
CM_ SG_ 1367 Safety_sensor_error "Associated DTC: 246";
CM_ SG_ 1367 High_voltage_sensor_errors "Associated DTC: 61, 240, 273, 274, 275";
CM_ SG_ 1367 IMD_errors "Associated DTC: 276, 279";
CM_ SG_ 1367 Isolation_error "Associated DTC: 174";
CM_ SG_ 1367 BMU_SoC_errors "Associted DTC: 35, 36, 55";
CM_ SG_ 1367 BMU_SoH_error "Associated DTC: 37";
CM_ SG_ 1367 Contactor_stuck_open_errors "Associated DTC: 73, 269, 270";
CM_ SG_ 1367 Contactor_stuck_closed_errors "Associated DTC: 252, 253, 254, 271, 272";
CM_ SG_ 1367 Contactor_supply_error "Associated DTC: 76";
CM_ SG_ 1367 Contactor_precharge_error "Associated DTC: 75";
CM_ SG_ 1367 Emergency_button_error "Associated DTC: 175";
CM_ SG_ 1367 Actuation_errors "Associated DTC: 91, 186";
CM_ SG_ 1367 Auto_OFF "Associated DTC: 185";
CM_ SG_ 1367 Mode_mismatch "Associated DTC: 250";
CM_ SG_ 1367 Open_wire_errors "Associated DTC: 21, 257";
CM_ SG_ 1367 Output_driver_errors_diagnostics "Associated DTC: 74, 78";
CM_ SG_ 1367 User_forced_errors "Associated DTC: 89, 94";
CM_ SG_ 1367 SD_error "Associated DTC: 177";
CM_ SG_ 1367 Ethernet_module_error "Associated DTC: 6";
CM_ SG_ 1367 Internal_memory_errors "Associated DTC: 83, 84, 85, 212";
CM_ SG_ 1368 System_errors "Associated DTC: 156, 157, 158, 159, 160, 162, 163, 197, 228, 266, 267";
CM_ SG_ 1368 Architecture_configuration_error "Associated DTC: 187, 189, 190, 191, 192, 193, 194, 195";
CM_ SG_ 1368 Parallelization_voltage_errors "Associated DTC: 280";
CM_ SG_ 1368 General_configuration_errors "Associated DTC: 67, 69, 70, 72, 244, 245, 268";
CM_ SG_ 1368 Parallelization_comm_lost_primar "Associated DTC: 243";
CM_ SG_ 1368 Cell_overvoltage "Associated DTC: 10";
CM_ SG_ 1368 Cell_undervoltage "Associated DTC: 11, 52";
CM_ SG_ 1368 Comm_failure_with_CMU "Associated DTC: 17";
CM_ SG_ 1368 Internal_CMU_error "Associated DTC: 20, 23, 24, 30, 256, 278";
CM_ SG_ 1368 Internal_CMU_temperature_error "Associated DTC: 25";
CM_ SG_ 1368 Internal_CMU_voltage_reference "Associated DTC: 26";
CM_ SG_ 1368 Cell_shortcircuit "Associated DTC: 27";
CM_ SG_ 1368 Battery_overcurrent "Associated DTC: 28";
CM_ SG_ 1368 Overload_ratio_exceeded "Associated DTC: 164";
CM_ SG_ 1368 Current_sensor_errors "Associated DTC: 22, 34, 79, 167, 229, 239, 277";
CM_ SG_ 1368 BMU_temperature_errors "Associated DTC: 169, 264";
CM_ SG_ 1368 Cell_overtemperature "Associated DTC: 12";
CM_ SG_ 1368 Cell_undertemperature "Associated DTC: 13";
CM_ SG_ 1368 Balancing_overtemperature "Associated DTC: 14";
CM_ SG_ 1368 Balancing_undertemperature "Associated DTC: 15";
CM_ SG_ 1368 Max_op_cell_temp_delta "Associated DTC: 32";
CM_ SG_ 1368 Thermal_runaway "Associated DTC: 16";
CM_ SG_ 1368 OW_and_SC_detected_on_cell "Associated DTC: 31";
CM_ SG_ 1368 BMU_external_overtemperature "Associated DTC: 261, 262, 263";
CM_ SG_ 1368 Battery_undervoltage "Associated DTC: 29";
CM_ SG_ 1368 BMU_supply_voltage_error "Associated DTC: 168";
CM_ SG_ 1368 Battery_overvoltage "Associated DTC: 18";
CM_ SG_ 1368 Cells_unbalanced "Associated DTC: 33, 265";
CM_ SG_ 1368 Advanced_relaxation_voltage_delt "Associated DTC: 19";
CM_ SG_ 1368 Internal_BMU_error "Associated DTC: 63, 77, 170, 176, 183, 184, 249, 260";
CM_ SG_ 1368 Safety_sensor_error "Associated DTC: 246";
CM_ SG_ 1368 High_voltage_sensor_errors "Associated DTC: 61, 240, 273, 274, 275";
CM_ SG_ 1368 IMD_errors "Associated DTC: 276, 279";
CM_ SG_ 1368 Isolation_error "Associated DTC: 174";
CM_ SG_ 1368 BMU_SoC_errors "Associted DTC: 35, 36, 55";
CM_ SG_ 1368 BMU_SoH_error "Associated DTC: 37";
CM_ SG_ 1368 Contactor_stuck_open_errors "Associated DTC: 73, 269, 270";
CM_ SG_ 1368 Contactor_stuck_closed_errors "Associated DTC: 252, 253, 254, 271, 272";
CM_ SG_ 1368 Contactor_supply_error "Associated DTC: 76";
CM_ SG_ 1368 Contactor_precharge_error "Associated DTC: 75";
CM_ SG_ 1368 Emergency_button_error "Associated DTC: 175";
CM_ SG_ 1368 Actuation_errors "Associated DTC: 91, 186";
CM_ SG_ 1368 Auto_OFF "Associated DTC: 185";
CM_ SG_ 1368 Mode_mismatch "Associated DTC: 250";
CM_ SG_ 1368 Open_wire_errors "Associated DTC: 21, 257";
CM_ SG_ 1368 Output_driver_errors_diagnostics "Associated DTC: 74, 78";
CM_ SG_ 1368 User_forced_errors "Associated DTC: 89, 94";
CM_ SG_ 1368 SD_error "Associated DTC: 177";
CM_ SG_ 1368 Ethernet_module_error "Associated DTC: 6";
CM_ SG_ 1368 Internal_memory_errors "Associated DTC: 83, 84, 85, 212";
CM_ SG_ 1369 System_errors "Associated DTC: 156, 157, 158, 159, 160, 162, 163, 197, 228, 266, 267";
CM_ SG_ 1369 Architecture_configuration_error "Associated DTC: 187, 189, 190, 191, 192, 193, 194, 195";
CM_ SG_ 1369 Parallelization_voltage_errors "Associated DTC: 280";
CM_ SG_ 1369 General_configuration_errors "Associated DTC: 67, 69, 70, 72, 244, 245, 268";
CM_ SG_ 1369 Parallelization_comm_lost_primar "Associated DTC: 243";
CM_ SG_ 1369 Cell_overvoltage "Associated DTC: 10";
CM_ SG_ 1369 Cell_undervoltage "Associated DTC: 11, 52";
CM_ SG_ 1369 Comm_failure_with_CMU "Associated DTC: 17";
CM_ SG_ 1369 Internal_CMU_error "Associated DTC: 20, 23, 24, 30, 256, 278";
CM_ SG_ 1369 Internal_CMU_temperature_error "Associated DTC: 25";
CM_ SG_ 1369 Internal_CMU_voltage_reference "Associated DTC: 26";
CM_ SG_ 1369 Cell_shortcircuit "Associated DTC: 27";
CM_ SG_ 1369 Battery_overcurrent "Associated DTC: 28";
CM_ SG_ 1369 Overload_ratio_exceeded "Associated DTC: 164";
CM_ SG_ 1369 Current_sensor_errors "Associated DTC: 22, 34, 79, 167, 229, 239, 277";
CM_ SG_ 1369 BMU_temperature_errors "Associated DTC: 169, 264";
CM_ SG_ 1369 Cell_overtemperature "Associated DTC: 12";
CM_ SG_ 1369 Cell_undertemperature "Associated DTC: 13";
CM_ SG_ 1369 Balancing_overtemperature "Associated DTC: 14";
CM_ SG_ 1369 Balancing_undertemperature "Associated DTC: 15";
CM_ SG_ 1369 Max_op_cell_temp_delta "Associated DTC: 32";
CM_ SG_ 1369 Thermal_runaway "Associated DTC: 16";
CM_ SG_ 1369 OW_and_SC_detected_on_cell "Associated DTC: 31";
CM_ SG_ 1369 BMU_external_overtemperature "Associated DTC: 261, 262, 263";
CM_ SG_ 1369 Battery_undervoltage "Associated DTC: 29";
CM_ SG_ 1369 BMU_supply_voltage_error "Associated DTC: 168";
CM_ SG_ 1369 Battery_overvoltage "Associated DTC: 18";
CM_ SG_ 1369 Cells_unbalanced "Associated DTC: 33, 265";
CM_ SG_ 1369 Advanced_relaxation_voltage_delt "Associated DTC: 19";
CM_ SG_ 1369 Internal_BMU_error "Associated DTC: 63, 77, 170, 176, 183, 184, 249, 260";
CM_ SG_ 1369 Safety_sensor_error "Associated DTC: 246";
CM_ SG_ 1369 High_voltage_sensor_errors "Associated DTC: 61, 240, 273, 274, 275";
CM_ SG_ 1369 IMD_errors "Associated DTC: 276, 279";
CM_ SG_ 1369 Isolation_error "Associated DTC: 174";
CM_ SG_ 1369 BMU_SoC_errors "Associted DTC: 35, 36, 55";
CM_ SG_ 1369 BMU_SoH_error "Associated DTC: 37";
CM_ SG_ 1369 Contactor_stuck_open_errors "Associated DTC: 73, 269, 270";
CM_ SG_ 1369 Contactor_stuck_closed_errors "Associated DTC: 252, 253, 254, 271, 272";
CM_ SG_ 1369 Contactor_supply_error "Associated DTC: 76";
CM_ SG_ 1369 Contactor_precharge_error "Associated DTC: 75";
CM_ SG_ 1369 Emergency_button_error "Associated DTC: 175";
CM_ SG_ 1369 Actuation_errors "Associated DTC: 91, 186";
CM_ SG_ 1369 Auto_OFF "Associated DTC: 185";
CM_ SG_ 1369 Mode_mismatch "Associated DTC: 250";
CM_ SG_ 1369 Open_wire_errors "Associated DTC: 21, 257";
CM_ SG_ 1369 Output_driver_errors_diagnostics "Associated DTC: 74, 78";
CM_ SG_ 1369 User_forced_errors "Associated DTC: 89, 94";
CM_ SG_ 1369 SD_error "Associated DTC: 177";
CM_ SG_ 1369 Ethernet_module_error "Associated DTC: 6";
CM_ SG_ 1369 Internal_memory_errors "Associated DTC: 83, 84, 85, 212";
CM_ SG_ 1370 System_errors "Associated DTC: 156, 157, 158, 159, 160, 162, 163, 197, 228, 266, 267";
CM_ SG_ 1370 Architecture_configuration_error "Associated DTC: 187, 189, 190, 191, 192, 193, 194, 195";
CM_ SG_ 1370 Parallelization_voltage_errors "Associated DTC: 280";
CM_ SG_ 1370 General_configuration_errors "Associated DTC: 67, 69, 70, 72, 244, 245, 268";
CM_ SG_ 1370 Parallelization_comm_lost_primar "Associated DTC: 243";
CM_ SG_ 1370 Cell_overvoltage "Associated DTC: 10";
CM_ SG_ 1370 Cell_undervoltage "Associated DTC: 11, 52";
CM_ SG_ 1370 Comm_failure_with_CMU "Associated DTC: 17";
CM_ SG_ 1370 Internal_CMU_error "Associated DTC: 20, 23, 24, 30, 256, 278";
CM_ SG_ 1370 Internal_CMU_temperature_error "Associated DTC: 25";
CM_ SG_ 1370 Internal_CMU_voltage_reference "Associated DTC: 26";
CM_ SG_ 1370 Cell_shortcircuit "Associated DTC: 27";
CM_ SG_ 1370 Battery_overcurrent "Associated DTC: 28";
CM_ SG_ 1370 Overload_ratio_exceeded "Associated DTC: 164";
CM_ SG_ 1370 Current_sensor_errors "Associated DTC: 22, 34, 79, 167, 229, 239, 277";
CM_ SG_ 1370 BMU_temperature_errors "Associated DTC: 169, 264";
CM_ SG_ 1370 Cell_overtemperature "Associated DTC: 12";
CM_ SG_ 1370 Cell_undertemperature "Associated DTC: 13";
CM_ SG_ 1370 Balancing_overtemperature "Associated DTC: 14";
CM_ SG_ 1370 Balancing_undertemperature "Associated DTC: 15";
CM_ SG_ 1370 Max_op_cell_temp_delta "Associated DTC: 32";
CM_ SG_ 1370 Thermal_runaway "Associated DTC: 16";
CM_ SG_ 1370 OW_and_SC_detected_on_cell "Associated DTC: 31";
CM_ SG_ 1370 BMU_external_overtemperature "Associated DTC: 261, 262, 263";
CM_ SG_ 1370 Battery_undervoltage "Associated DTC: 29";
CM_ SG_ 1370 BMU_supply_voltage_error "Associated DTC: 168";
CM_ SG_ 1370 Battery_overvoltage "Associated DTC: 18";
CM_ SG_ 1370 Cells_unbalanced "Associated DTC: 33, 265";
CM_ SG_ 1370 Advanced_relaxation_voltage_delt "Associated DTC: 19";
CM_ SG_ 1370 Internal_BMU_error "Associated DTC: 63, 77, 170, 176, 183, 184, 249, 260";
CM_ SG_ 1370 Safety_sensor_error "Associated DTC: 246";
CM_ SG_ 1370 High_voltage_sensor_errors "Associated DTC: 61, 240, 273, 274, 275";
CM_ SG_ 1370 IMD_errors "Associated DTC: 276, 279";
CM_ SG_ 1370 Isolation_error "Associated DTC: 174";
CM_ SG_ 1370 BMU_SoC_errors "Associted DTC: 35, 36, 55";
CM_ SG_ 1370 BMU_SoH_error "Associated DTC: 37";
CM_ SG_ 1370 Contactor_stuck_open_errors "Associated DTC: 73, 269, 270";
CM_ SG_ 1370 Contactor_stuck_closed_errors "Associated DTC: 252, 253, 254, 271, 272";
CM_ SG_ 1370 Contactor_supply_error "Associated DTC: 76";
CM_ SG_ 1370 Contactor_precharge_error "Associated DTC: 75";
CM_ SG_ 1370 Emergency_button_error "Associated DTC: 175";
CM_ SG_ 1370 Actuation_errors "Associated DTC: 91, 186";
CM_ SG_ 1370 Auto_OFF "Associated DTC: 185";
CM_ SG_ 1370 Mode_mismatch "Associated DTC: 250";
CM_ SG_ 1370 Open_wire_errors "Associated DTC: 21, 257";
CM_ SG_ 1370 Output_driver_errors_diagnostics "Associated DTC: 74, 78";
CM_ SG_ 1370 User_forced_errors "Associated DTC: 89, 94";
CM_ SG_ 1370 SD_error "Associated DTC: 177";
CM_ SG_ 1370 Ethernet_module_error "Associated DTC: 6";
CM_ SG_ 1370 Internal_memory_errors "Associated DTC: 83, 84, 85, 212";
CM_ SG_ 1371 System_errors "Associated DTC: 156, 157, 158, 159, 160, 162, 163, 197, 228, 266, 267";
CM_ SG_ 1371 Architecture_configuration_error "Associated DTC: 187, 189, 190, 191, 192, 193, 194, 195";
CM_ SG_ 1371 Parallelization_voltage_errors "Associated DTC: 280";
CM_ SG_ 1371 General_configuration_errors "Associated DTC: 67, 69, 70, 72, 244, 245, 268";
CM_ SG_ 1371 Parallelization_comm_lost_primar "Associated DTC: 243";
CM_ SG_ 1371 Cell_overvoltage "Associated DTC: 10";
CM_ SG_ 1371 Cell_undervoltage "Associated DTC: 11, 52";
CM_ SG_ 1371 Comm_failure_with_CMU "Associated DTC: 17";
CM_ SG_ 1371 Internal_CMU_error "Associated DTC: 20, 23, 24, 30, 256, 278";
CM_ SG_ 1371 Internal_CMU_temperature_error "Associated DTC: 25";
CM_ SG_ 1371 Internal_CMU_voltage_reference "Associated DTC: 26";
CM_ SG_ 1371 Cell_shortcircuit "Associated DTC: 27";
CM_ SG_ 1371 Battery_overcurrent "Associated DTC: 28";
CM_ SG_ 1371 Overload_ratio_exceeded "Associated DTC: 164";
CM_ SG_ 1371 Current_sensor_errors "Associated DTC: 22, 34, 79, 167, 229, 239, 277";
CM_ SG_ 1371 BMU_temperature_errors "Associated DTC: 169, 264";
CM_ SG_ 1371 Cell_overtemperature "Associated DTC: 12";
CM_ SG_ 1371 Cell_undertemperature "Associated DTC: 13";
CM_ SG_ 1371 Balancing_overtemperature "Associated DTC: 14";
CM_ SG_ 1371 Balancing_undertemperature "Associated DTC: 15";
CM_ SG_ 1371 Max_op_cell_temp_delta "Associated DTC: 32";
CM_ SG_ 1371 Thermal_runaway "Associated DTC: 16";
CM_ SG_ 1371 OW_and_SC_detected_on_cell "Associated DTC: 31";
CM_ SG_ 1371 BMU_external_overtemperature "Associated DTC: 261, 262, 263";
CM_ SG_ 1371 Battery_undervoltage "Associated DTC: 29";
CM_ SG_ 1371 BMU_supply_voltage_error "Associated DTC: 168";
CM_ SG_ 1371 Battery_overvoltage "Associated DTC: 18";
CM_ SG_ 1371 Cells_unbalanced "Associated DTC: 33, 265";
CM_ SG_ 1371 Advanced_relaxation_voltage_delt "Associated DTC: 19";
CM_ SG_ 1371 Internal_BMU_error "Associated DTC: 63, 77, 170, 176, 183, 184, 249, 260";
CM_ SG_ 1371 Safety_sensor_error "Associated DTC: 246";
CM_ SG_ 1371 High_voltage_sensor_errors "Associated DTC: 61, 240, 273, 274, 275";
CM_ SG_ 1371 IMD_errors "Associated DTC: 276, 279";
CM_ SG_ 1371 Isolation_error "Associated DTC: 174";
CM_ SG_ 1371 BMU_SoC_errors "Associted DTC: 35, 36, 55";
CM_ SG_ 1371 BMU_SoH_error "Associated DTC: 37";
CM_ SG_ 1371 Contactor_stuck_open_errors "Associated DTC: 73, 269, 270";
CM_ SG_ 1371 Contactor_stuck_closed_errors "Associated DTC: 252, 253, 254, 271, 272";
CM_ SG_ 1371 Contactor_supply_error "Associated DTC: 76";
CM_ SG_ 1371 Contactor_precharge_error "Associated DTC: 75";
CM_ SG_ 1371 Emergency_button_error "Associated DTC: 175";
CM_ SG_ 1371 Actuation_errors "Associated DTC: 91, 186";
CM_ SG_ 1371 Auto_OFF "Associated DTC: 185";
CM_ SG_ 1371 Mode_mismatch "Associated DTC: 250";
CM_ SG_ 1371 Open_wire_errors "Associated DTC: 21, 257";
CM_ SG_ 1371 Output_driver_errors_diagnostics "Associated DTC: 74, 78";
CM_ SG_ 1371 User_forced_errors "Associated DTC: 89, 94";
CM_ SG_ 1371 SD_error "Associated DTC: 177";
CM_ SG_ 1371 Ethernet_module_error "Associated DTC: 6";
CM_ SG_ 1371 Internal_memory_errors "Associated DTC: 83, 84, 85, 212";
CM_ SG_ 1372 System_errors "Associated DTC: 156, 157, 158, 159, 160, 162, 163, 197, 228, 266, 267";
CM_ SG_ 1372 Architecture_configuration_error "Associated DTC: 187, 189, 190, 191, 192, 193, 194, 195";
CM_ SG_ 1372 Parallelization_voltage_errors "Associated DTC: 280";
CM_ SG_ 1372 General_configuration_errors "Associated DTC: 67, 69, 70, 72, 244, 245, 268";
CM_ SG_ 1372 Parallelization_comm_lost_primar "Associated DTC: 243";
CM_ SG_ 1372 Cell_overvoltage "Associated DTC: 10";
CM_ SG_ 1372 Cell_undervoltage "Associated DTC: 11, 52";
CM_ SG_ 1372 Comm_failure_with_CMU "Associated DTC: 17";
CM_ SG_ 1372 Internal_CMU_error "Associated DTC: 20, 23, 24, 30, 256, 278";
CM_ SG_ 1372 Internal_CMU_temperature_error "Associated DTC: 25";
CM_ SG_ 1372 Internal_CMU_voltage_reference "Associated DTC: 26";
CM_ SG_ 1372 Cell_shortcircuit "Associated DTC: 27";
CM_ SG_ 1372 Battery_overcurrent "Associated DTC: 28";
CM_ SG_ 1372 Overload_ratio_exceeded "Associated DTC: 164";
CM_ SG_ 1372 Current_sensor_errors "Associated DTC: 22, 34, 79, 167, 229, 239, 277";
CM_ SG_ 1372 BMU_temperature_errors "Associated DTC: 169, 264";
CM_ SG_ 1372 Cell_overtemperature "Associated DTC: 12";
CM_ SG_ 1372 Cell_undertemperature "Associated DTC: 13";
CM_ SG_ 1372 Balancing_overtemperature "Associated DTC: 14";
CM_ SG_ 1372 Balancing_undertemperature "Associated DTC: 15";
CM_ SG_ 1372 Max_op_cell_temp_delta "Associated DTC: 32";
CM_ SG_ 1372 Thermal_runaway "Associated DTC: 16";
CM_ SG_ 1372 OW_and_SC_detected_on_cell "Associated DTC: 31";
CM_ SG_ 1372 BMU_external_overtemperature "Associated DTC: 261, 262, 263";
CM_ SG_ 1372 Battery_undervoltage "Associated DTC: 29";
CM_ SG_ 1372 BMU_supply_voltage_error "Associated DTC: 168";
CM_ SG_ 1372 Battery_overvoltage "Associated DTC: 18";
CM_ SG_ 1372 Cells_unbalanced "Associated DTC: 33, 265";
CM_ SG_ 1372 Advanced_relaxation_voltage_delt "Associated DTC: 19";
CM_ SG_ 1372 Internal_BMU_error "Associated DTC: 63, 77, 170, 176, 183, 184, 249, 260";
CM_ SG_ 1372 Safety_sensor_error "Associated DTC: 246";
CM_ SG_ 1372 High_voltage_sensor_errors "Associated DTC: 61, 240, 273, 274, 275";
CM_ SG_ 1372 IMD_errors "Associated DTC: 276, 279";
CM_ SG_ 1372 Isolation_error "Associated DTC: 174";
CM_ SG_ 1372 BMU_SoC_errors "Associted DTC: 35, 36, 55";
CM_ SG_ 1372 BMU_SoH_error "Associated DTC: 37";
CM_ SG_ 1372 Contactor_stuck_open_errors "Associated DTC: 73, 269, 270";
CM_ SG_ 1372 Contactor_stuck_closed_errors "Associated DTC: 252, 253, 254, 271, 272";
CM_ SG_ 1372 Contactor_supply_error "Associated DTC: 76";
CM_ SG_ 1372 Contactor_precharge_error "Associated DTC: 75";
CM_ SG_ 1372 Emergency_button_error "Associated DTC: 175";
CM_ SG_ 1372 Actuation_errors "Associated DTC: 91, 186";
CM_ SG_ 1372 Auto_OFF "Associated DTC: 185";
CM_ SG_ 1372 Mode_mismatch "Associated DTC: 250";
CM_ SG_ 1372 Open_wire_errors "Associated DTC: 21, 257";
CM_ SG_ 1372 Output_driver_errors_diagnostics "Associated DTC: 74, 78";
CM_ SG_ 1372 User_forced_errors "Associated DTC: 89, 94";
CM_ SG_ 1372 SD_error "Associated DTC: 177";
CM_ SG_ 1372 Ethernet_module_error "Associated DTC: 6";
CM_ SG_ 1372 Internal_memory_errors "Associated DTC: 83, 84, 85, 212";
CM_ SG_ 1373 System_errors "Associated DTC: 156, 157, 158, 159, 160, 162, 163, 197, 228, 266, 267";
CM_ SG_ 1373 Architecture_configuration_error "Associated DTC: 187, 189, 190, 191, 192, 193, 194, 195";
CM_ SG_ 1373 Parallelization_voltage_errors "Associated DTC: 280";
CM_ SG_ 1373 General_configuration_errors "Associated DTC: 67, 69, 70, 72, 244, 245, 268";
CM_ SG_ 1373 Parallelization_comm_lost_primar "Associated DTC: 243";
CM_ SG_ 1373 Cell_overvoltage "Associated DTC: 10";
CM_ SG_ 1373 Cell_undervoltage "Associated DTC: 11, 52";
CM_ SG_ 1373 Comm_failure_with_CMU "Associated DTC: 17";
CM_ SG_ 1373 Internal_CMU_error "Associated DTC: 20, 23, 24, 30, 256, 278";
CM_ SG_ 1373 Internal_CMU_temperature_error "Associated DTC: 25";
CM_ SG_ 1373 Internal_CMU_voltage_reference "Associated DTC: 26";
CM_ SG_ 1373 Cell_shortcircuit "Associated DTC: 27";
CM_ SG_ 1373 Battery_overcurrent "Associated DTC: 28";
CM_ SG_ 1373 Overload_ratio_exceeded "Associated DTC: 164";
CM_ SG_ 1373 Current_sensor_errors "Associated DTC: 22, 34, 79, 167, 229, 239, 277";
CM_ SG_ 1373 BMU_temperature_errors "Associated DTC: 169, 264";
CM_ SG_ 1373 Cell_overtemperature "Associated DTC: 12";
CM_ SG_ 1373 Cell_undertemperature "Associated DTC: 13";
CM_ SG_ 1373 Balancing_overtemperature "Associated DTC: 14";
CM_ SG_ 1373 Balancing_undertemperature "Associated DTC: 15";
CM_ SG_ 1373 Max_op_cell_temp_delta "Associated DTC: 32";
CM_ SG_ 1373 Thermal_runaway "Associated DTC: 16";
CM_ SG_ 1373 OW_and_SC_detected_on_cell "Associated DTC: 31";
CM_ SG_ 1373 BMU_external_overtemperature "Associated DTC: 261, 262, 263";
CM_ SG_ 1373 Battery_undervoltage "Associated DTC: 29";
CM_ SG_ 1373 BMU_supply_voltage_error "Associated DTC: 168";
CM_ SG_ 1373 Battery_overvoltage "Associated DTC: 18";
CM_ SG_ 1373 Cells_unbalanced "Associated DTC: 33, 265";
CM_ SG_ 1373 Advanced_relaxation_voltage_delt "Associated DTC: 19";
CM_ SG_ 1373 Internal_BMU_error "Associated DTC: 63, 77, 170, 176, 183, 184, 249, 260";
CM_ SG_ 1373 Safety_sensor_error "Associated DTC: 246";
CM_ SG_ 1373 High_voltage_sensor_errors "Associated DTC: 61, 240, 273, 274, 275";
CM_ SG_ 1373 IMD_errors "Associated DTC: 276, 279";
CM_ SG_ 1373 Isolation_error "Associated DTC: 174";
CM_ SG_ 1373 BMU_SoC_errors "Associted DTC: 35, 36, 55";
CM_ SG_ 1373 BMU_SoH_error "Associated DTC: 37";
CM_ SG_ 1373 Contactor_stuck_open_errors "Associated DTC: 73, 269, 270";
CM_ SG_ 1373 Contactor_stuck_closed_errors "Associated DTC: 252, 253, 254, 271, 272";
CM_ SG_ 1373 Contactor_supply_error "Associated DTC: 76";
CM_ SG_ 1373 Contactor_precharge_error "Associated DTC: 75";
CM_ SG_ 1373 Emergency_button_error "Associated DTC: 175";
CM_ SG_ 1373 Actuation_errors "Associated DTC: 91, 186";
CM_ SG_ 1373 Auto_OFF "Associated DTC: 185";
CM_ SG_ 1373 Mode_mismatch "Associated DTC: 250";
CM_ SG_ 1373 Open_wire_errors "Associated DTC: 21, 257";
CM_ SG_ 1373 Output_driver_errors_diagnostics "Associated DTC: 74, 78";
CM_ SG_ 1373 User_forced_errors "Associated DTC: 89, 94";
CM_ SG_ 1373 SD_error "Associated DTC: 177";
CM_ SG_ 1373 Ethernet_module_error "Associated DTC: 6";
CM_ SG_ 1373 Internal_memory_errors "Associated DTC: 83, 84, 85, 212";
CM_ SG_ 1374 System_errors "Associated DTC: 156, 157, 158, 159, 160, 162, 163, 197, 228, 266, 267";
CM_ SG_ 1374 Architecture_configuration_error "Associated DTC: 187, 189, 190, 191, 192, 193, 194, 195";
CM_ SG_ 1374 Parallelization_voltage_errors "Associated DTC: 280";
CM_ SG_ 1374 General_configuration_errors "Associated DTC: 67, 69, 70, 72, 244, 245, 268";
CM_ SG_ 1374 Parallelization_comm_lost_primar "Associated DTC: 243";
CM_ SG_ 1374 Cell_overvoltage "Associated DTC: 10";
CM_ SG_ 1374 Cell_undervoltage "Associated DTC: 11, 52";
CM_ SG_ 1374 Comm_failure_with_CMU "Associated DTC: 17";
CM_ SG_ 1374 Internal_CMU_error "Associated DTC: 20, 23, 24, 30, 256, 278";
CM_ SG_ 1374 Internal_CMU_temperature_error "Associated DTC: 25";
CM_ SG_ 1374 Internal_CMU_voltage_reference "Associated DTC: 26";
CM_ SG_ 1374 Cell_shortcircuit "Associated DTC: 27";
CM_ SG_ 1374 Battery_overcurrent "Associated DTC: 28";
CM_ SG_ 1374 Overload_ratio_exceeded "Associated DTC: 164";
CM_ SG_ 1374 Current_sensor_errors "Associated DTC: 22, 34, 79, 167, 229, 239, 277";
CM_ SG_ 1374 BMU_temperature_errors "Associated DTC: 169, 264";
CM_ SG_ 1374 Cell_overtemperature "Associated DTC: 12";
CM_ SG_ 1374 Cell_undertemperature "Associated DTC: 13";
CM_ SG_ 1374 Balancing_overtemperature "Associated DTC: 14";
CM_ SG_ 1374 Balancing_undertemperature "Associated DTC: 15";
CM_ SG_ 1374 Max_op_cell_temp_delta "Associated DTC: 32";
CM_ SG_ 1374 Thermal_runaway "Associated DTC: 16";
CM_ SG_ 1374 OW_and_SC_detected_on_cell "Associated DTC: 31";
CM_ SG_ 1374 BMU_external_overtemperature "Associated DTC: 261, 262, 263";
CM_ SG_ 1374 Battery_undervoltage "Associated DTC: 29";
CM_ SG_ 1374 BMU_supply_voltage_error "Associated DTC: 168";
CM_ SG_ 1374 Battery_overvoltage "Associated DTC: 18";
CM_ SG_ 1374 Cells_unbalanced "Associated DTC: 33, 265";
CM_ SG_ 1374 Advanced_relaxation_voltage_delt "Associated DTC: 19";
CM_ SG_ 1374 Internal_BMU_error "Associated DTC: 63, 77, 170, 176, 183, 184, 249, 260";
CM_ SG_ 1374 Safety_sensor_error "Associated DTC: 246";
CM_ SG_ 1374 High_voltage_sensor_errors "Associated DTC: 61, 240, 273, 274, 275";
CM_ SG_ 1374 IMD_errors "Associated DTC: 276, 279";
CM_ SG_ 1374 Isolation_error "Associated DTC: 174";
CM_ SG_ 1374 BMU_SoC_errors "Associted DTC: 35, 36, 55";
CM_ SG_ 1374 BMU_SoH_error "Associated DTC: 37";
CM_ SG_ 1374 Contactor_stuck_open_errors "Associated DTC: 73, 269, 270";
CM_ SG_ 1374 Contactor_stuck_closed_errors "Associated DTC: 252, 253, 254, 271, 272";
CM_ SG_ 1374 Contactor_supply_error "Associated DTC: 76";
CM_ SG_ 1374 Contactor_precharge_error "Associated DTC: 75";
CM_ SG_ 1374 Emergency_button_error "Associated DTC: 175";
CM_ SG_ 1374 Actuation_errors "Associated DTC: 91, 186";
CM_ SG_ 1374 Auto_OFF "Associated DTC: 185";
CM_ SG_ 1374 Mode_mismatch "Associated DTC: 250";
CM_ SG_ 1374 Open_wire_errors "Associated DTC: 21, 257";
CM_ SG_ 1374 Output_driver_errors_diagnostics "Associated DTC: 74, 78";
CM_ SG_ 1374 User_forced_errors "Associated DTC: 89, 94";
CM_ SG_ 1374 SD_error "Associated DTC: 177";
CM_ SG_ 1374 Ethernet_module_error "Associated DTC: 6";
CM_ SG_ 1374 Internal_memory_errors "Associated DTC: 83, 84, 85, 212";
CM_ SG_ 1375 System_errors "Associated DTC: 156, 157, 158, 159, 160, 162, 163, 197, 228, 266, 267";
CM_ SG_ 1375 Architecture_configuration_error "Associated DTC: 187, 189, 190, 191, 192, 193, 194, 195";
CM_ SG_ 1375 Parallelization_voltage_errors "Associated DTC: 280";
CM_ SG_ 1375 General_configuration_errors "Associated DTC: 67, 69, 70, 72, 244, 245, 268";
CM_ SG_ 1375 Parallelization_comm_lost_primar "Associated DTC: 243";
CM_ SG_ 1375 Cell_overvoltage "Associated DTC: 10";
CM_ SG_ 1375 Cell_undervoltage "Associated DTC: 11, 52";
CM_ SG_ 1375 Comm_failure_with_CMU "Associated DTC: 17";
CM_ SG_ 1375 Internal_CMU_error "Associated DTC: 20, 23, 24, 30, 256, 278";
CM_ SG_ 1375 Internal_CMU_temperature_error "Associated DTC: 25";
CM_ SG_ 1375 Internal_CMU_voltage_reference "Associated DTC: 26";
CM_ SG_ 1375 Cell_shortcircuit "Associated DTC: 27";
CM_ SG_ 1375 Battery_overcurrent "Associated DTC: 28";
CM_ SG_ 1375 Overload_ratio_exceeded "Associated DTC: 164";
CM_ SG_ 1375 Current_sensor_errors "Associated DTC: 22, 34, 79, 167, 229, 239, 277";
CM_ SG_ 1375 BMU_temperature_errors "Associated DTC: 169, 264";
CM_ SG_ 1375 Cell_overtemperature "Associated DTC: 12";
CM_ SG_ 1375 Cell_undertemperature "Associated DTC: 13";
CM_ SG_ 1375 Balancing_overtemperature "Associated DTC: 14";
CM_ SG_ 1375 Balancing_undertemperature "Associated DTC: 15";
CM_ SG_ 1375 Max_op_cell_temp_delta "Associated DTC: 32";
CM_ SG_ 1375 Thermal_runaway "Associated DTC: 16";
CM_ SG_ 1375 OW_and_SC_detected_on_cell "Associated DTC: 31";
CM_ SG_ 1375 BMU_external_overtemperature "Associated DTC: 261, 262, 263";
CM_ SG_ 1375 Battery_undervoltage "Associated DTC: 29";
CM_ SG_ 1375 BMU_supply_voltage_error "Associated DTC: 168";
CM_ SG_ 1375 Battery_overvoltage "Associated DTC: 18";
CM_ SG_ 1375 Cells_unbalanced "Associated DTC: 33, 265";
CM_ SG_ 1375 Advanced_relaxation_voltage_delt "Associated DTC: 19";
CM_ SG_ 1375 Internal_BMU_error "Associated DTC: 63, 77, 170, 176, 183, 184, 249, 260";
CM_ SG_ 1375 Safety_sensor_error "Associated DTC: 246";
CM_ SG_ 1375 High_voltage_sensor_errors "Associated DTC: 61, 240, 273, 274, 275";
CM_ SG_ 1375 IMD_errors "Associated DTC: 276, 279";
CM_ SG_ 1375 Isolation_error "Associated DTC: 174";
CM_ SG_ 1375 BMU_SoC_errors "Associted DTC: 35, 36, 55";
CM_ SG_ 1375 BMU_SoH_error "Associated DTC: 37";
CM_ SG_ 1375 Contactor_stuck_open_errors "Associated DTC: 73, 269, 270";
CM_ SG_ 1375 Contactor_stuck_closed_errors "Associated DTC: 252, 253, 254, 271, 272";
CM_ SG_ 1375 Contactor_supply_error "Associated DTC: 76";
CM_ SG_ 1375 Contactor_precharge_error "Associated DTC: 75";
CM_ SG_ 1375 Emergency_button_error "Associated DTC: 175";
CM_ SG_ 1375 Actuation_errors "Associated DTC: 91, 186";
CM_ SG_ 1375 Auto_OFF "Associated DTC: 185";
CM_ SG_ 1375 Mode_mismatch "Associated DTC: 250";
CM_ SG_ 1375 Open_wire_errors "Associated DTC: 21, 257";
CM_ SG_ 1375 Output_driver_errors_diagnostics "Associated DTC: 74, 78";
CM_ SG_ 1375 User_forced_errors "Associated DTC: 89, 94";
CM_ SG_ 1375 SD_error "Associated DTC: 177";
CM_ SG_ 1375 Ethernet_module_error "Associated DTC: 6";
CM_ SG_ 1375 Internal_memory_errors "Associated DTC: 83, 84, 85, 212";
CM_ BO_ 1376 "Str = string";
CM_ SG_ 1376 Battery_Pack_voltage "Voltage of the Battery Pack";
CM_ SG_ 1376 Max_string_voltage "Highest string voltage among all individual strings within the Battery Pack";
CM_ SG_ 1376 Min_string_voltage "Lowest string voltage among all individual strings within the Battery Pack";
CM_ SG_ 1376 Max_string_voltage_index "Number of the string with the maximum string voltage";
CM_ SG_ 1376 Min_string_voltage_index "Number of the string with the minimum string voltage";
CM_ BO_ 1377 "Str = string";
CM_ SG_ 1377 Battery_Pack_voltage "Voltage of the Battery Pack";
CM_ SG_ 1377 Max_string_voltage "Highest string voltage among all individual strings within the Battery Pack";
CM_ SG_ 1377 Min_string_voltage "Lowest string voltage among all individual strings within the Battery Pack";
CM_ SG_ 1377 Max_string_voltage_index "Number of the string with the maximum string voltage";
CM_ SG_ 1377 Min_string_voltage_index "Number of the string with the minimum string voltage";
CM_ BO_ 1378 "Str = string";
CM_ SG_ 1378 Battery_Pack_voltage "Voltage of the Battery Pack";
CM_ SG_ 1378 Max_string_voltage "Highest string voltage among all individual strings within the Battery Pack";
CM_ SG_ 1378 Min_string_voltage "Lowest string voltage among all individual strings within the Battery Pack";
CM_ SG_ 1378 Max_string_voltage_index "Number of the string with the maximum string voltage";
CM_ SG_ 1378 Min_string_voltage_index "Number of the string with the minimum string voltage";
CM_ BO_ 1379 "Str = string";
CM_ SG_ 1379 Battery_Pack_voltage "Voltage of the Battery Pack";
CM_ SG_ 1379 Max_string_voltage "Highest string voltage among all individual strings within the Battery Pack";
CM_ SG_ 1379 Min_string_voltage "Lowest string voltage among all individual strings within the Battery Pack";
CM_ SG_ 1379 Max_string_voltage_index "Number of the string with the maximum string voltage";
CM_ SG_ 1379 Min_string_voltage_index "Number of the string with the minimum string voltage";
CM_ BO_ 1380 "Str = string";
CM_ SG_ 1380 Battery_Pack_voltage "Voltage of the Battery Pack";
CM_ SG_ 1380 Max_string_voltage "Highest string voltage among all individual strings within the Battery Pack";
CM_ SG_ 1380 Min_string_voltage "Lowest string voltage among all individual strings within the Battery Pack";
CM_ SG_ 1380 Max_string_voltage_index "Number of the string with the maximum string voltage";
CM_ SG_ 1380 Min_string_voltage_index "Number of the string with the minimum string voltage";
CM_ BO_ 1381 "Str = string";
CM_ SG_ 1381 Battery_Pack_voltage "Voltage of the Battery Pack";
CM_ SG_ 1381 Max_string_voltage "Highest string voltage among all individual strings within the Battery Pack";
CM_ SG_ 1381 Min_string_voltage "Lowest string voltage among all individual strings within the Battery Pack";
CM_ SG_ 1381 Max_string_voltage_index "Number of the string with the maximum string voltage";
CM_ SG_ 1381 Min_string_voltage_index "Number of the string with the minimum string voltage";
CM_ BO_ 1382 "Str = string";
CM_ SG_ 1382 Battery_Pack_voltage "Voltage of the Battery Pack";
CM_ SG_ 1382 Max_string_voltage "Highest string voltage among all individual strings within the Battery Pack";
CM_ SG_ 1382 Min_string_voltage "Lowest string voltage among all individual strings within the Battery Pack";
CM_ SG_ 1382 Max_string_voltage_index "Number of the string with the maximum string voltage";
CM_ SG_ 1382 Min_string_voltage_index "Number of the string with the minimum string voltage";
CM_ BO_ 1383 "Str = string";
CM_ SG_ 1383 Battery_Pack_voltage "Voltage of the Battery Pack";
CM_ SG_ 1383 Max_string_voltage "Highest string voltage among all individual strings within the Battery Pack";
CM_ SG_ 1383 Min_string_voltage "Lowest string voltage among all individual strings within the Battery Pack";
CM_ SG_ 1383 Max_string_voltage_index "Number of the string with the maximum string voltage";
CM_ SG_ 1383 Min_string_voltage_index "Number of the string with the minimum string voltage";
CM_ BO_ 1384 "Str = string";
CM_ SG_ 1384 Battery_Pack_voltage "Voltage of the Battery Pack";
CM_ SG_ 1384 Max_string_voltage "Highest string voltage among all individual strings within the Battery Pack";
CM_ SG_ 1384 Min_string_voltage "Lowest string voltage among all individual strings within the Battery Pack";
CM_ SG_ 1384 Max_string_voltage_index "Number of the string with the maximum string voltage";
CM_ SG_ 1384 Min_string_voltage_index "Number of the string with the minimum string voltage";
CM_ BO_ 1385 "Str = string";
CM_ SG_ 1385 Battery_Pack_voltage "Voltage of the Battery Pack";
CM_ SG_ 1385 Max_string_voltage "Highest string voltage among all individual strings within the Battery Pack";
CM_ SG_ 1385 Min_string_voltage "Lowest string voltage among all individual strings within the Battery Pack";
CM_ SG_ 1385 Max_string_voltage_index "Number of the string with the maximum string voltage";
CM_ SG_ 1385 Min_string_voltage_index "Number of the string with the minimum string voltage";
CM_ BO_ 1386 "Str = string";
CM_ SG_ 1386 Battery_Pack_voltage "Voltage of the Battery Pack";
CM_ SG_ 1386 Max_string_voltage "Highest string voltage among all individual strings within the Battery Pack";
CM_ SG_ 1386 Min_string_voltage "Lowest string voltage among all individual strings within the Battery Pack";
CM_ SG_ 1386 Max_string_voltage_index "Number of the string with the maximum string voltage";
CM_ SG_ 1386 Min_string_voltage_index "Number of the string with the minimum string voltage";
CM_ BO_ 1387 "Str = string";
CM_ SG_ 1387 Battery_Pack_voltage "Voltage of the Battery Pack";
CM_ SG_ 1387 Max_string_voltage "Highest string voltage among all individual strings within the Battery Pack";
CM_ SG_ 1387 Min_string_voltage "Lowest string voltage among all individual strings within the Battery Pack";
CM_ SG_ 1387 Max_string_voltage_index "Number of the string with the maximum string voltage";
CM_ SG_ 1387 Min_string_voltage_index "Number of the string with the minimum string voltage";
CM_ BO_ 1388 "Str = string";
CM_ SG_ 1388 Battery_Pack_voltage "Voltage of the Battery Pack";
CM_ SG_ 1388 Max_string_voltage "Highest string voltage among all individual strings within the Battery Pack";
CM_ SG_ 1388 Min_string_voltage "Lowest string voltage among all individual strings within the Battery Pack";
CM_ SG_ 1388 Max_string_voltage_index "Number of the string with the maximum string voltage";
CM_ SG_ 1388 Min_string_voltage_index "Number of the string with the minimum string voltage";
CM_ BO_ 1389 "Str = string";
CM_ SG_ 1389 Battery_Pack_voltage "Voltage of the Battery Pack";
CM_ SG_ 1389 Max_string_voltage "Highest string voltage among all individual strings within the Battery Pack";
CM_ SG_ 1389 Min_string_voltage "Lowest string voltage among all individual strings within the Battery Pack";
CM_ SG_ 1389 Max_string_voltage_index "Number of the string with the maximum string voltage";
CM_ SG_ 1389 Min_string_voltage_index "Number of the string with the minimum string voltage";
CM_ BO_ 1390 "Str = string";
CM_ SG_ 1390 Battery_Pack_voltage "Voltage of the Battery Pack";
CM_ SG_ 1390 Max_string_voltage "Highest string voltage among all individual strings within the Battery Pack";
CM_ SG_ 1390 Min_string_voltage "Lowest string voltage among all individual strings within the Battery Pack";
CM_ SG_ 1390 Max_string_voltage_index "Number of the string with the maximum string voltage";
CM_ SG_ 1390 Min_string_voltage_index "Number of the string with the minimum string voltage";
CM_ BO_ 1391 "Str = string";
CM_ SG_ 1391 Battery_Pack_voltage "Voltage of the Battery Pack";
CM_ SG_ 1391 Max_string_voltage "Highest string voltage among all individual strings within the Battery Pack";
CM_ SG_ 1391 Min_string_voltage "Lowest string voltage among all individual strings within the Battery Pack";
CM_ SG_ 1391 Min_string_voltage_index "Number of the string with the minimum string voltage";
CM_ SG_ 1408 Cell_voltage_maximum_value "Highest cell voltage measured";
CM_ SG_ 1408 Cell_voltage_minimum_value "Lowest cell voltage measured";
CM_ SG_ 1408 Cell_voltage_max_channel_index "ID of the CMU�s channel measuring the maximum cell voltage";
CM_ SG_ 1408 Cell_voltage_max_cmu_index "ID of the CMU containing the maximum cell voltage";
CM_ SG_ 1408 Cell_voltage_min_channel_index "ID of the CMU�s channel measuring the minimum cell voltage";
CM_ SG_ 1408 Cell_voltage_min_cmu_index "ID of the CMU containing the minimum cell voltage";
CM_ SG_ 1408 Cell_temp_maximum_value "Highest cell temperature measured";
CM_ SG_ 1408 Cell_temp_minimum_value "Lowest cell temperature measured";
CM_ SG_ 1408 Cell_temp_average_value "Average cell temperature measured";
CM_ SG_ 1408 Cell_temp_max_cmu_index "ID of the CMU�s channel measuring the maximum cell temperature";
CM_ SG_ 1408 Cell_temp_max_channel_index "ID of the CMU containing the maximum cell temperature";
CM_ SG_ 1408 Cell_temp_min_cmu_index "ID of the CMU�s channel measuring the minimum cell temperature";
CM_ SG_ 1408 Cell_temp_min_channel_index "ID of the CMU containing the minimum cell temperature";
CM_ SG_ 1408 Balancing_temp_maximum_value "Highest balancing temperature measured";
CM_ SG_ 1408 Balancing_temp_minimum_value "Lowest balancing temperature measured";
CM_ SG_ 1408 Balancing_temp_average_value "Average balancing temperature measured";
CM_ SG_ 1408 Balancing_temp_max_cmu_index "ID of the CMU containing the maximum balancing temperature";
CM_ SG_ 1408 Balancing_temp_min_cmu_index "ID of the CMU containing the minimum balancing temperature";
CM_ SG_ 1408 Cell_voltage_average_value "Average cell voltage measured";
CM_ SG_ 1409 Cell_voltage_maximum_value "Highest cell voltage measured";
CM_ SG_ 1409 Cell_voltage_minimum_value "Lowest cell voltage measured";
CM_ SG_ 1409 Cell_voltage_max_channel_index "ID of the CMU�s channel measuring the maximum cell voltage";
CM_ SG_ 1409 Cell_voltage_max_cmu_index "ID of the CMU containing the maximum cell voltage";
CM_ SG_ 1409 Cell_voltage_min_channel_index "ID of the CMU�s channel measuring the minimum cell voltage";
CM_ SG_ 1409 Cell_voltage_min_cmu_index "ID of the CMU containing the minimum cell voltage";
CM_ SG_ 1409 Cell_temp_maximum_value "Highest cell temperature measured";
CM_ SG_ 1409 Cell_temp_minimum_value "Lowest cell temperature measured";
CM_ SG_ 1409 Cell_temp_average_value "Average cell temperature measured";
CM_ SG_ 1409 Cell_temp_max_cmu_index "ID of the CMU�s channel measuring the maximum cell temperature";
CM_ SG_ 1409 Cell_temp_max_channel_index "ID of the CMU containing the maximum cell temperature";
CM_ SG_ 1409 Cell_temp_min_cmu_index "ID of the CMU�s channel measuring the minimum cell temperature";
CM_ SG_ 1409 Cell_temp_min_channel_index "ID of the CMU containing the minimum cell temperature";
CM_ SG_ 1409 Balancing_temp_maximum_value "Highest balancing temperature measured";
CM_ SG_ 1409 Balancing_temp_minimum_value "Lowest balancing temperature measured";
CM_ SG_ 1409 Balancing_temp_average_value "Average balancing temperature measured";
CM_ SG_ 1409 Balancing_temp_max_cmu_index "ID of the CMU containing the maximum balancing temperature";
CM_ SG_ 1409 Balancing_temp_min_cmu_index "ID of the CMU containing the minimum balancing temperature";
CM_ SG_ 1409 Cell_voltage_average_value "Average cell voltage measured";
CM_ SG_ 1410 Cell_voltage_maximum_value "Highest cell voltage measured";
CM_ SG_ 1410 Cell_voltage_minimum_value "Lowest cell voltage measured";
CM_ SG_ 1410 Cell_voltage_max_channel_index "ID of the CMU�s channel measuring the maximum cell voltage";
CM_ SG_ 1410 Cell_voltage_max_cmu_index "ID of the CMU containing the maximum cell voltage";
CM_ SG_ 1410 Cell_voltage_min_channel_index "ID of the CMU�s channel measuring the minimum cell voltage";
CM_ SG_ 1410 Cell_voltage_min_cmu_index "ID of the CMU containing the minimum cell voltage";
CM_ SG_ 1410 Cell_temp_maximum_value "Highest cell temperature measured";
CM_ SG_ 1410 Cell_temp_minimum_value "Lowest cell temperature measured";
CM_ SG_ 1410 Cell_temp_average_value "Average cell temperature measured";
CM_ SG_ 1410 Cell_temp_max_cmu_index "ID of the CMU�s channel measuring the maximum cell temperature";
CM_ SG_ 1410 Cell_temp_max_channel_index "ID of the CMU containing the maximum cell temperature";
CM_ SG_ 1410 Cell_temp_min_cmu_index "ID of the CMU�s channel measuring the minimum cell temperature";
CM_ SG_ 1410 Cell_temp_min_channel_index "ID of the CMU containing the minimum cell temperature";
CM_ SG_ 1410 Balancing_temp_maximum_value "Highest balancing temperature measured";
CM_ SG_ 1410 Balancing_temp_minimum_value "Lowest balancing temperature measured";
CM_ SG_ 1410 Balancing_temp_average_value "Average balancing temperature measured";
CM_ SG_ 1410 Balancing_temp_max_cmu_index "ID of the CMU containing the maximum balancing temperature";
CM_ SG_ 1410 Balancing_temp_min_cmu_index "ID of the CMU containing the minimum balancing temperature";
CM_ SG_ 1410 Cell_voltage_average_value "Average cell voltage measured";
CM_ SG_ 1411 Cell_voltage_maximum_value "Highest cell voltage measured";
CM_ SG_ 1411 Cell_voltage_minimum_value "Lowest cell voltage measured";
CM_ SG_ 1411 Cell_voltage_max_channel_index "ID of the CMU�s channel measuring the maximum cell voltage";
CM_ SG_ 1411 Cell_voltage_max_cmu_index "ID of the CMU containing the maximum cell voltage";
CM_ SG_ 1411 Cell_voltage_min_channel_index "ID of the CMU�s channel measuring the minimum cell voltage";
CM_ SG_ 1411 Cell_voltage_min_cmu_index "ID of the CMU containing the minimum cell voltage";
CM_ SG_ 1411 Cell_temp_maximum_value "Highest cell temperature measured";
CM_ SG_ 1411 Cell_temp_minimum_value "Lowest cell temperature measured";
CM_ SG_ 1411 Cell_temp_average_value "Average cell temperature measured";
CM_ SG_ 1411 Cell_temp_max_cmu_index "ID of the CMU�s channel measuring the maximum cell temperature";
CM_ SG_ 1411 Cell_temp_max_channel_index "ID of the CMU containing the maximum cell temperature";
CM_ SG_ 1411 Cell_temp_min_cmu_index "ID of the CMU�s channel measuring the minimum cell temperature";
CM_ SG_ 1411 Cell_temp_min_channel_index "ID of the CMU containing the minimum cell temperature";
CM_ SG_ 1411 Balancing_temp_maximum_value "Highest balancing temperature measured";
CM_ SG_ 1411 Balancing_temp_minimum_value "Lowest balancing temperature measured";
CM_ SG_ 1411 Balancing_temp_average_value "Average balancing temperature measured";
CM_ SG_ 1411 Balancing_temp_max_cmu_index "ID of the CMU containing the maximum balancing temperature";
CM_ SG_ 1411 Balancing_temp_min_cmu_index "ID of the CMU containing the minimum balancing temperature";
CM_ SG_ 1411 Cell_voltage_average_value "Average cell voltage measured";
CM_ SG_ 1412 Cell_voltage_maximum_value "Highest cell voltage measured";
CM_ SG_ 1412 Cell_voltage_minimum_value "Lowest cell voltage measured";
CM_ SG_ 1412 Cell_voltage_max_channel_index "ID of the CMU�s channel measuring the maximum cell voltage";
CM_ SG_ 1412 Cell_voltage_max_cmu_index "ID of the CMU containing the maximum cell voltage";
CM_ SG_ 1412 Cell_voltage_min_channel_index "ID of the CMU�s channel measuring the minimum cell voltage";
CM_ SG_ 1412 Cell_voltage_min_cmu_index "ID of the CMU containing the minimum cell voltage";
CM_ SG_ 1412 Cell_temp_maximum_value "Highest cell temperature measured";
CM_ SG_ 1412 Cell_temp_minimum_value "Lowest cell temperature measured";
CM_ SG_ 1412 Cell_temp_average_value "Average cell temperature measured";
CM_ SG_ 1412 Cell_temp_max_cmu_index "ID of the CMU�s channel measuring the maximum cell temperature";
CM_ SG_ 1412 Cell_temp_max_channel_index "ID of the CMU containing the maximum cell temperature";
CM_ SG_ 1412 Cell_temp_min_cmu_index "ID of the CMU�s channel measuring the minimum cell temperature";
CM_ SG_ 1412 Cell_temp_min_channel_index "ID of the CMU containing the minimum cell temperature";
CM_ SG_ 1412 Balancing_temp_maximum_value "Highest balancing temperature measured";
CM_ SG_ 1412 Balancing_temp_minimum_value "Lowest balancing temperature measured";
CM_ SG_ 1412 Balancing_temp_average_value "Average balancing temperature measured";
CM_ SG_ 1412 Balancing_temp_max_cmu_index "ID of the CMU containing the maximum balancing temperature";
CM_ SG_ 1412 Balancing_temp_min_cmu_index "ID of the CMU containing the minimum balancing temperature";
CM_ SG_ 1412 Cell_voltage_average_value "Average cell voltage measured";
CM_ SG_ 1413 Cell_voltage_maximum_value "Highest cell voltage measured";
CM_ SG_ 1413 Cell_voltage_minimum_value "Lowest cell voltage measured";
CM_ SG_ 1413 Cell_voltage_max_channel_index "ID of the CMU�s channel measuring the maximum cell voltage";
CM_ SG_ 1413 Cell_voltage_max_cmu_index "ID of the CMU containing the maximum cell voltage";
CM_ SG_ 1413 Cell_voltage_min_channel_index "ID of the CMU�s channel measuring the minimum cell voltage";
CM_ SG_ 1413 Cell_voltage_min_cmu_index "ID of the CMU containing the minimum cell voltage";
CM_ SG_ 1413 Cell_temp_maximum_value "Highest cell temperature measured";
CM_ SG_ 1413 Cell_temp_minimum_value "Lowest cell temperature measured";
CM_ SG_ 1413 Cell_temp_average_value "Average cell temperature measured";
CM_ SG_ 1413 Cell_temp_max_cmu_index "ID of the CMU�s channel measuring the maximum cell temperature";
CM_ SG_ 1413 Cell_temp_max_channel_index "ID of the CMU containing the maximum cell temperature";
CM_ SG_ 1413 Cell_temp_min_cmu_index "ID of the CMU�s channel measuring the minimum cell temperature";
CM_ SG_ 1413 Cell_temp_min_channel_index "ID of the CMU containing the minimum cell temperature";
CM_ SG_ 1413 Balancing_temp_maximum_value "Highest balancing temperature measured";
CM_ SG_ 1413 Balancing_temp_minimum_value "Lowest balancing temperature measured";
CM_ SG_ 1413 Balancing_temp_average_value "Average balancing temperature measured";
CM_ SG_ 1413 Balancing_temp_max_cmu_index "ID of the CMU containing the maximum balancing temperature";
CM_ SG_ 1413 Balancing_temp_min_cmu_index "ID of the CMU containing the minimum balancing temperature";
CM_ SG_ 1413 Cell_voltage_average_value "Average cell voltage measured";
CM_ SG_ 1414 Cell_voltage_maximum_value "Highest cell voltage measured";
CM_ SG_ 1414 Cell_voltage_minimum_value "Lowest cell voltage measured";
CM_ SG_ 1414 Cell_voltage_max_channel_index "ID of the CMU�s channel measuring the maximum cell voltage";
CM_ SG_ 1414 Cell_voltage_max_cmu_index "ID of the CMU containing the maximum cell voltage";
CM_ SG_ 1414 Cell_voltage_min_channel_index "ID of the CMU�s channel measuring the minimum cell voltage";
CM_ SG_ 1414 Cell_voltage_min_cmu_index "ID of the CMU containing the minimum cell voltage";
CM_ SG_ 1414 Cell_temp_maximum_value "Highest cell temperature measured";
CM_ SG_ 1414 Cell_temp_minimum_value "Lowest cell temperature measured";
CM_ SG_ 1414 Cell_temp_average_value "Average cell temperature measured";
CM_ SG_ 1414 Cell_temp_max_cmu_index "ID of the CMU�s channel measuring the maximum cell temperature";
CM_ SG_ 1414 Cell_temp_max_channel_index "ID of the CMU containing the maximum cell temperature";
CM_ SG_ 1414 Cell_temp_min_cmu_index "ID of the CMU�s channel measuring the minimum cell temperature";
CM_ SG_ 1414 Cell_temp_min_channel_index "ID of the CMU containing the minimum cell temperature";
CM_ SG_ 1414 Balancing_temp_maximum_value "Highest balancing temperature measured";
CM_ SG_ 1414 Balancing_temp_minimum_value "Lowest balancing temperature measured";
CM_ SG_ 1414 Balancing_temp_average_value "Average balancing temperature measured";
CM_ SG_ 1414 Balancing_temp_max_cmu_index "ID of the CMU containing the maximum balancing temperature";
CM_ SG_ 1414 Balancing_temp_min_cmu_index "ID of the CMU containing the minimum balancing temperature";
CM_ SG_ 1414 Cell_voltage_average_value "Average cell voltage measured";
CM_ SG_ 1415 Cell_voltage_maximum_value "Highest cell voltage measured";
CM_ SG_ 1415 Cell_voltage_minimum_value "Lowest cell voltage measured";
CM_ SG_ 1415 Cell_voltage_max_channel_index "ID of the CMU�s channel measuring the maximum cell voltage";
CM_ SG_ 1415 Cell_voltage_max_cmu_index "ID of the CMU containing the maximum cell voltage";
CM_ SG_ 1415 Cell_voltage_min_channel_index "ID of the CMU�s channel measuring the minimum cell voltage";
CM_ SG_ 1415 Cell_voltage_min_cmu_index "ID of the CMU containing the minimum cell voltage";
CM_ SG_ 1415 Cell_temp_maximum_value "Highest cell temperature measured";
CM_ SG_ 1415 Cell_temp_minimum_value "Lowest cell temperature measured";
CM_ SG_ 1415 Cell_temp_average_value "Average cell temperature measured";
CM_ SG_ 1415 Cell_temp_max_cmu_index "ID of the CMU�s channel measuring the maximum cell temperature";
CM_ SG_ 1415 Cell_temp_max_channel_index "ID of the CMU containing the maximum cell temperature";
CM_ SG_ 1415 Cell_temp_min_cmu_index "ID of the CMU�s channel measuring the minimum cell temperature";
CM_ SG_ 1415 Cell_temp_min_channel_index "ID of the CMU containing the minimum cell temperature";
CM_ SG_ 1415 Balancing_temp_maximum_value "Highest balancing temperature measured";
CM_ SG_ 1415 Balancing_temp_minimum_value "Lowest balancing temperature measured";
CM_ SG_ 1415 Balancing_temp_average_value "Average balancing temperature measured";
CM_ SG_ 1415 Balancing_temp_max_cmu_index "ID of the CMU containing the maximum balancing temperature";
CM_ SG_ 1415 Balancing_temp_min_cmu_index "ID of the CMU containing the minimum balancing temperature";
CM_ SG_ 1415 Cell_voltage_average_value "Average cell voltage measured";
CM_ SG_ 1416 Cell_voltage_maximum_value "Highest cell voltage measured";
CM_ SG_ 1416 Cell_voltage_minimum_value "Lowest cell voltage measured";
CM_ SG_ 1416 Cell_voltage_max_channel_index "ID of the CMU�s channel measuring the maximum cell voltage";
CM_ SG_ 1416 Cell_voltage_max_cmu_index "ID of the CMU containing the maximum cell voltage";
CM_ SG_ 1416 Cell_voltage_min_channel_index "ID of the CMU�s channel measuring the minimum cell voltage";
CM_ SG_ 1416 Cell_voltage_min_cmu_index "ID of the CMU containing the minimum cell voltage";
CM_ SG_ 1416 Cell_temp_maximum_value "Highest cell temperature measured";
CM_ SG_ 1416 Cell_temp_minimum_value "Lowest cell temperature measured";
CM_ SG_ 1416 Cell_temp_average_value "Average cell temperature measured";
CM_ SG_ 1416 Cell_temp_max_cmu_index "ID of the CMU�s channel measuring the maximum cell temperature";
CM_ SG_ 1416 Cell_temp_max_channel_index "ID of the CMU containing the maximum cell temperature";
CM_ SG_ 1416 Cell_temp_min_cmu_index "ID of the CMU�s channel measuring the minimum cell temperature";
CM_ SG_ 1416 Cell_temp_min_channel_index "ID of the CMU containing the minimum cell temperature";
CM_ SG_ 1416 Balancing_temp_maximum_value "Highest balancing temperature measured";
CM_ SG_ 1416 Balancing_temp_minimum_value "Lowest balancing temperature measured";
CM_ SG_ 1416 Balancing_temp_average_value "Average balancing temperature measured";
CM_ SG_ 1416 Balancing_temp_max_cmu_index "ID of the CMU containing the maximum balancing temperature";
CM_ SG_ 1416 Balancing_temp_min_cmu_index "ID of the CMU containing the minimum balancing temperature";
CM_ SG_ 1416 Cell_voltage_average_value "Average cell voltage measured";
CM_ SG_ 1417 Cell_voltage_maximum_value "Highest cell voltage measured";
CM_ SG_ 1417 Cell_voltage_minimum_value "Lowest cell voltage measured";
CM_ SG_ 1417 Cell_voltage_max_channel_index "ID of the CMU�s channel measuring the maximum cell voltage";
CM_ SG_ 1417 Cell_voltage_max_cmu_index "ID of the CMU containing the maximum cell voltage";
CM_ SG_ 1417 Cell_voltage_min_channel_index "ID of the CMU�s channel measuring the minimum cell voltage";
CM_ SG_ 1417 Cell_voltage_min_cmu_index "ID of the CMU containing the minimum cell voltage";
CM_ SG_ 1417 Cell_temp_maximum_value "Highest cell temperature measured";
CM_ SG_ 1417 Cell_temp_minimum_value "Lowest cell temperature measured";
CM_ SG_ 1417 Cell_temp_average_value "Average cell temperature measured";
CM_ SG_ 1417 Cell_temp_max_cmu_index "ID of the CMU�s channel measuring the maximum cell temperature";
CM_ SG_ 1417 Cell_temp_max_channel_index "ID of the CMU containing the maximum cell temperature";
CM_ SG_ 1417 Cell_temp_min_cmu_index "ID of the CMU�s channel measuring the minimum cell temperature";
CM_ SG_ 1417 Cell_temp_min_channel_index "ID of the CMU containing the minimum cell temperature";
CM_ SG_ 1417 Balancing_temp_maximum_value "Highest balancing temperature measured";
CM_ SG_ 1417 Balancing_temp_minimum_value "Lowest balancing temperature measured";
CM_ SG_ 1417 Balancing_temp_average_value "Average balancing temperature measured";
CM_ SG_ 1417 Balancing_temp_max_cmu_index "ID of the CMU containing the maximum balancing temperature";
CM_ SG_ 1417 Balancing_temp_min_cmu_index "ID of the CMU containing the minimum balancing temperature";
CM_ SG_ 1417 Cell_voltage_average_value "Average cell voltage measured";
CM_ SG_ 1418 Cell_voltage_maximum_value "Highest cell voltage measured";
CM_ SG_ 1418 Cell_voltage_minimum_value "Lowest cell voltage measured";
CM_ SG_ 1418 Cell_voltage_max_channel_index "ID of the CMU�s channel measuring the maximum cell voltage";
CM_ SG_ 1418 Cell_voltage_max_cmu_index "ID of the CMU containing the maximum cell voltage";
CM_ SG_ 1418 Cell_voltage_min_channel_index "ID of the CMU�s channel measuring the minimum cell voltage";
CM_ SG_ 1418 Cell_voltage_min_cmu_index "ID of the CMU containing the minimum cell voltage";
CM_ SG_ 1418 Cell_temp_maximum_value "Highest cell temperature measured";
CM_ SG_ 1418 Cell_temp_minimum_value "Lowest cell temperature measured";
CM_ SG_ 1418 Cell_temp_average_value "Average cell temperature measured";
CM_ SG_ 1418 Cell_temp_max_cmu_index "ID of the CMU�s channel measuring the maximum cell temperature";
CM_ SG_ 1418 Cell_temp_max_channel_index "ID of the CMU containing the maximum cell temperature";
CM_ SG_ 1418 Cell_temp_min_cmu_index "ID of the CMU�s channel measuring the minimum cell temperature";
CM_ SG_ 1418 Cell_temp_min_channel_index "ID of the CMU containing the minimum cell temperature";
CM_ SG_ 1418 Balancing_temp_maximum_value "Highest balancing temperature measured";
CM_ SG_ 1418 Balancing_temp_minimum_value "Lowest balancing temperature measured";
CM_ SG_ 1418 Balancing_temp_average_value "Average balancing temperature measured";
CM_ SG_ 1418 Balancing_temp_max_cmu_index "ID of the CMU containing the maximum balancing temperature";
CM_ SG_ 1418 Balancing_temp_min_cmu_index "ID of the CMU containing the minimum balancing temperature";
CM_ SG_ 1418 Cell_voltage_average_value "Average cell voltage measured";
CM_ SG_ 1419 Cell_voltage_maximum_value "Highest cell voltage measured";
CM_ SG_ 1419 Cell_voltage_minimum_value "Lowest cell voltage measured";
CM_ SG_ 1419 Cell_voltage_max_channel_index "ID of the CMU�s channel measuring the maximum cell voltage";
CM_ SG_ 1419 Cell_voltage_max_cmu_index "ID of the CMU containing the maximum cell voltage";
CM_ SG_ 1419 Cell_voltage_min_channel_index "ID of the CMU�s channel measuring the minimum cell voltage";
CM_ SG_ 1419 Cell_voltage_min_cmu_index "ID of the CMU containing the minimum cell voltage";
CM_ SG_ 1419 Cell_temp_maximum_value "Highest cell temperature measured";
CM_ SG_ 1419 Cell_temp_minimum_value "Lowest cell temperature measured";
CM_ SG_ 1419 Cell_temp_average_value "Average cell temperature measured";
CM_ SG_ 1419 Cell_temp_max_cmu_index "ID of the CMU�s channel measuring the maximum cell temperature";
CM_ SG_ 1419 Cell_temp_max_channel_index "ID of the CMU containing the maximum cell temperature";
CM_ SG_ 1419 Cell_temp_min_cmu_index "ID of the CMU�s channel measuring the minimum cell temperature";
CM_ SG_ 1419 Cell_temp_min_channel_index "ID of the CMU containing the minimum cell temperature";
CM_ SG_ 1419 Balancing_temp_maximum_value "Highest balancing temperature measured";
CM_ SG_ 1419 Balancing_temp_minimum_value "Lowest balancing temperature measured";
CM_ SG_ 1419 Balancing_temp_average_value "Average balancing temperature measured";
CM_ SG_ 1419 Balancing_temp_max_cmu_index "ID of the CMU containing the maximum balancing temperature";
CM_ SG_ 1419 Balancing_temp_min_cmu_index "ID of the CMU containing the minimum balancing temperature";
CM_ SG_ 1419 Cell_voltage_average_value "Average cell voltage measured";
CM_ SG_ 1420 Cell_voltage_maximum_value "Highest cell voltage measured";
CM_ SG_ 1420 Cell_voltage_minimum_value "Lowest cell voltage measured";
CM_ SG_ 1420 Cell_voltage_max_channel_index "ID of the CMU�s channel measuring the maximum cell voltage";
CM_ SG_ 1420 Cell_voltage_max_cmu_index "ID of the CMU containing the maximum cell voltage";
CM_ SG_ 1420 Cell_voltage_min_channel_index "ID of the CMU�s channel measuring the minimum cell voltage";
CM_ SG_ 1420 Cell_voltage_min_cmu_index "ID of the CMU containing the minimum cell voltage";
CM_ SG_ 1420 Cell_temp_maximum_value "Highest cell temperature measured";
CM_ SG_ 1420 Cell_temp_minimum_value "Lowest cell temperature measured";
CM_ SG_ 1420 Cell_temp_average_value "Average cell temperature measured";
CM_ SG_ 1420 Cell_temp_max_cmu_index "ID of the CMU�s channel measuring the maximum cell temperature";
CM_ SG_ 1420 Cell_temp_max_channel_index "ID of the CMU containing the maximum cell temperature";
CM_ SG_ 1420 Cell_temp_min_cmu_index "ID of the CMU�s channel measuring the minimum cell temperature";
CM_ SG_ 1420 Cell_temp_min_channel_index "ID of the CMU containing the minimum cell temperature";
CM_ SG_ 1420 Balancing_temp_maximum_value "Highest balancing temperature measured";
CM_ SG_ 1420 Balancing_temp_minimum_value "Lowest balancing temperature measured";
CM_ SG_ 1420 Balancing_temp_average_value "Average balancing temperature measured";
CM_ SG_ 1420 Balancing_temp_max_cmu_index "ID of the CMU containing the maximum balancing temperature";
CM_ SG_ 1420 Balancing_temp_min_cmu_index "ID of the CMU containing the minimum balancing temperature";
CM_ SG_ 1420 Cell_voltage_average_value "Average cell voltage measured";
CM_ SG_ 1421 Cell_voltage_maximum_value "Highest cell voltage measured";
CM_ SG_ 1421 Cell_voltage_minimum_value "Lowest cell voltage measured";
CM_ SG_ 1421 Cell_voltage_max_channel_index "ID of the CMU�s channel measuring the maximum cell voltage";
CM_ SG_ 1421 Cell_voltage_max_cmu_index "ID of the CMU containing the maximum cell voltage";
CM_ SG_ 1421 Cell_voltage_min_channel_index "ID of the CMU�s channel measuring the minimum cell voltage";
CM_ SG_ 1421 Cell_voltage_min_cmu_index "ID of the CMU containing the minimum cell voltage";
CM_ SG_ 1421 Cell_temp_maximum_value "Highest cell temperature measured";
CM_ SG_ 1421 Cell_temp_minimum_value "Lowest cell temperature measured";
CM_ SG_ 1421 Cell_temp_average_value "Average cell temperature measured";
CM_ SG_ 1421 Cell_temp_max_cmu_index "ID of the CMU�s channel measuring the maximum cell temperature";
CM_ SG_ 1421 Cell_temp_max_channel_index "ID of the CMU containing the maximum cell temperature";
CM_ SG_ 1421 Cell_temp_min_cmu_index "ID of the CMU�s channel measuring the minimum cell temperature";
CM_ SG_ 1421 Cell_temp_min_channel_index "ID of the CMU containing the minimum cell temperature";
CM_ SG_ 1421 Balancing_temp_maximum_value "Highest balancing temperature measured";
CM_ SG_ 1421 Balancing_temp_minimum_value "Lowest balancing temperature measured";
CM_ SG_ 1421 Balancing_temp_average_value "Average balancing temperature measured";
CM_ SG_ 1421 Balancing_temp_max_cmu_index "ID of the CMU containing the maximum balancing temperature";
CM_ SG_ 1421 Balancing_temp_min_cmu_index "ID of the CMU containing the minimum balancing temperature";
CM_ SG_ 1421 Cell_voltage_average_value "Average cell voltage measured";
CM_ SG_ 1422 Cell_voltage_maximum_value "Highest cell voltage measured";
CM_ SG_ 1422 Cell_voltage_minimum_value "Lowest cell voltage measured";
CM_ SG_ 1422 Cell_voltage_max_channel_index "ID of the CMU�s channel measuring the maximum cell voltage";
CM_ SG_ 1422 Cell_voltage_max_cmu_index "ID of the CMU containing the maximum cell voltage";
CM_ SG_ 1422 Cell_voltage_min_channel_index "ID of the CMU�s channel measuring the minimum cell voltage";
CM_ SG_ 1422 Cell_voltage_min_cmu_index "ID of the CMU containing the minimum cell voltage";
CM_ SG_ 1422 Cell_temp_maximum_value "Highest cell temperature measured";
CM_ SG_ 1422 Cell_temp_minimum_value "Lowest cell temperature measured";
CM_ SG_ 1422 Cell_temp_average_value "Average cell temperature measured";
CM_ SG_ 1422 Cell_temp_max_cmu_index "ID of the CMU�s channel measuring the maximum cell temperature";
CM_ SG_ 1422 Cell_temp_max_channel_index "ID of the CMU containing the maximum cell temperature";
CM_ SG_ 1422 Cell_temp_min_cmu_index "ID of the CMU�s channel measuring the minimum cell temperature";
CM_ SG_ 1422 Cell_temp_min_channel_index "ID of the CMU containing the minimum cell temperature";
CM_ SG_ 1422 Balancing_temp_maximum_value "Highest balancing temperature measured";
CM_ SG_ 1422 Balancing_temp_minimum_value "Lowest balancing temperature measured";
CM_ SG_ 1422 Balancing_temp_average_value "Average balancing temperature measured";
CM_ SG_ 1422 Balancing_temp_max_cmu_index "ID of the CMU containing the maximum balancing temperature";
CM_ SG_ 1422 Balancing_temp_min_cmu_index "ID of the CMU containing the minimum balancing temperature";
CM_ SG_ 1422 Cell_voltage_average_value "Average cell voltage measured";
CM_ SG_ 1423 Cell_voltage_maximum_value "Highest cell voltage measured";
CM_ SG_ 1423 Cell_voltage_minimum_value "Lowest cell voltage measured";
CM_ SG_ 1423 Cell_voltage_max_channel_index "ID of the CMU�s channel measuring the maximum cell voltage";
CM_ SG_ 1423 Cell_voltage_max_cmu_index "ID of the CMU containing the maximum cell voltage";
CM_ SG_ 1423 Cell_voltage_min_channel_index "ID of the CMU�s channel measuring the minimum cell voltage";
CM_ SG_ 1423 Cell_voltage_min_cmu_index "ID of the CMU containing the minimum cell voltage";
CM_ SG_ 1423 Cell_temp_maximum_value "Highest cell temperature measured";
CM_ SG_ 1423 Cell_temp_minimum_value "Lowest cell temperature measured";
CM_ SG_ 1423 Cell_temp_average_value "Average cell temperature measured";
CM_ SG_ 1423 Cell_temp_max_cmu_index "ID of the CMU�s channel measuring the maximum cell temperature";
CM_ SG_ 1423 Cell_temp_max_channel_index "ID of the CMU containing the maximum cell temperature";
CM_ SG_ 1423 Cell_temp_min_cmu_index "ID of the CMU�s channel measuring the minimum cell temperature";
CM_ SG_ 1423 Cell_temp_min_channel_index "ID of the CMU containing the minimum cell temperature";
CM_ SG_ 1423 Balancing_temp_maximum_value "Highest balancing temperature measured";
CM_ SG_ 1423 Balancing_temp_minimum_value "Lowest balancing temperature measured";
CM_ SG_ 1423 Balancing_temp_average_value "Average balancing temperature measured";
CM_ SG_ 1423 Balancing_temp_max_cmu_index "ID of the CMU containing the maximum balancing temperature";
CM_ SG_ 1423 Balancing_temp_min_cmu_index "ID of the CMU containing the minimum balancing temperature";
CM_ SG_ 1423 Cell_voltage_average_value "Average cell voltage measured";
CM_ SG_ 1440 IMD_resistance_value "Isolation resistance measured by the IMD";
CM_ SG_ 1440 Voltage_sensor_battery_voltage "Voltage measured between the negative reference of the battery and the positive terminal";
CM_ SG_ 1440 Voltage_sensor_link_voltage "Voltage measured after the main power relays and the precharge circuit";
CM_ SG_ 1440 Voltage_sensor_fuse_voltage "Voltage measured after the fuses";
CM_ SG_ 1440 Control_unit_temperature "Temperature of the control unit";
CM_ SG_ 1440 Control_unit_supply_voltage "Voltage of the control unit";
CM_ SG_ 1440 Outputs_supply_voltage "Voltage measurement of the external outputs supply";
CM_ SG_ 1440 External_temperature_1 "External temperature 1";
CM_ SG_ 1440 External_temperature_2 "External temperature 2";
CM_ SG_ 1440 External_temperature_3 "External temperature 3";
CM_ SG_ 1440 External_temperature_4 "External temperature 4";
CM_ SG_ 1441 IMD_resistance_value "Isolation resistance measured by the IMD";
CM_ SG_ 1441 Voltage_sensor_battery_voltage "Voltage measured between the negative reference of the battery and the positive terminal";
CM_ SG_ 1441 Voltage_sensor_link_voltage "Voltage measured after the main power relays and the precharge circuit";
CM_ SG_ 1441 Voltage_sensor_fuse_voltage "Voltage measured after the fuses";
CM_ SG_ 1441 Control_unit_temperature "Temperature of the control unit";
CM_ SG_ 1441 Control_unit_supply_voltage "Voltage of the control unit";
CM_ SG_ 1441 Outputs_supply_voltage "Voltage measurement of the external outputs supply";
CM_ SG_ 1441 External_temperature_1 "External temperature 1";
CM_ SG_ 1441 External_temperature_2 "External temperature 2";
CM_ SG_ 1441 External_temperature_3 "External temperature 3";
CM_ SG_ 1441 External_temperature_4 "External temperature 4";
CM_ SG_ 1442 IMD_resistance_value "Isolation resistance measured by the IMD";
CM_ SG_ 1442 Voltage_sensor_battery_voltage "Voltage measured between the negative reference of the battery and the positive terminal";
CM_ SG_ 1442 Voltage_sensor_link_voltage "Voltage measured after the main power relays and the precharge circuit";
CM_ SG_ 1442 Voltage_sensor_fuse_voltage "Voltage measured after the fuses";
CM_ SG_ 1442 Control_unit_temperature "Temperature of the control unit";
CM_ SG_ 1442 Control_unit_supply_voltage "Voltage of the control unit";
CM_ SG_ 1442 Outputs_supply_voltage "Voltage measurement of the external outputs supply";
CM_ SG_ 1442 External_temperature_1 "External temperature 1";
CM_ SG_ 1442 External_temperature_2 "External temperature 2";
CM_ SG_ 1442 External_temperature_3 "External temperature 3";
CM_ SG_ 1442 External_temperature_4 "External temperature 4";
CM_ SG_ 1443 IMD_resistance_value "Isolation resistance measured by the IMD";
CM_ SG_ 1443 Voltage_sensor_battery_voltage "Voltage measured between the negative reference of the battery and the positive terminal";
CM_ SG_ 1443 Voltage_sensor_link_voltage "Voltage measured after the main power relays and the precharge circuit";
CM_ SG_ 1443 Voltage_sensor_fuse_voltage "Voltage measured after the fuses";
CM_ SG_ 1443 Control_unit_temperature "Temperature of the control unit";
CM_ SG_ 1443 Control_unit_supply_voltage "Voltage of the control unit";
CM_ SG_ 1443 Outputs_supply_voltage "Voltage measurement of the external outputs supply";
CM_ SG_ 1443 External_temperature_1 "External temperature 1";
CM_ SG_ 1443 External_temperature_2 "External temperature 2";
CM_ SG_ 1443 External_temperature_3 "External temperature 3";
CM_ SG_ 1443 External_temperature_4 "External temperature 4";
CM_ SG_ 1444 IMD_resistance_value "Isolation resistance measured by the IMD";
CM_ SG_ 1444 Voltage_sensor_battery_voltage "Voltage measured between the negative reference of the battery and the positive terminal";
CM_ SG_ 1444 Voltage_sensor_link_voltage "Voltage measured after the main power relays and the precharge circuit";
CM_ SG_ 1444 Voltage_sensor_fuse_voltage "Voltage measured after the fuses";
CM_ SG_ 1444 Control_unit_temperature "Temperature of the control unit";
CM_ SG_ 1444 Control_unit_supply_voltage "Voltage of the control unit";
CM_ SG_ 1444 Outputs_supply_voltage "Voltage measurement of the external outputs supply";
CM_ SG_ 1444 External_temperature_1 "External temperature 1";
CM_ SG_ 1444 External_temperature_2 "External temperature 2";
CM_ SG_ 1444 External_temperature_3 "External temperature 3";
CM_ SG_ 1444 External_temperature_4 "External temperature 4";
CM_ SG_ 1445 IMD_resistance_value "Isolation resistance measured by the IMD";
CM_ SG_ 1445 Voltage_sensor_battery_voltage "Voltage measured between the negative reference of the battery and the positive terminal";
CM_ SG_ 1445 Voltage_sensor_link_voltage "Voltage measured after the main power relays and the precharge circuit";
CM_ SG_ 1445 Voltage_sensor_fuse_voltage "Voltage measured after the fuses";
CM_ SG_ 1445 Control_unit_temperature "Temperature of the control unit";
CM_ SG_ 1445 Control_unit_supply_voltage "Voltage of the control unit";
CM_ SG_ 1445 Outputs_supply_voltage "Voltage measurement of the external outputs supply";
CM_ SG_ 1445 External_temperature_1 "External temperature 1";
CM_ SG_ 1445 External_temperature_2 "External temperature 2";
CM_ SG_ 1445 External_temperature_3 "External temperature 3";
CM_ SG_ 1445 External_temperature_4 "External temperature 4";
CM_ SG_ 1446 IMD_resistance_value "Isolation resistance measured by the IMD";
CM_ SG_ 1446 Voltage_sensor_battery_voltage "Voltage measured between the negative reference of the battery and the positive terminal";
CM_ SG_ 1446 Voltage_sensor_link_voltage "Voltage measured after the main power relays and the precharge circuit";
CM_ SG_ 1446 Voltage_sensor_fuse_voltage "Voltage measured after the fuses";
CM_ SG_ 1446 Control_unit_temperature "Temperature of the control unit";
CM_ SG_ 1446 Control_unit_supply_voltage "Voltage of the control unit";
CM_ SG_ 1446 Outputs_supply_voltage "Voltage measurement of the external outputs supply";
CM_ SG_ 1446 External_temperature_1 "External temperature 1";
CM_ SG_ 1446 External_temperature_2 "External temperature 2";
CM_ SG_ 1446 External_temperature_3 "External temperature 3";
CM_ SG_ 1446 External_temperature_4 "External temperature 4";
CM_ SG_ 1447 IMD_resistance_value "Isolation resistance measured by the IMD";
CM_ SG_ 1447 Voltage_sensor_battery_voltage "Voltage measured between the negative reference of the battery and the positive terminal";
CM_ SG_ 1447 Voltage_sensor_link_voltage "Voltage measured after the main power relays and the precharge circuit";
CM_ SG_ 1447 Voltage_sensor_fuse_voltage "Voltage measured after the fuses";
CM_ SG_ 1447 Control_unit_temperature "Temperature of the control unit";
CM_ SG_ 1447 Control_unit_supply_voltage "Voltage of the control unit";
CM_ SG_ 1447 Outputs_supply_voltage "Voltage measurement of the external outputs supply";
CM_ SG_ 1447 External_temperature_1 "External temperature 1";
CM_ SG_ 1447 External_temperature_2 "External temperature 2";
CM_ SG_ 1447 External_temperature_3 "External temperature 3";
CM_ SG_ 1447 External_temperature_4 "External temperature 4";
CM_ SG_ 1448 IMD_resistance_value "Isolation resistance measured by the IMD";
CM_ SG_ 1448 Voltage_sensor_battery_voltage "Voltage measured between the negative reference of the battery and the positive terminal";
CM_ SG_ 1448 Voltage_sensor_link_voltage "Voltage measured after the main power relays and the precharge circuit";
CM_ SG_ 1448 Voltage_sensor_fuse_voltage "Voltage measured after the fuses";
CM_ SG_ 1448 Control_unit_temperature "Temperature of the control unit";
CM_ SG_ 1448 Control_unit_supply_voltage "Voltage of the control unit";
CM_ SG_ 1448 Outputs_supply_voltage "Voltage measurement of the external outputs supply";
CM_ SG_ 1448 External_temperature_1 "External temperature 1";
CM_ SG_ 1448 External_temperature_2 "External temperature 2";
CM_ SG_ 1448 External_temperature_3 "External temperature 3";
CM_ SG_ 1448 External_temperature_4 "External temperature 4";
CM_ SG_ 1449 IMD_resistance_value "Isolation resistance measured by the IMD";
CM_ SG_ 1449 Voltage_sensor_battery_voltage "Voltage measured between the negative reference of the battery and the positive terminal";
CM_ SG_ 1449 Voltage_sensor_link_voltage "Voltage measured after the main power relays and the precharge circuit";
CM_ SG_ 1449 Voltage_sensor_fuse_voltage "Voltage measured after the fuses";
CM_ SG_ 1449 Control_unit_temperature "Temperature of the control unit";
CM_ SG_ 1449 Control_unit_supply_voltage "Voltage of the control unit";
CM_ SG_ 1449 Outputs_supply_voltage "Voltage measurement of the external outputs supply";
CM_ SG_ 1449 External_temperature_1 "External temperature 1";
CM_ SG_ 1449 External_temperature_2 "External temperature 2";
CM_ SG_ 1449 External_temperature_3 "External temperature 3";
CM_ SG_ 1449 External_temperature_4 "External temperature 4";
CM_ SG_ 1450 IMD_resistance_value "Isolation resistance measured by the IMD";
CM_ SG_ 1450 Voltage_sensor_battery_voltage "Voltage measured between the negative reference of the battery and the positive terminal";
CM_ SG_ 1450 Voltage_sensor_link_voltage "Voltage measured after the main power relays and the precharge circuit";
CM_ SG_ 1450 Voltage_sensor_fuse_voltage "Voltage measured after the fuses";
CM_ SG_ 1450 Control_unit_temperature "Temperature of the control unit";
CM_ SG_ 1450 Control_unit_supply_voltage "Voltage of the control unit";
CM_ SG_ 1450 Outputs_supply_voltage "Voltage measurement of the external outputs supply";
CM_ SG_ 1450 External_temperature_1 "External temperature 1";
CM_ SG_ 1450 External_temperature_2 "External temperature 2";
CM_ SG_ 1450 External_temperature_3 "External temperature 3";
CM_ SG_ 1450 External_temperature_4 "External temperature 4";
CM_ SG_ 1451 IMD_resistance_value "Isolation resistance measured by the IMD";
CM_ SG_ 1451 Voltage_sensor_battery_voltage "Voltage measured between the negative reference of the battery and the positive terminal";
CM_ SG_ 1451 Voltage_sensor_link_voltage "Voltage measured after the main power relays and the precharge circuit";
CM_ SG_ 1451 Voltage_sensor_fuse_voltage "Voltage measured after the fuses";
CM_ SG_ 1451 Control_unit_temperature "Temperature of the control unit";
CM_ SG_ 1451 Control_unit_supply_voltage "Voltage of the control unit";
CM_ SG_ 1451 Outputs_supply_voltage "Voltage measurement of the external outputs supply";
CM_ SG_ 1451 External_temperature_1 "External temperature 1";
CM_ SG_ 1451 External_temperature_2 "External temperature 2";
CM_ SG_ 1451 External_temperature_3 "External temperature 3";
CM_ SG_ 1451 External_temperature_4 "External temperature 4";
CM_ SG_ 1452 IMD_resistance_value "Isolation resistance measured by the IMD";
CM_ SG_ 1452 Voltage_sensor_battery_voltage "Voltage measured between the negative reference of the battery and the positive terminal";
CM_ SG_ 1452 Voltage_sensor_link_voltage "Voltage measured after the main power relays and the precharge circuit";
CM_ SG_ 1452 Voltage_sensor_fuse_voltage "Voltage measured after the fuses";
CM_ SG_ 1452 Control_unit_temperature "Temperature of the control unit";
CM_ SG_ 1452 Control_unit_supply_voltage "Voltage of the control unit";
CM_ SG_ 1452 Outputs_supply_voltage "Voltage measurement of the external outputs supply";
CM_ SG_ 1452 External_temperature_1 "External temperature 1";
CM_ SG_ 1452 External_temperature_2 "External temperature 2";
CM_ SG_ 1452 External_temperature_3 "External temperature 3";
CM_ SG_ 1452 External_temperature_4 "External temperature 4";
CM_ SG_ 1453 IMD_resistance_value "Isolation resistance measured by the IMD";
CM_ SG_ 1453 Voltage_sensor_battery_voltage "Voltage measured between the negative reference of the battery and the positive terminal";
CM_ SG_ 1453 Voltage_sensor_link_voltage "Voltage measured after the main power relays and the precharge circuit";
CM_ SG_ 1453 Voltage_sensor_fuse_voltage "Voltage measured after the fuses";
CM_ SG_ 1453 Control_unit_temperature "Temperature of the control unit";
CM_ SG_ 1453 Control_unit_supply_voltage "Voltage of the control unit";
CM_ SG_ 1453 Outputs_supply_voltage "Voltage measurement of the external outputs supply";
CM_ SG_ 1453 External_temperature_1 "External temperature 1";
CM_ SG_ 1453 External_temperature_2 "External temperature 2";
CM_ SG_ 1453 External_temperature_3 "External temperature 3";
CM_ SG_ 1453 External_temperature_4 "External temperature 4";
CM_ SG_ 1454 IMD_resistance_value "Isolation resistance measured by the IMD";
CM_ SG_ 1454 Voltage_sensor_battery_voltage "Voltage measured between the negative reference of the battery and the positive terminal";
CM_ SG_ 1454 Voltage_sensor_link_voltage "Voltage measured after the main power relays and the precharge circuit";
CM_ SG_ 1454 Voltage_sensor_fuse_voltage "Voltage measured after the fuses";
CM_ SG_ 1454 Control_unit_temperature "Temperature of the control unit";
CM_ SG_ 1454 Control_unit_supply_voltage "Voltage of the control unit";
CM_ SG_ 1454 Outputs_supply_voltage "Voltage measurement of the external outputs supply";
CM_ SG_ 1454 External_temperature_1 "External temperature 1";
CM_ SG_ 1454 External_temperature_2 "External temperature 2";
CM_ SG_ 1454 External_temperature_3 "External temperature 3";
CM_ SG_ 1454 External_temperature_4 "External temperature 4";
CM_ SG_ 1455 IMD_resistance_value "Isolation resistance measured by the IMD";
CM_ SG_ 1455 Voltage_sensor_battery_voltage "Voltage measured between the negative reference of the battery and the positive terminal";
CM_ SG_ 1455 Voltage_sensor_link_voltage "Voltage measured after the main power relays and the precharge circuit";
CM_ SG_ 1455 Voltage_sensor_fuse_voltage "Voltage measured after the fuses";
CM_ SG_ 1455 Control_unit_temperature "Temperature of the control unit";
CM_ SG_ 1455 Control_unit_supply_voltage "Voltage of the control unit";
CM_ SG_ 1455 Outputs_supply_voltage "Voltage measurement of the external outputs supply";
CM_ SG_ 1455 External_temperature_1 "External temperature 1";
CM_ SG_ 1455 External_temperature_2 "External temperature 2";
CM_ SG_ 1455 External_temperature_3 "External temperature 3";
CM_ SG_ 1455 External_temperature_4 "External temperature 4";
CM_ SG_ 1472 State_of_Charge "BMU state of charge (SoC)";
CM_ SG_ 1472 State_of_Health "BMU state of health (SoH)";
CM_ SG_ 1472 Number_balancing_cells "Number of cells currently balancing.";
CM_ SG_ 1473 State_of_Charge "BMU state of charge (SoC)";
CM_ SG_ 1473 State_of_Health "BMU state of health (SoH)";
CM_ SG_ 1473 Number_balancing_cells "Number of cells currently balancing.";
CM_ SG_ 1474 State_of_Charge "BMU state of charge (SoC)";
CM_ SG_ 1474 State_of_Health "BMU state of health (SoH)";
CM_ SG_ 1474 Number_balancing_cells "Number of cells currently balancing.";
CM_ SG_ 1475 State_of_Charge "BMU state of charge (SoC)";
CM_ SG_ 1475 State_of_Health "BMU state of health (SoH)";
CM_ SG_ 1475 Number_balancing_cells "Number of cells currently balancing.";
CM_ SG_ 1476 State_of_Charge "BMU state of charge (SoC)";
CM_ SG_ 1476 State_of_Health "BMU state of health (SoH)";
CM_ SG_ 1476 Number_balancing_cells "Number of cells currently balancing.";
CM_ SG_ 1477 State_of_Charge "BMU state of charge (SoC)";
CM_ SG_ 1477 State_of_Health "BMU state of health (SoH)";
CM_ SG_ 1477 Number_balancing_cells "Number of cells currently balancing.";
CM_ SG_ 1478 State_of_Charge "BMU state of charge (SoC)";
CM_ SG_ 1478 State_of_Health "BMU state of health (SoH)";
CM_ SG_ 1478 Number_balancing_cells "Number of cells currently balancing.";
CM_ SG_ 1479 State_of_Charge "BMU state of charge (SoC)";
CM_ SG_ 1479 State_of_Health "BMU state of health (SoH)";
CM_ SG_ 1479 Number_balancing_cells "Number of cells currently balancing.";
CM_ SG_ 1480 State_of_Charge "BMU state of charge (SoC)";
CM_ SG_ 1480 State_of_Health "BMU state of health (SoH)";
CM_ SG_ 1480 Number_balancing_cells "Number of cells currently balancing.";
CM_ SG_ 1481 State_of_Charge "BMU state of charge (SoC)";
CM_ SG_ 1481 State_of_Health "BMU state of health (SoH)";
CM_ SG_ 1481 Number_balancing_cells "Number of cells currently balancing.";
CM_ SG_ 1482 State_of_Charge "BMU state of charge (SoC)";
CM_ SG_ 1482 State_of_Health "BMU state of health (SoH)";
CM_ SG_ 1482 Number_balancing_cells "Number of cells currently balancing.";
CM_ SG_ 1483 State_of_Charge "BMU state of charge (SoC)";
CM_ SG_ 1483 State_of_Health "BMU state of health (SoH)";
CM_ SG_ 1483 Number_balancing_cells "Number of cells currently balancing.";
VAL_ 1440 IMD_status 0 "IMD_DISABLED" 1 "IMD_OFF" 2 "IMD_SHORTCIRCUIT_VCC" 3 "IMD_OK" 4 "IMD_UNDERVOLTAGE" 5 "IMD_FAST_DETECTION_OK" 6 "IMD_FAST_DETECTION_FAIL" 7 "IMD_HW_ERROR" 8 "IMD_GND_ERROR" 9 "IMD_INSULATION_ERROR" 10 "IMD_INSULATION_WARNING" 11 "IMD_UNKNOWN_REPORTED_STATUS" 12 "IMD_UNQUALIFIED_STATUS" 13 "IMD_HV_CONNECTION_ERROR" ;
VAL_ 1440 Voltage_sensor_status 0 "VOLTAGE_SENSOR_STATUS_DISABLED" 1 "VOLTAGE_SENSOR_STATUS_TIMEOUT" 2 "VOLTAGE_SENSOR_STATUS_ERROR" 3 "VOLTAGE_SENSOR_STATUS_OK" 4 "VOLTAGE_SENSOR_STATUS_DC_LINK_MISMATCH" 5 "VOLTAGE_SENSOR_STATUS_BATTERY_PACK_MISMATCH" 6 "VOLTAGE_SENSOR_STATUS_FUSE_MISMATCH" ;
VAL_ 1441 IMD_status 0 "IMD_DISABLED" 1 "IMD_OFF" 2 "IMD_SHORTCIRCUIT_VCC" 3 "IMD_OK" 4 "IMD_UNDERVOLTAGE" 5 "IMD_FAST_DETECTION_OK" 6 "IMD_FAST_DETECTION_FAIL" 7 "IMD_HW_ERROR" 8 "IMD_GND_ERROR" 9 "IMD_INSULATION_ERROR" 10 "IMD_INSULATION_WARNING" 11 "IMD_UNKNOWN_REPORTED_STATUS" 12 "IMD_UNQUALIFIED_STATUS" 13 "IMD_HV_CONNECTION_ERROR" ;
VAL_ 1441 Voltage_sensor_status 0 "VOLTAGE_SENSOR_STATUS_DISABLED" 1 "VOLTAGE_SENSOR_STATUS_TIMEOUT" 2 "VOLTAGE_SENSOR_STATUS_ERROR" 3 "VOLTAGE_SENSOR_STATUS_OK" 4 "VOLTAGE_SENSOR_STATUS_DC_LINK_MISMATCH" 5 "VOLTAGE_SENSOR_STATUS_BATTERY_PACK_MISMATCH" 6 "VOLTAGE_SENSOR_STATUS_FUSE_MISMATCH" ;
VAL_ 1442 IMD_status 0 "IMD_DISABLED" 1 "IMD_OFF" 2 "IMD_SHORTCIRCUIT_VCC" 3 "IMD_OK" 4 "IMD_UNDERVOLTAGE" 5 "IMD_FAST_DETECTION_OK" 6 "IMD_FAST_DETECTION_FAIL" 7 "IMD_HW_ERROR" 8 "IMD_GND_ERROR" 9 "IMD_INSULATION_ERROR" 10 "IMD_INSULATION_WARNING" 11 "IMD_UNKNOWN_REPORTED_STATUS" 12 "IMD_UNQUALIFIED_STATUS" 13 "IMD_HV_CONNECTION_ERROR" ;
VAL_ 1442 Voltage_sensor_status 0 "VOLTAGE_SENSOR_STATUS_DISABLED" 1 "VOLTAGE_SENSOR_STATUS_TIMEOUT" 2 "VOLTAGE_SENSOR_STATUS_ERROR" 3 "VOLTAGE_SENSOR_STATUS_OK" 4 "VOLTAGE_SENSOR_STATUS_DC_LINK_MISMATCH" 5 "VOLTAGE_SENSOR_STATUS_BATTERY_PACK_MISMATCH" 6 "VOLTAGE_SENSOR_STATUS_FUSE_MISMATCH" ;
VAL_ 1443 IMD_status 0 "IMD_DISABLED" 1 "IMD_OFF" 2 "IMD_SHORTCIRCUIT_VCC" 3 "IMD_OK" 4 "IMD_UNDERVOLTAGE" 5 "IMD_FAST_DETECTION_OK" 6 "IMD_FAST_DETECTION_FAIL" 7 "IMD_HW_ERROR" 8 "IMD_GND_ERROR" 9 "IMD_INSULATION_ERROR" 10 "IMD_INSULATION_WARNING" 11 "IMD_UNKNOWN_REPORTED_STATUS" 12 "IMD_UNQUALIFIED_STATUS" 13 "IMD_HV_CONNECTION_ERROR" ;
VAL_ 1443 Voltage_sensor_status 0 "VOLTAGE_SENSOR_STATUS_DISABLED" 1 "VOLTAGE_SENSOR_STATUS_TIMEOUT" 2 "VOLTAGE_SENSOR_STATUS_ERROR" 3 "VOLTAGE_SENSOR_STATUS_OK" 4 "VOLTAGE_SENSOR_STATUS_DC_LINK_MISMATCH" 5 "VOLTAGE_SENSOR_STATUS_BATTERY_PACK_MISMATCH" 6 "VOLTAGE_SENSOR_STATUS_FUSE_MISMATCH" ;
VAL_ 1444 IMD_status 0 "IMD_DISABLED" 1 "IMD_OFF" 2 "IMD_SHORTCIRCUIT_VCC" 3 "IMD_OK" 4 "IMD_UNDERVOLTAGE" 5 "IMD_FAST_DETECTION_OK" 6 "IMD_FAST_DETECTION_FAIL" 7 "IMD_HW_ERROR" 8 "IMD_GND_ERROR" 9 "IMD_INSULATION_ERROR" 10 "IMD_INSULATION_WARNING" 11 "IMD_UNKNOWN_REPORTED_STATUS" 12 "IMD_UNQUALIFIED_STATUS" 13 "IMD_HV_CONNECTION_ERROR" ;
VAL_ 1444 Voltage_sensor_status 0 "VOLTAGE_SENSOR_STATUS_DISABLED" 1 "VOLTAGE_SENSOR_STATUS_TIMEOUT" 2 "VOLTAGE_SENSOR_STATUS_ERROR" 3 "VOLTAGE_SENSOR_STATUS_OK" 4 "VOLTAGE_SENSOR_STATUS_DC_LINK_MISMATCH" 5 "VOLTAGE_SENSOR_STATUS_BATTERY_PACK_MISMATCH" 6 "VOLTAGE_SENSOR_STATUS_FUSE_MISMATCH" ;
VAL_ 1445 IMD_status 0 "IMD_DISABLED" 1 "IMD_OFF" 2 "IMD_SHORTCIRCUIT_VCC" 3 "IMD_OK" 4 "IMD_UNDERVOLTAGE" 5 "IMD_FAST_DETECTION_OK" 6 "IMD_FAST_DETECTION_FAIL" 7 "IMD_HW_ERROR" 8 "IMD_GND_ERROR" 9 "IMD_INSULATION_ERROR" 10 "IMD_INSULATION_WARNING" 11 "IMD_UNKNOWN_REPORTED_STATUS" 12 "IMD_UNQUALIFIED_STATUS" 13 "IMD_HV_CONNECTION_ERROR" ;
VAL_ 1445 Voltage_sensor_status 0 "VOLTAGE_SENSOR_STATUS_DISABLED" 1 "VOLTAGE_SENSOR_STATUS_TIMEOUT" 2 "VOLTAGE_SENSOR_STATUS_ERROR" 3 "VOLTAGE_SENSOR_STATUS_OK" 4 "VOLTAGE_SENSOR_STATUS_DC_LINK_MISMATCH" 5 "VOLTAGE_SENSOR_STATUS_BATTERY_PACK_MISMATCH" 6 "VOLTAGE_SENSOR_STATUS_FUSE_MISMATCH" ;
VAL_ 1446 IMD_status 0 "IMD_DISABLED" 1 "IMD_OFF" 2 "IMD_SHORTCIRCUIT_VCC" 3 "IMD_OK" 4 "IMD_UNDERVOLTAGE" 5 "IMD_FAST_DETECTION_OK" 6 "IMD_FAST_DETECTION_FAIL" 7 "IMD_HW_ERROR" 8 "IMD_GND_ERROR" 9 "IMD_INSULATION_ERROR" 10 "IMD_INSULATION_WARNING" 11 "IMD_UNKNOWN_REPORTED_STATUS" 12 "IMD_UNQUALIFIED_STATUS" 13 "IMD_HV_CONNECTION_ERROR" ;
VAL_ 1446 Voltage_sensor_status 0 "VOLTAGE_SENSOR_STATUS_DISABLED" 1 "VOLTAGE_SENSOR_STATUS_TIMEOUT" 2 "VOLTAGE_SENSOR_STATUS_ERROR" 3 "VOLTAGE_SENSOR_STATUS_OK" 4 "VOLTAGE_SENSOR_STATUS_DC_LINK_MISMATCH" 5 "VOLTAGE_SENSOR_STATUS_BATTERY_PACK_MISMATCH" 6 "VOLTAGE_SENSOR_STATUS_FUSE_MISMATCH" ;
VAL_ 1447 IMD_status 0 "IMD_DISABLED" 1 "IMD_OFF" 2 "IMD_SHORTCIRCUIT_VCC" 3 "IMD_OK" 4 "IMD_UNDERVOLTAGE" 5 "IMD_FAST_DETECTION_OK" 6 "IMD_FAST_DETECTION_FAIL" 7 "IMD_HW_ERROR" 8 "IMD_GND_ERROR" 9 "IMD_INSULATION_ERROR" 10 "IMD_INSULATION_WARNING" 11 "IMD_UNKNOWN_REPORTED_STATUS" 12 "IMD_UNQUALIFIED_STATUS" 13 "IMD_HV_CONNECTION_ERROR" ;
VAL_ 1447 Voltage_sensor_status 0 "VOLTAGE_SENSOR_STATUS_DISABLED" 1 "VOLTAGE_SENSOR_STATUS_TIMEOUT" 2 "VOLTAGE_SENSOR_STATUS_ERROR" 3 "VOLTAGE_SENSOR_STATUS_OK" 4 "VOLTAGE_SENSOR_STATUS_DC_LINK_MISMATCH" 5 "VOLTAGE_SENSOR_STATUS_BATTERY_PACK_MISMATCH" 6 "VOLTAGE_SENSOR_STATUS_FUSE_MISMATCH" ;
VAL_ 1448 IMD_status 0 "IMD_DISABLED" 1 "IMD_OFF" 2 "IMD_SHORTCIRCUIT_VCC" 3 "IMD_OK" 4 "IMD_UNDERVOLTAGE" 5 "IMD_FAST_DETECTION_OK" 6 "IMD_FAST_DETECTION_FAIL" 7 "IMD_HW_ERROR" 8 "IMD_GND_ERROR" 9 "IMD_INSULATION_ERROR" 10 "IMD_INSULATION_WARNING" 11 "IMD_UNKNOWN_REPORTED_STATUS" 12 "IMD_UNQUALIFIED_STATUS" 13 "IMD_HV_CONNECTION_ERROR" ;
VAL_ 1448 Voltage_sensor_status 0 "VOLTAGE_SENSOR_STATUS_DISABLED" 1 "VOLTAGE_SENSOR_STATUS_TIMEOUT" 2 "VOLTAGE_SENSOR_STATUS_ERROR" 3 "VOLTAGE_SENSOR_STATUS_OK" 4 "VOLTAGE_SENSOR_STATUS_DC_LINK_MISMATCH" 5 "VOLTAGE_SENSOR_STATUS_BATTERY_PACK_MISMATCH" 6 "VOLTAGE_SENSOR_STATUS_FUSE_MISMATCH" ;
VAL_ 1449 IMD_status 0 "IMD_DISABLED" 1 "IMD_OFF" 2 "IMD_SHORTCIRCUIT_VCC" 3 "IMD_OK" 4 "IMD_UNDERVOLTAGE" 5 "IMD_FAST_DETECTION_OK" 6 "IMD_FAST_DETECTION_FAIL" 7 "IMD_HW_ERROR" 8 "IMD_GND_ERROR" 9 "IMD_INSULATION_ERROR" 10 "IMD_INSULATION_WARNING" 11 "IMD_UNKNOWN_REPORTED_STATUS" 12 "IMD_UNQUALIFIED_STATUS" 13 "IMD_HV_CONNECTION_ERROR" ;
VAL_ 1449 Voltage_sensor_status 0 "VOLTAGE_SENSOR_STATUS_DISABLED" 1 "VOLTAGE_SENSOR_STATUS_TIMEOUT" 2 "VOLTAGE_SENSOR_STATUS_ERROR" 3 "VOLTAGE_SENSOR_STATUS_OK" 4 "VOLTAGE_SENSOR_STATUS_DC_LINK_MISMATCH" 5 "VOLTAGE_SENSOR_STATUS_BATTERY_PACK_MISMATCH" 6 "VOLTAGE_SENSOR_STATUS_FUSE_MISMATCH" ;
VAL_ 1450 IMD_status 0 "IMD_DISABLED" 1 "IMD_OFF" 2 "IMD_SHORTCIRCUIT_VCC" 3 "IMD_OK" 4 "IMD_UNDERVOLTAGE" 5 "IMD_FAST_DETECTION_OK" 6 "IMD_FAST_DETECTION_FAIL" 7 "IMD_HW_ERROR" 8 "IMD_GND_ERROR" 9 "IMD_INSULATION_ERROR" 10 "IMD_INSULATION_WARNING" 11 "IMD_UNKNOWN_REPORTED_STATUS" 12 "IMD_UNQUALIFIED_STATUS" 13 "IMD_HV_CONNECTION_ERROR" ;
VAL_ 1450 Voltage_sensor_status 0 "VOLTAGE_SENSOR_STATUS_DISABLED" 1 "VOLTAGE_SENSOR_STATUS_TIMEOUT" 2 "VOLTAGE_SENSOR_STATUS_ERROR" 3 "VOLTAGE_SENSOR_STATUS_OK" 4 "VOLTAGE_SENSOR_STATUS_DC_LINK_MISMATCH" 5 "VOLTAGE_SENSOR_STATUS_BATTERY_PACK_MISMATCH" 6 "VOLTAGE_SENSOR_STATUS_FUSE_MISMATCH" ;
VAL_ 1451 IMD_status 0 "IMD_DISABLED" 1 "IMD_OFF" 2 "IMD_SHORTCIRCUIT_VCC" 3 "IMD_OK" 4 "IMD_UNDERVOLTAGE" 5 "IMD_FAST_DETECTION_OK" 6 "IMD_FAST_DETECTION_FAIL" 7 "IMD_HW_ERROR" 8 "IMD_GND_ERROR" 9 "IMD_INSULATION_ERROR" 10 "IMD_INSULATION_WARNING" 11 "IMD_UNKNOWN_REPORTED_STATUS" 12 "IMD_UNQUALIFIED_STATUS" 13 "IMD_HV_CONNECTION_ERROR" ;
VAL_ 1451 Voltage_sensor_status 0 "VOLTAGE_SENSOR_STATUS_DISABLED" 1 "VOLTAGE_SENSOR_STATUS_TIMEOUT" 2 "VOLTAGE_SENSOR_STATUS_ERROR" 3 "VOLTAGE_SENSOR_STATUS_OK" 4 "VOLTAGE_SENSOR_STATUS_DC_LINK_MISMATCH" 5 "VOLTAGE_SENSOR_STATUS_BATTERY_PACK_MISMATCH" 6 "VOLTAGE_SENSOR_STATUS_FUSE_MISMATCH" ;
VAL_ 1452 IMD_status 0 "IMD_DISABLED" 1 "IMD_OFF" 2 "IMD_SHORTCIRCUIT_VCC" 3 "IMD_OK" 4 "IMD_UNDERVOLTAGE" 5 "IMD_FAST_DETECTION_OK" 6 "IMD_FAST_DETECTION_FAIL" 7 "IMD_HW_ERROR" 8 "IMD_GND_ERROR" 9 "IMD_INSULATION_ERROR" 10 "IMD_INSULATION_WARNING" 11 "IMD_UNKNOWN_REPORTED_STATUS" 12 "IMD_UNQUALIFIED_STATUS" 13 "IMD_HV_CONNECTION_ERROR" ;
VAL_ 1452 Voltage_sensor_status 0 "VOLTAGE_SENSOR_STATUS_DISABLED" 1 "VOLTAGE_SENSOR_STATUS_TIMEOUT" 2 "VOLTAGE_SENSOR_STATUS_ERROR" 3 "VOLTAGE_SENSOR_STATUS_OK" 4 "VOLTAGE_SENSOR_STATUS_DC_LINK_MISMATCH" 5 "VOLTAGE_SENSOR_STATUS_BATTERY_PACK_MISMATCH" 6 "VOLTAGE_SENSOR_STATUS_FUSE_MISMATCH" ;
VAL_ 1453 IMD_status 0 "IMD_DISABLED" 1 "IMD_OFF" 2 "IMD_SHORTCIRCUIT_VCC" 3 "IMD_OK" 4 "IMD_UNDERVOLTAGE" 5 "IMD_FAST_DETECTION_OK" 6 "IMD_FAST_DETECTION_FAIL" 7 "IMD_HW_ERROR" 8 "IMD_GND_ERROR" 9 "IMD_INSULATION_ERROR" 10 "IMD_INSULATION_WARNING" 11 "IMD_UNKNOWN_REPORTED_STATUS" 12 "IMD_UNQUALIFIED_STATUS" 13 "IMD_HV_CONNECTION_ERROR" ;
VAL_ 1453 Voltage_sensor_status 0 "VOLTAGE_SENSOR_STATUS_DISABLED" 1 "VOLTAGE_SENSOR_STATUS_TIMEOUT" 2 "VOLTAGE_SENSOR_STATUS_ERROR" 3 "VOLTAGE_SENSOR_STATUS_OK" 4 "VOLTAGE_SENSOR_STATUS_DC_LINK_MISMATCH" 5 "VOLTAGE_SENSOR_STATUS_BATTERY_PACK_MISMATCH" 6 "VOLTAGE_SENSOR_STATUS_FUSE_MISMATCH" ;
VAL_ 1454 IMD_status 0 "IMD_DISABLED" 1 "IMD_OFF" 2 "IMD_SHORTCIRCUIT_VCC" 3 "IMD_OK" 4 "IMD_UNDERVOLTAGE" 5 "IMD_FAST_DETECTION_OK" 6 "IMD_FAST_DETECTION_FAIL" 7 "IMD_HW_ERROR" 8 "IMD_GND_ERROR" 9 "IMD_INSULATION_ERROR" 10 "IMD_INSULATION_WARNING" 11 "IMD_UNKNOWN_REPORTED_STATUS" 12 "IMD_UNQUALIFIED_STATUS" 13 "IMD_HV_CONNECTION_ERROR" ;
VAL_ 1454 Voltage_sensor_status 0 "VOLTAGE_SENSOR_STATUS_DISABLED" 1 "VOLTAGE_SENSOR_STATUS_TIMEOUT" 2 "VOLTAGE_SENSOR_STATUS_ERROR" 3 "VOLTAGE_SENSOR_STATUS_OK" 4 "VOLTAGE_SENSOR_STATUS_DC_LINK_MISMATCH" 5 "VOLTAGE_SENSOR_STATUS_BATTERY_PACK_MISMATCH" 6 "VOLTAGE_SENSOR_STATUS_FUSE_MISMATCH" ;
VAL_ 1455 IMD_status 0 "IMD_DISABLED" 1 "IMD_OFF" 2 "IMD_SHORTCIRCUIT_VCC" 3 "IMD_OK" 4 "IMD_UNDERVOLTAGE" 5 "IMD_FAST_DETECTION_OK" 6 "IMD_FAST_DETECTION_FAIL" 7 "IMD_HW_ERROR" 8 "IMD_GND_ERROR" 9 "IMD_INSULATION_ERROR" 10 "IMD_INSULATION_WARNING" 11 "IMD_UNKNOWN_REPORTED_STATUS" 12 "IMD_UNQUALIFIED_STATUS" 13 "IMD_HV_CONNECTION_ERROR" ;
VAL_ 1455 Voltage_sensor_status 0 "VOLTAGE_SENSOR_STATUS_DISABLED" 1 "VOLTAGE_SENSOR_STATUS_TIMEOUT" 2 "VOLTAGE_SENSOR_STATUS_ERROR" 3 "VOLTAGE_SENSOR_STATUS_OK" 4 "VOLTAGE_SENSOR_STATUS_DC_LINK_MISMATCH" 5 "VOLTAGE_SENSOR_STATUS_BATTERY_PACK_MISMATCH" 6 "VOLTAGE_SENSOR_STATUS_FUSE_MISMATCH" ;
VAL_ 1472 Cells_unbalanced_flag 0 "IDLE" 1 "ACTIVE" ;
VAL_ 1472 Cells_balancing_flag 0 "IDLE - NO CELLS ARE BALANCING" 1 "ACTIVE - AT LEAST ONE CELLS IS BALANCING" ;
VAL_ 1472 Null_current_flag 0 "IDLE" 1 "ACTIVE" ;
VAL_ 1472 Cells_relaxed_flag 0 "IDLE" 1 "ACTIVE" ;
VAL_ 1473 Cells_unbalanced_flag 0 "IDLE" 1 "ACTIVE" ;
VAL_ 1473 Cells_balancing_flag 0 "IDLE - NO CELLS ARE BALANCING" 1 "ACTIVE - AT LEAST ONE CELLS IS BALANCING" ;
VAL_ 1473 Null_current_flag 0 "IDLE" 1 "ACTIVE" ;
VAL_ 1473 Cells_relaxed_flag 0 "IDLE" 1 "ACTIVE" ;
VAL_ 1474 Cells_unbalanced_flag 0 "IDLE" 1 "ACTIVE" ;
VAL_ 1474 Cells_balancing_flag 0 "IDLE - NO CELLS ARE BALANCING" 1 "ACTIVE - AT LEAST ONE CELLS IS BALANCING" ;
VAL_ 1474 Null_current_flag 0 "IDLE" 1 "ACTIVE" ;
VAL_ 1474 Cells_relaxed_flag 0 "IDLE" 1 "ACTIVE" ;
VAL_ 1475 Cells_unbalanced_flag 0 "IDLE" 1 "ACTIVE" ;
VAL_ 1475 Cells_balancing_flag 0 "IDLE - NO CELLS ARE BALANCING" 1 "ACTIVE - AT LEAST ONE CELLS IS BALANCING" ;
VAL_ 1475 Null_current_flag 0 "IDLE" 1 "ACTIVE" ;
VAL_ 1475 Cells_relaxed_flag 0 "IDLE" 1 "ACTIVE" ;
VAL_ 1476 Cells_unbalanced_flag 0 "IDLE" 1 "ACTIVE" ;
VAL_ 1476 Cells_balancing_flag 0 "IDLE - NO CELLS ARE BALANCING" 1 "ACTIVE - AT LEAST ONE CELLS IS BALANCING" ;
VAL_ 1476 Null_current_flag 0 "IDLE" 1 "ACTIVE" ;
VAL_ 1476 Cells_relaxed_flag 0 "IDLE" 1 "ACTIVE" ;
VAL_ 1477 Cells_unbalanced_flag 0 "IDLE" 1 "ACTIVE" ;
VAL_ 1477 Cells_balancing_flag 0 "IDLE - NO CELLS ARE BALANCING" 1 "ACTIVE - AT LEAST ONE CELLS IS BALANCING" ;
VAL_ 1477 Null_current_flag 0 "IDLE" 1 "ACTIVE" ;
VAL_ 1477 Cells_relaxed_flag 0 "IDLE" 1 "ACTIVE" ;
VAL_ 1478 Cells_unbalanced_flag 0 "IDLE" 1 "ACTIVE" ;
VAL_ 1478 Cells_balancing_flag 0 "IDLE - NO CELLS ARE BALANCING" 1 "ACTIVE - AT LEAST ONE CELLS IS BALANCING" ;
VAL_ 1478 Null_current_flag 0 "IDLE" 1 "ACTIVE" ;
VAL_ 1478 Cells_relaxed_flag 0 "IDLE" 1 "ACTIVE" ;
VAL_ 1479 Cells_unbalanced_flag 0 "IDLE" 1 "ACTIVE" ;
VAL_ 1479 Cells_balancing_flag 0 "IDLE - NO CELLS ARE BALANCING" 1 "ACTIVE - AT LEAST ONE CELLS IS BALANCING" ;
VAL_ 1479 Null_current_flag 0 "IDLE" 1 "ACTIVE" ;
VAL_ 1479 Cells_relaxed_flag 0 "IDLE" 1 "ACTIVE" ;
VAL_ 1480 Cells_unbalanced_flag 0 "IDLE" 1 "ACTIVE" ;
VAL_ 1480 Cells_balancing_flag 0 "IDLE - NO CELLS ARE BALANCING" 1 "ACTIVE - AT LEAST ONE CELLS IS BALANCING" ;
VAL_ 1480 Null_current_flag 0 "IDLE" 1 "ACTIVE" ;
VAL_ 1480 Cells_relaxed_flag 0 "IDLE" 1 "ACTIVE" ;
VAL_ 1481 Cells_unbalanced_flag 0 "IDLE" 1 "ACTIVE" ;
VAL_ 1481 Cells_balancing_flag 0 "IDLE - NO CELLS ARE BALANCING" 1 "ACTIVE - AT LEAST ONE CELLS IS BALANCING" ;
VAL_ 1481 Null_current_flag 0 "IDLE" 1 "ACTIVE" ;
VAL_ 1481 Cells_relaxed_flag 0 "IDLE" 1 "ACTIVE" ;
VAL_ 1482 Cells_unbalanced_flag 0 "IDLE" 1 "ACTIVE" ;
VAL_ 1482 Cells_balancing_flag 0 "IDLE - NO CELLS ARE BALANCING" 1 "ACTIVE - AT LEAST ONE CELLS IS BALANCING" ;
VAL_ 1482 Null_current_flag 0 "IDLE" 1 "ACTIVE" ;
VAL_ 1482 Cells_relaxed_flag 0 "IDLE" 1 "ACTIVE" ;
VAL_ 1483 Cells_unbalanced_flag 0 "IDLE" 1 "ACTIVE" ;
VAL_ 1483 Cells_balancing_flag 0 "IDLE - NO CELLS ARE BALANCING" 1 "ACTIVE - AT LEAST ONE CELLS IS BALANCING" ;
VAL_ 1483 Null_current_flag 0 "IDLE" 1 "ACTIVE" ;
VAL_ 1483 Cells_relaxed_flag 0 "IDLE" 1 "ACTIVE" ;
